VERSION ""

NS_ :

BS_:

BU_: WRCS SRS LECM1 ECUspare6 CIOM CCM

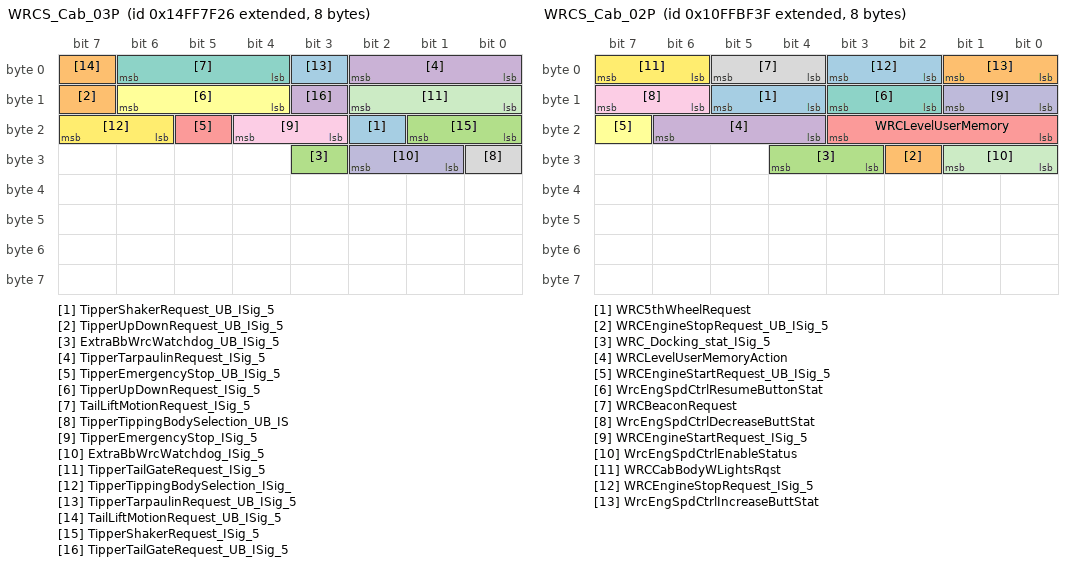
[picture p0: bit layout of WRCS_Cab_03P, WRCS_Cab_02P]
BO_ 2499772198 WRCS_Cab_03P: 8 WRCS
 SG_ TipperShakerRequest_UB_ISig_5 : 18|1@1+ (1,0) [0|0] ""  CIOM
 SG_ TipperUpDownRequest_UB_ISig_5 : 15|1@1+ (1,0) [0|0] ""  CIOM
 SG_ ExtraBbWrcWatchdog_UB_ISig_5 : 27|1@1+ (1,0) [0|0] ""  CIOM
 SG_ TipperTarpaulinRequest_ISig_5 : 0|3@1+ (1,0) [0|0] ""  CIOM
 SG_ TipperEmergencyStop_UB_ISig_5 : 21|1@1+ (1,0) [0|0] ""  CIOM
 SG_ TipperUpDownRequest_ISig_5 : 12|3@1+ (1,0) [0|0] ""  CIOM
 SG_ TailLiftMotionRequest_ISig_5 : 4|3@1+ (1,0) [0|0] ""  CIOM
 SG_ TipperTippingBodySelection_UB_IS : 24|1@1+ (1,0) [0|0] ""  CIOM
 SG_ TipperEmergencyStop_ISig_5 : 19|2@1+ (1,0) [0|0] ""  CIOM
 SG_ ExtraBbWrcWatchdog_ISig_5 : 25|2@1+ (1,0) [0|0] ""  CIOM
 SG_ TipperTailGateRequest_ISig_5 : 8|3@1+ (1,0) [0|0] ""  CIOM
 SG_ TipperTippingBodySelection_ISig_ : 22|2@1+ (1,0) [0|0] ""  CIOM
 SG_ TipperTarpaulinRequest_UB_ISig_5 : 3|1@1+ (1,0) [0|0] ""  CIOM
 SG_ TailLiftMotionRequest_UB_ISig_5 : 7|1@1+ (1,0) [0|0] ""  CIOM
 SG_ TipperShakerRequest_ISig_5 : 16|2@1+ (1,0) [0|0] ""  CIOM
 SG_ TipperTailGateRequest_UB_ISig_5 : 11|1@1+ (1,0) [0|0] ""  CIOM

BO_ 2432679743 WRCS_Cab_02P: 8 WRCS
 SG_ WRC5thWheelRequest : 12|2@1+ (1,0) [0|0] ""  CIOM
 SG_ WRCEngineStopRequest_UB_ISig_5 : 26|1@1+ (1,0) [0|0] ""  CIOM
 SG_ WRC_Docking_stat_ISig_5 : 27|2@1+ (1,0) [0|0] ""  CIOM
 SG_ WRCLevelUserMemoryAction : 20|3@1+ (1,0) [0|0] ""  CIOM
 SG_ WRCLevelUserMemory : 16|4@1+ (1,0) [0|0] ""  CIOM
 SG_ WRCEngineStartRequest_UB_ISig_5 : 23|1@1+ (1,0) [0|0] ""  CIOM
 SG_ WrcEngSpdCtrlResumeButtonStat : 10|2@1+ (1,0) [0|0] ""  CIOM
 SG_ WRCBeaconRequest : 4|2@1+ (1,0) [0|0] ""  CIOM
 SG_ WrcEngSpdCtrlDecreaseButtStat : 14|2@1+ (1,0) [0|0] ""  CIOM
 SG_ WRCEngineStartRequest_ISig_5 : 8|2@1+ (1,0) [0|0] ""  CIOM
 SG_ WrcEngSpdCtrlEnableStatus : 24|2@1+ (1,0) [0|0] ""  CIOM
 SG_ WRCCabBodyWLightsRqst : 6|2@1+ (1,0) [0|0] ""  CIOM
 SG_ WRCEngineStopRequest_ISig_5 : 2|2@1+ (1,0) [0|0] ""  CIOM
 SG_ WrcEngSpdCtrlIncreaseButtStat : 0|2@1+ (1,0) [0|0] ""  CIOM

BO_ 2365554559 WRCS_Cab_01P: 8 WRCS
 SG_ WrcPto1ButtonStatus : 2|2@1+ (1,0) [0|0] ""  CIOM
 SG_ ECSStandByReqWRC : 35|3@1+ (1,0) [0|0] ""  CIOM
 SG_ WRCCraneRequest : 22|2@1+ (1,0) [0|0] ""  CIOM
 SG_ WRCUnlockButtonStatus : 4|2@1+ (1,0) [0|0] ""  CIOM
 SG_ WRCRollRequest : 32|3@1+ (1,0) [0|0] ""  CIOM
 SG_ WRCAux3Request : 14|2@1+ (1,0) [0|0] ""  CIOM
 SG_ WRCAux2Request : 0|2@1+ (1,0) [0|0] ""  CIOM
 SG_ WrcPto3ButtonStatus : 20|2@1+ (1,0) [0|0] ""  CIOM
 SG_ WRCLevelAdjustmentAction : 44|4@1+ (1,0) [0|0] ""  CIOM
 SG_ WRCAux4Request : 10|2@1+ (1,0) [0|0] ""  CIOM
 SG_ WRCAux5Request : 8|2@1+ (1,0) [0|0] ""  CIOM
 SG_ WRCAux6Request : 16|2@1+ (1,0) [0|0] ""  CIOM
 SG_ WRCSideReverseWorkingRequest : 6|2@1+ (1,0) [0|0] ""  CIOM
 SG_ WrcPto2ButtonStatus : 12|2@1+ (1,0) [0|0] ""  CIOM
 SG_ WRCTailLiftRequest : 24|2@1+ (1,0) [0|0] ""  CIOM
 SG_ WrcPto4ButtonStatus : 30|2@1+ (1,0) [0|0] ""  CIOM
 SG_ WRCLevelAdjustmentStroke : 41|3@1+ (1,0) [0|0] ""  CIOM
 SG_ WRCLevelAdjustmentAxles : 38|3@1+ (1,0) [0|0] ""  CIOM
 SG_ WRCAirSuspensionStopRequest : 28|2@1+ (1,0) [0|0] ""  CIOM
 SG_ WRCAux1Request : 26|2@1+ (1,0) [0|0] ""  CIOM
 SG_ WRCLockButtonStatus : 18|2@1+ (1,0) [0|0] ""  CIOM

BO_ 2671902706 TesterFuncDiagMsg_Cab: 8 CIOM
 SG_ FuncDiagDataTester_ISig_5 : 0|64@1+ (1,0) [0|0] ""  SRS,CCM,LECM1,WRCS

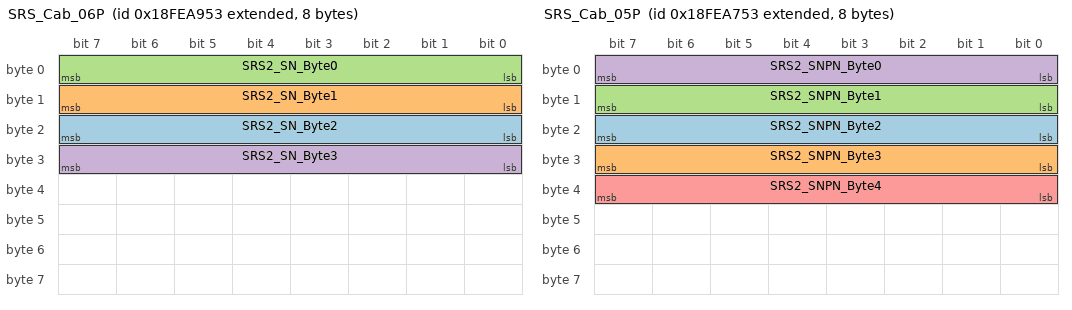
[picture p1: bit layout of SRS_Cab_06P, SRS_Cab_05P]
BO_ 2566826323 SRS_Cab_06P: 8 SRS
 SG_ SRS2_SN_Byte2 : 16|8@1+ (1,0) [0|0] ""  CIOM
 SG_ SRS2_SN_Byte1 : 8|8@1+ (1,0) [0|0] ""  CIOM
 SG_ SRS2_SN_Byte0 : 0|8@1+ (1,0) [0|0] ""  CIOM
 SG_ SRS2_SN_Byte3 : 24|8@1+ (1,0) [0|0] ""  CIOM

BO_ 2566825811 SRS_Cab_05P: 8 SRS
 SG_ SRS2_SNPN_Byte2 : 16|8@1+ (1,0) [0|0] ""  CIOM
 SG_ SRS2_SNPN_Byte3 : 24|8@1+ (1,0) [0|0] ""  CIOM
 SG_ SRS2_SNPN_Byte1 : 8|8@1+ (1,0) [0|0] ""  CIOM
 SG_ SRS2_SNPN_Byte0 : 0|8@1+ (1,0) [0|0] ""  CIOM
 SG_ SRS2_SNPN_Byte4 : 32|8@1+ (1,0) [0|0] ""  CIOM

BO_ 2516232019 SRS_Cab_04P: 8 SRS
 SG_ DiagInfoSRS2 : 0|7@1+ (1,0) [0|127] "NotApplicable"  CIOM

BO_ 2499788607 SRS_Cab_03P: 8 SRS
 SG_ ECUVIN_rqst : 0|1@1+ (1,0) [0|0] ""  CIOM

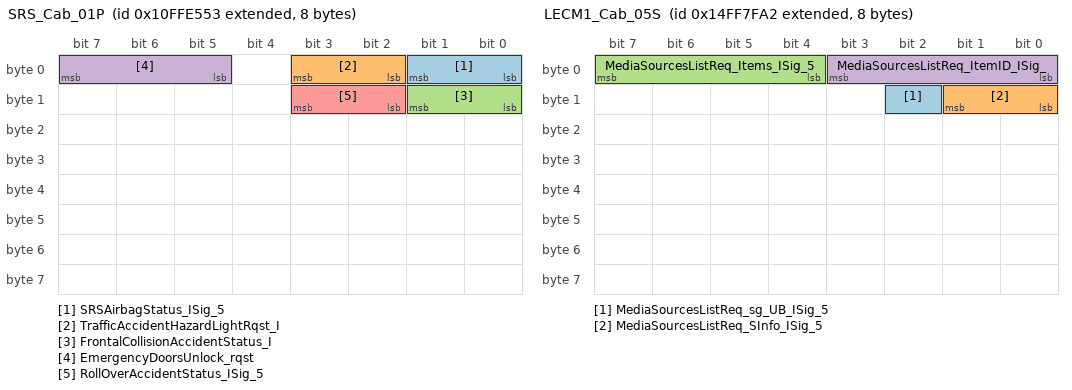
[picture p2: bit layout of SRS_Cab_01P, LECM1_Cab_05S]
BO_ 2432689491 SRS_Cab_01P: 8 SRS
 SG_ SRSAirbagStatus_ISig_5 : 0|2@1+ (1,0) [0|0] ""  CIOM
 SG_ TrafficAccidentHazardLightRqst_I : 2|2@1+ (1,0) [0|0] ""  CIOM
 SG_ FrontalCollisionAccidentStatus_I : 8|2@1+ (1,0) [0|0] ""  CIOM
 SG_ EmergencyDoorsUnlock_rqst : 5|3@1+ (1,0) [0|0] ""  CIOM
 SG_ RollOverAccidentStatus_ISig_5 : 10|2@1+ (1,0) [0|0] ""  CIOM

BO_ 2658975757 SRSDiagPSTesterTx4_Cab: 8 SRS
 SG_ SRSDiagPSTesterTx4 : 0|64@1+ (1,0) [0|0] "" Vector__XXX

BO_ 2658975756 SRSDiagPSTesterTx3_Cab: 8 SRS
 SG_ SRSDiagPSTesterTx3 : 0|64@1+ (1,0) [0|0] "" Vector__XXX

BO_ 2658975755 SRSDiagPSTesterTx2_Cab: 8 SRS
 SG_ SRSDiagPSTesterTx2 : 0|64@1+ (1,0) [0|0] "" Vector__XXX

BO_ 2658967560 SRSDiagPSTesterTx1_Cab: 8 SRS
 SG_ SRSDiagPSTesterTx1 : 0|64@1+ (1,0) [0|0] "" Vector__XXX

BO_ 2658967559 SRSDiagPSTesterRx1_Cab: 8 Vector__XXX
 SG_ SRSDiagPSTesterRx1 : 0|64@1+ (1,0) [0|0] ""  SRS

BO_ 2671833762 PhysDiagRespMsg_F2_A2_Cab: 8 LECM1
 SG_ PhysDiagRespSig_F2_A2_ISig_5 : 0|64@1+ (1,0) [0|0] ""  CIOM

BO_ 2671833752 PhysDiagRespMsg_F2_98_Cab: 8 CCM
 SG_ PhysDiagRespSig_F2_98_ISig_5 : 0|64@1+ (1,0) [0|0] ""  CIOM

BO_ 2671833683 PhysDiagRespMsg_F2_53_Cab: 8 SRS
 SG_ PhysDiagRespSig_F2_53_ISig_5 : 0|64@1+ (1,0) [0|0] ""  CIOM

BO_ 2671833638 PhysDiagRespMsg_F2_26_Cab: 8 WRCS
 SG_ PhysDiagRespSig_F2_26_ISig_5 : 0|64@1+ (1,0) [0|0] ""  CIOM

BO_ 2564485459 PhysDiagRespMsg_F1_53_Cab: 8 SRS
 SG_ PhysDiagRespSig_F1_53_ISig_5 : 0|64@1+ (1,0) [0|0] ""  CIOM

BO_ 2671813362 PhysDiagReqMsg_A2_F2_Cab: 8 CIOM
 SG_ PhysDiagReqSig_A2_F2_ISig_5 : 0|64@1+ (1,0) [0|0] ""  LECM1

BO_ 2671810802 PhysDiagReqMsg_98_F2_Cab: 8 CIOM
 SG_ PhysDiagReqSig_98_F2_ISig_5 : 0|64@1+ (1,0) [0|0] ""  CCM

BO_ 2671793138 PhysDiagReqMsg_53_F2_Cab: 8 CIOM
 SG_ PhysDiagReqSig_53_F2_ISig_5 : 0|64@1+ (1,0) [0|0] ""  SRS

BO_ 2564445169 PhysDiagReqMsg_53_F1_Cab: 8 CIOM
 SG_ PhysDiagReqSig_53_F1_ISig_5 : 0|64@1+ (1,0) [0|0] ""  SRS

BO_ 2671781618 PhysDiagReqMsg_26_F2_Cab: 8 CIOM
 SG_ PhysDiagReqSig_26_F2_ISig_5 : 0|64@1+ (1,0) [0|0] ""  WRCS

BO_ 2633990182 NmAsr_WRCS_Cab: 1 WRCS

BO_ 2633990227 NmAsr_SRS_Cab: 1 SRS

BO_ 2633990306 NmAsr_LECM1_Cab: 1 LECM1

BO_ 2633990208 NmAsr_CIOM_Cab: 1 CIOM

BO_ 2633990296 NmAsr_CCM_Cab: 1 CCM

BO_ 2499772322 LECM1_Cab_05S: 8 LECM1
 SG_ MediaSourcesListReq_sg_UB_ISig_5 : 10|1@1+ (1,0) [0|0] ""  CIOM
 SG_ MediaSourcesListReq_SInfo_ISig_5 : 8|2@1+ (1,0) [0|0] ""  CIOM
 SG_ MediaSourcesListReq_Items_ISig_5 : 4|4@1+ (1,0) [0|0] ""  CIOM
 SG_ MediaSourcesListReq_ItemID_ISig_ : 0|4@1+ (1,0) [0|0] ""  CIOM

BO_ 2489730210 LECM1_Cab_04P: 8 LECM1
 SG_ BunkH1AudioSrcSem_rqst_ISig_5 : 0|4@1+ (1,0) [0|0] ""  CIOM

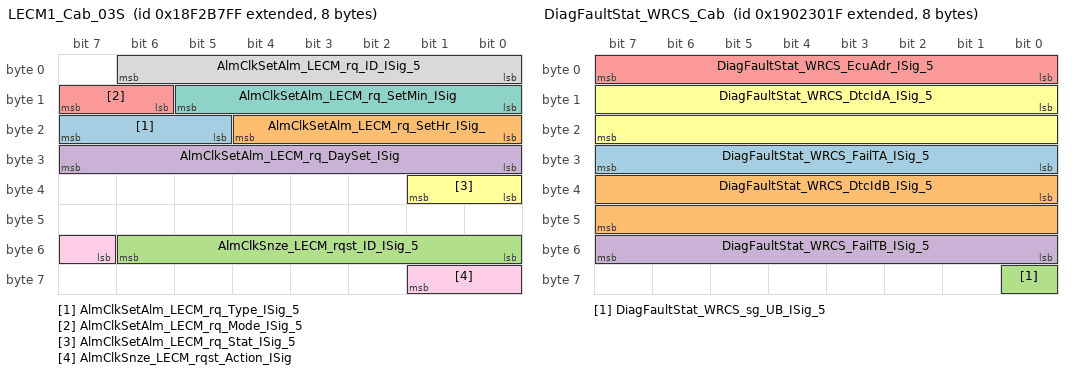
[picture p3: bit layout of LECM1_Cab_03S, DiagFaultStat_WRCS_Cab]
BO_ 2566043647 LECM1_Cab_03S: 8 LECM1
 SG_ AlmClkSetAlm_LECM_rq_Type_ISig_5 : 21|3@1+ (1,0) [0|0] ""  CIOM
 SG_ AlmClkSetAlm_LECM_rq_SetHr_ISig_ : 16|5@1+ (1,0) [0|31] "h"  CIOM
 SG_ AlmClkSnze_LECM_rqst_ID_ISig_5 : 48|7@1+ (1,0) [0|0] ""  CIOM
 SG_ AlmClkSetAlm_LECM_rq_DaySet_ISig : 24|8@1+ (1,0) [0|255] ""  CIOM
 SG_ AlmClkSetAlm_LECM_rq_Mode_ISig_5 : 14|2@1+ (1,0) [0|0] ""  CIOM
 SG_ AlmClkSetAlm_LECM_rq_Stat_ISig_5 : 32|2@1+ (1,0) [0|0] ""  CIOM
 SG_ AlmClkSetAlm_LECM_rq_SetMin_ISig : 8|6@1+ (1,0) [0|63] "min"  CIOM
 SG_ AlmClkSetAlm_LECM_rq_ID_ISig_5 : 0|7@1+ (1,0) [0|0] ""  CIOM
 SG_ AlmClkSnze_LECM_rqst_Action_ISig : 55|3@1+ (1,0) [0|0] ""  CIOM

BO_ 2432693154 LECM1_Cab_02P: 8 LECM1
 SG_ BunkH1PowerWinOpenDSBtn_stat_UB_ : 58|1@1+ (1,0) [0|0] ""  CIOM
 SG_ BunkH1RoofhatchOpenBtn_Stat : 32|2@1+ (1,0) [0|0] ""  CIOM
 SG_ BunkH1IntLghtActvnBtn_stat : 6|2@1+ (1,0) [0|0] ""  CIOM
 SG_ BunkH1TempDec_ButtonStatus : 24|2@1+ (1,0) [0|0] ""  CCM
 SG_ BunkH1IntLghtDirAccsUpBtn_stat : 46|2@1+ (1,0) [0|0] ""  CIOM
 SG_ BunkH1AudioSource_rqst2_ISig_5 : 60|4@1+ (1,0) [0|0] ""  CIOM
 SG_ BunkH1AudioOnOff_ButtonStatus_IS : 2|2@1+ (1,0) [0|0] ""  CIOM
 SG_ BunkH1RoofhatchCloseBtn_Stat : 28|2@1+ (1,0) [0|0] ""  CIOM
 SG_ BunkH1VolumeUp_ButtonStatus_ISig : 30|2@1+ (1,0) [0|0] ""  CIOM
 SG_ BunkH1PowerWinClosePSBtn_stat_UB : 55|1@1+ (1,0) [0|0] ""  CIOM
 SG_ BunkH1PowerWinCloseDSBtn_stat_IS : 16|2@1+ (1,0) [0|0] ""  CIOM
 SG_ BunkH1Prev_ButtonStatus_ISig_5 : 0|2@1+ (1,0) [0|0] ""  CIOM
 SG_ BunkH1UnlockButtonStatus : 4|2@1+ (1,0) [0|0] ""  CIOM
 SG_ BunkH1VolumeDown_ButtonStatus_IS : 18|2@1+ (1,0) [0|0] ""  CIOM
 SG_ BunkH1ParkHeaterTimer2_cmd : 40|3@1+ (1,0) [0|0] ""  CCM
 SG_ BunkH1PowerWinOpenPSBtn_stat_UB_ : 59|1@1+ (1,0) [0|0] ""  CIOM
 SG_ BunkH1PowerWinOpenDSBtn_stat_ISi : 8|2@1+ (1,0) [0|0] ""  CIOM
 SG_ BunkH1ParkHeater_ButtonStatus : 14|2@1+ (1,0) [0|0] ""  CCM
 SG_ BunkH1ParkHeaterTimer3_cmd : 36|3@1+ (1,0) [0|0] ""  CCM
 SG_ BunkH1AudioSource_rqst_ISig_5 : 48|3@1+ (1,0) [0|0] ""  CIOM
 SG_ BunkH1Mute_ButtonStatus_ISig_5 : 56|2@1+ (1,0) [0|0] ""  CIOM
 SG_ BunkH1IntLghtDirAccsDnBtn_stat : 22|2@1+ (1,0) [0|0] ""  CIOM
 SG_ BunkH1LockButtonStatus : 10|2@1+ (1,0) [0|0] ""  CIOM
 SG_ BunkH1ParkHeaterTimer1_cmd : 43|3@1+ (1,0) [0|0] ""  CCM
 SG_ BnkH1IntLghtMMenu_stat_IL_Mode : 51|3@1+ (1,0) [0|0] ""  CIOM
 SG_ BunkH1Next_ButtonStatus_ISig_5 : 20|2@1+ (1,0) [0|0] ""  CIOM
 SG_ BunkH1PowerWinCloseDSBtn_stat_UB : 39|1@1+ (1,0) [0|0] ""  CIOM
 SG_ BnkH1IntLghtMMenu_stat_EventFlag : 54|1@1+ (1,0) [0|0] ""  CIOM
 SG_ BunkH1PowerWinOpenPSBtn_stat_ISi : 26|2@1+ (1,0) [0|0] ""  CIOM
 SG_ BunkH1PowerWinClosePSBtn_stat_IS : 34|2@1+ (1,0) [0|0] ""  CIOM
 SG_ BunkH1TempInc_ButtonStatus : 12|2@1+ (1,0) [0|0] ""  CCM

BO_ 2671902708 IntTesterTGW2FuncDiagMsg_Cab: 8 CIOM
 SG_ FuncDiagDataIntTesterTGW2_ISig_5 : 0|64@1+ (1,0) [0|0] ""  LECM1,SRS,CCM,WRCS

BO_ 2671964834 DiagUUDTRespMsg1_F2_A2_Cab: 8 LECM1
 SG_ DiagUUDTRespSig_F2_A2_ISig_5 : 0|64@1+ (1,0) [0|0] ""  CIOM

BO_ 2671964824 DiagUUDTRespMsg1_F2_98_Cab: 8 CCM
 SG_ DiagUUDTRespSig_F2_98_ISig_5 : 0|64@1+ (1,0) [0|0] ""  CIOM

BO_ 2671964755 DiagUUDTRespMsg1_F2_53_Cab: 8 SRS
 SG_ DiagUUDTRespSig_F2_53_ISig_5 : 0|64@1+ (1,0) [0|0] ""  CIOM

BO_ 2671964710 DiagUUDTRespMsg1_F2_26_Cab: 8 WRCS
 SG_ DiagUUDTRespSig_F2_26_ISig_5 : 0|64@1+ (1,0) [0|0] ""  CIOM

BO_ 2671834274 DiagRespMsgIntTGW2_F4_A2_Cab: 8 LECM1
 SG_ InternalTesterDiagSig_F4_A2_ISig : 0|64@1+ (1,0) [0|0] ""  CIOM

BO_ 2671834264 DiagRespMsgIntTGW2_F4_98_Cab: 8 CCM
 SG_ InternalTesterDiagSig_F4_98_ISig : 0|64@1+ (1,0) [0|0] ""  CIOM

BO_ 2671834195 DiagRespMsgIntTGW2_F4_53_Cab: 8 SRS
 SG_ InternalTesterDiagSig_F4_53_ISig : 0|64@1+ (1,0) [0|0] ""  CIOM

BO_ 2671834150 DiagRespMsgIntTGW2_F4_26_Cab: 8 WRCS
 SG_ InternalTesterDiagSig_F4_26_ISig : 0|64@1+ (1,0) [0|0] ""  CIOM

BO_ 2671834018 DiagRespMsgIntHMIIOM_F3_A2_Cab: 8 LECM1
 SG_ InternalTesterDiagSig_F3_A2_ISig : 0|64@1+ (1,0) [0|0] ""  CIOM

BO_ 2671834008 DiagRespMsgIntHMIIOM_F3_98_Cab: 8 CCM
 SG_ InternalTesterDiagSig_F3_98_ISig : 0|64@1+ (1,0) [0|0] ""  CIOM

BO_ 2671833939 DiagRespMsgIntHMIIOM_F3_53_Cab: 8 SRS
 SG_ InternalTesterDiagSig_F3_53_ISig : 0|64@1+ (1,0) [0|0] ""  CIOM

BO_ 2671833894 DiagRespMsgIntHMIIOM_F3_26_Cab: 8 WRCS
 SG_ InternalTesterDiagSig_F3_26_ISig : 0|64@1+ (1,0) [0|0] ""  CIOM

BO_ 2671813364 DiagReqMsgIntTGW2_A2_F4_Cab: 8 CIOM
 SG_ InternalTesterDiagSig_A2_F4_ISig : 0|64@1+ (1,0) [0|0] ""  LECM1

BO_ 2671810804 DiagReqMsgIntTGW2_98_F4_Cab: 8 CIOM
 SG_ InternalTesterDiagSig_98_F4_ISig : 0|64@1+ (1,0) [0|0] ""  CCM

BO_ 2671793140 DiagReqMsgIntTGW2_53_F4_Cab: 8 CIOM
 SG_ InternalTesterDiagSig_53_F4_ISig : 0|64@1+ (1,0) [0|0] ""  SRS

BO_ 2671781620 DiagReqMsgIntTGW2_26_F4_Cab: 8 CIOM
 SG_ InternalTesterDiagSig_26_F4_ISig : 0|64@1+ (1,0) [0|0] ""  WRCS

BO_ 2671813363 DiagReqMsgIntHMIIOM_A2_F3_Cab: 8 CIOM
 SG_ InternalTesterDiagSig_A2_F3_ISig : 0|64@1+ (1,0) [0|0] ""  LECM1

BO_ 2671810803 DiagReqMsgIntHMIIOM_98_F3_Cab: 8 CIOM
 SG_ InternalTesterDiagSig_98_F3_ISig : 0|64@1+ (1,0) [0|0] ""  CCM

BO_ 2671793139 DiagReqMsgIntHMIIOM_53_F3_Cab: 8 CIOM
 SG_ InternalTesterDiagSig_53_F3_ISig : 0|64@1+ (1,0) [0|0] ""  SRS

BO_ 2671781619 DiagReqMsgIntHMIIOM_26_F3_Cab: 8 CIOM
 SG_ InternalTesterDiagSig_26_F3_ISig : 0|64@1+ (1,0) [0|0] ""  WRCS

BO_ 2567057439 DiagFaultStat_WRCS_Cab: 8 WRCS
 SG_ DiagFaultStat_WRCS_FailTA_ISig_5 : 24|8@1+ (1,0) [0|255] ""  CIOM
 SG_ DiagFaultStat_WRCS_DtcIdB_ISig_5 : 32|16@1+ (1,0) [0|65535] ""  CIOM
 SG_ DiagFaultStat_WRCS_sg_UB_ISig_5 : 56|1@1+ (1,0) [0|0] ""  CIOM
 SG_ DiagFaultStat_WRCS_FailTB_ISig_5 : 48|8@1+ (1,0) [0|255] ""  CIOM
 SG_ DiagFaultStat_WRCS_EcuAdr_ISig_5 : 0|8@1+ (1,0) [0|255] ""  CIOM
 SG_ DiagFaultStat_WRCS_DtcIdA_ISig_5 : 8|16@1+ (1,0) [0|65535] ""  CIOM

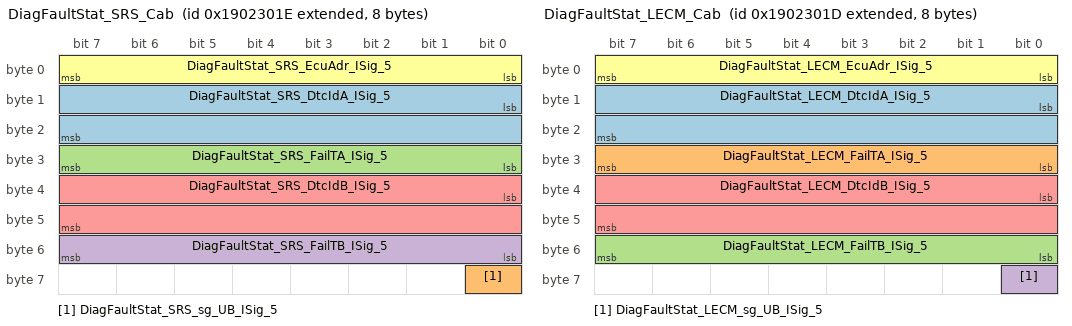
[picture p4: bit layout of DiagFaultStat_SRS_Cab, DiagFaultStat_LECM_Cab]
BO_ 2567057438 DiagFaultStat_SRS_Cab: 8 SRS
 SG_ DiagFaultStat_SRS_DtcIdA_ISig_5 : 8|16@1+ (1,0) [0|65535] ""  CIOM
 SG_ DiagFaultStat_SRS_sg_UB_ISig_5 : 56|1@1+ (1,0) [0|0] ""  CIOM
 SG_ DiagFaultStat_SRS_FailTA_ISig_5 : 24|8@1+ (1,0) [0|255] ""  CIOM
 SG_ DiagFaultStat_SRS_FailTB_ISig_5 : 48|8@1+ (1,0) [0|255] ""  CIOM
 SG_ DiagFaultStat_SRS_DtcIdB_ISig_5 : 32|16@1+ (1,0) [0|65535] ""  CIOM
 SG_ DiagFaultStat_SRS_EcuAdr_ISig_5 : 0|8@1+ (1,0) [0|255] ""  CIOM

BO_ 2567057437 DiagFaultStat_LECM_Cab: 8 LECM1
 SG_ DiagFaultStat_LECM_DtcIdA_ISig_5 : 8|16@1+ (1,0) [0|65535] ""  CIOM
 SG_ DiagFaultStat_LECM_FailTA_ISig_5 : 24|8@1+ (1,0) [0|255] ""  CIOM
 SG_ DiagFaultStat_LECM_FailTB_ISig_5 : 48|8@1+ (1,0) [0|255] ""  CIOM
 SG_ DiagFaultStat_LECM_sg_UB_ISig_5 : 56|1@1+ (1,0) [0|0] ""  CIOM
 SG_ DiagFaultStat_LECM_DtcIdB_ISig_5 : 32|16@1+ (1,0) [0|65535] ""  CIOM
 SG_ DiagFaultStat_LECM_EcuAdr_ISig_5 : 0|8@1+ (1,0) [0|255] ""  CIOM

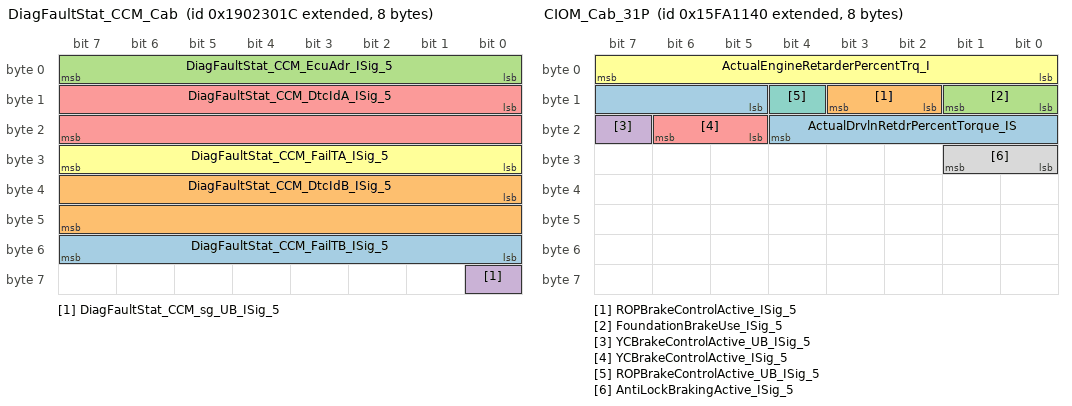
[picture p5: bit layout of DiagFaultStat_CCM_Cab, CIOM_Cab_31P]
BO_ 2567057436 DiagFaultStat_CCM_Cab: 8 CCM
 SG_ DiagFaultStat_CCM_FailTB_ISig_5 : 48|8@1+ (1,0) [0|255] ""  CIOM
 SG_ DiagFaultStat_CCM_DtcIdB_ISig_5 : 32|16@1+ (1,0) [0|65535] ""  CIOM
 SG_ DiagFaultStat_CCM_EcuAdr_ISig_5 : 0|8@1+ (1,0) [0|255] ""  CIOM
 SG_ DiagFaultStat_CCM_sg_UB_ISig_5 : 56|1@1+ (1,0) [0|0] ""  CIOM
 SG_ DiagFaultStat_CCM_DtcIdA_ISig_5 : 8|16@1+ (1,0) [0|65535] ""  CIOM
 SG_ DiagFaultStat_CCM_FailTA_ISig_5 : 24|8@1+ (1,0) [0|255] ""  CIOM

BO_ 2634020435 Debug6_SRS_Cab: 8 SRS
 SG_ Debug_6_SRS : 0|64@1+ (1,0) [0|0] "" Vector__XXX

BO_ 2634020514 Debug6_LECM_Cab: 8 LECM1
 SG_ Debug_6_LECM : 0|64@1+ (1,0) [0|0] "" Vector__XXX

BO_ 2634020504 Debug6_CCM_Cab: 8 CCM
 SG_ Debug_6_CCM : 0|64@1+ (1,0) [0|0] "" Vector__XXX

BO_ 2634020179 Debug5_SRS_Cab: 8 SRS
 SG_ Debug_5_SRS : 0|64@1+ (1,0) [0|0] "" Vector__XXX

BO_ 2634020258 Debug5_LECM_Cab: 8 LECM1
 SG_ Debug_5_LECM : 0|64@1+ (1,0) [0|0] "" Vector__XXX

BO_ 2634020248 Debug5_CCM_Cab: 8 CCM
 SG_ Debug_5_CCM : 0|64@1+ (1,0) [0|0] "" Vector__XXX

BO_ 2634019923 Debug4_SRS_Cab: 8 SRS
 SG_ Debug_4_SRS : 0|64@1+ (1,0) [0|0] "" Vector__XXX

BO_ 2634020002 Debug4_LECM_Cab: 8 LECM1
 SG_ Debug_4_LECM : 0|64@1+ (1,0) [0|0] "" Vector__XXX

BO_ 2634019992 Debug4_CCM_Cab: 8 CCM
 SG_ Debug_4_CCM : 0|64@1+ (1,0) [0|0] "" Vector__XXX

BO_ 2634019667 Debug3_SRS_Cab: 8 SRS
 SG_ Debug_3_SRS : 0|64@1+ (1,0) [0|0] "" Vector__XXX

BO_ 2634019746 Debug3_LECM_Cab: 8 LECM1
 SG_ Debug_3_LECM : 0|64@1+ (1,0) [0|0] "" Vector__XXX

BO_ 2634019736 Debug3_CCM_Cab: 8 Vector__XXX
 SG_ Debug_3_CCM : 0|64@1+ (1,0) [0|0] ""  CCM

BO_ 2634019411 Debug2_SRS_Cab: 8 SRS
 SG_ Debug_2_SRS : 0|64@1+ (1,0) [0|0] "" Vector__XXX

BO_ 2634019490 Debug2_LECM_Cab: 8 LECM1
 SG_ Debug_2_LECM : 0|64@1+ (1,0) [0|0] "" Vector__XXX

BO_ 2634019480 Debug2_CCM_Cab: 8 Vector__XXX
 SG_ Debug_2_CCM : 0|64@1+ (1,0) [0|0] ""  CCM

BO_ 2634019155 Debug1_SRS_Cab: 8 Vector__XXX
 SG_ Debug_1_SRS : 0|64@1+ (1,0) [0|0] ""  SRS

BO_ 2634019234 Debug1_LECM_Cab: 8 Vector__XXX
 SG_ Debug_1_LECM : 0|64@1+ (1,0) [0|0] ""  LECM1

BO_ 2634019224 Debug1_CCM_Cab: 8 Vector__XXX
 SG_ Debug_1_CCM : 0|64@1+ (1,0) [0|0] ""  CCM

BO_ 2566357313 CIOM_Cab_34P_FCM: 8 SRS
 SG_ CIOM_Cab_34P_FCS : 0|64@1+ (1,0) [0|0] ""  CIOM

BO_ 2566357312 CIOM_Cab_34P: 21 CIOM
 SG_ GPSData_VehSpeed_ISig_5 : 128|16@1+ (0.00390625,0) [0|255.99609375] "Km_per_h"  SRS
 SG_ GPSData_HDOP_ISig_5 : 112|16@1+ (0.01,0) [0|655.35] ""  SRS
 SG_ GPSData_Direction_ISig_5 : 96|16@1+ (0.0078125,0) [0|511.9921875] "deg"  SRS
 SG_ GPSData_Longitude_ISig_5 : 0|32@1+ (1E-007,-210) [-210|219.4967295] "deg"  SRS
 SG_ GPSData_AntennaStat_ISig_5 : 160|3@1+ (1,0) [0|0] ""  SRS
 SG_ GPSData_Latitude_ISig_5 : 32|32@1+ (1E-007,-210) [-210|219.4967295] "deg"  SRS
 SG_ GPSData_sg_UB_ISig_5 : 163|1@1+ (1,0) [0|1] ""  SRS
 SG_ GPSData_Altitude_ISig_5 : 144|16@1+ (0.125,-2500) [-2500|5691.875] "m"  SRS
 SG_ GPSData_Time_ISig_5 : 64|32@1+ (1,0) [0|4294967295] "s"  SRS

BO_ 2432680000 CIOM_Cab_33P: 8 CIOM
 SG_ BrakePedalPosition_ISig_5 : 0|8@1+ (0.4,0) [0|102] "Percent"  SRS
 SG_ SteeringWheelAngle_ISig_5 : 8|16@1+ (0.0009765625,-31.374) [-31.374|32.6250234375] "rad"  SRS

BO_ 2432647232 CIOM_Cab_32P: 8 CIOM
 SG_ CM_Status_ISig_5 : 0|3@1+ (1,0) [0|0] ""  SRS

BO_ 2516193600 CIOM_Cab_31P: 8 CIOM
 SG_ ActualDrvlnRetdrPercentTorque_IS : 13|8@1+ (1,-125) [-125|130] "Percent"  SRS
 SG_ ROPBrakeControlActive_ISig_5 : 10|2@1+ (1,0) [0|0] ""  SRS
 SG_ FoundationBrakeUse_ISig_5 : 8|2@1+ (1,0) [0|0] ""  SRS
 SG_ YCBrakeControlActive_UB_ISig_5 : 23|1@1+ (1,0) [0|0] ""  SRS
 SG_ YCBrakeControlActive_ISig_5 : 21|2@1+ (1,0) [0|0] ""  SRS
 SG_ ActualEngineRetarderPercentTrq_I : 0|8@1+ (1,-125) [-125|130] "Percent"  SRS
 SG_ ROPBrakeControlActive_UB_ISig_5 : 12|1@1+ (1,0) [0|0] ""  SRS
 SG_ AntiLockBrakingActive_ISig_5 : 24|2@1+ (1,0) [0|0] ""  SRS

BO_ 2566357057 CIOM_Cab_30S_FCM: 8 LECM1
 SG_ CIOM_Cab_30S_FCS : 0|64@1+ (1,0) [0|0] ""  CIOM

BO_ 2566357056 CIOM_Cab_30S: 36 CIOM
 SG_ SEM_DisplayText_stat_ISig_5 : 0|288@1+ (1,0) [0|0] ""  LECM1

BO_ 2432679745 CIOM_Cab_29S_FCM: 8 LECM1
 SG_ CIOM_Cab_29S_FCS : 0|64@1+ (1,0) [0|0] ""  CIOM

BO_ 2432679744 CIOM_Cab_29S: 98 CIOM
 SG_ MediaSourcesListRsp_SrcAttrib_IS : 392|384@1+ (1,0) [0|0] ""  LECM1
 SG_ MediaSourcesListRsp_ItemID_ISig_ : 776|4@1+ (1,0) [0|0] ""  LECM1
 SG_ MediaSourcesListRsp_Name_ISig_5 : 8|384@1+ (1,0) [0|0] ""  LECM1
 SG_ MediaSourcesListRsp_SInfo_ISig_5 : 780|2@1+ (1,0) [0|0] ""  LECM1
 SG_ MediaSourcesListRsp_PCI_ISig_5 : 0|8@1+ (1,0) [0|255] ""  LECM1
 SG_ MediaSourcesListRsp_sg_UB_ISig_5 : 782|1@1+ (1,0) [0|0] ""  LECM1

BO_ 2432646976 CIOM_Cab_28S: 8 CIOM
 SG_ MediaSourcesListNPRsp_ISig_5 : 0|8@1+ (1,0) [0|255] ""  LECM1
 SG_ MediaSourcesListNPRsp_UB_ISig_5 : 8|1@1+ (1,0) [0|0] ""  LECM1

BO_ 2493989952 CIOM_Cab_27P: 8 CIOM
 SG_ SEMMediaSourceAvail_Source07_ISi : 7|1@1+ (1,0) [0|0] ""  LECM1
 SG_ SEMMediaSourceAvail_Source06_ISi : 6|1@1+ (1,0) [0|0] ""  LECM1
 SG_ SEMMediaSourceAvail_Source08_ISi : 8|1@1+ (1,0) [0|0] ""  LECM1
 SG_ SEMMediaSourceAvail_Source00_ISi : 0|1@1+ (1,0) [0|0] ""  LECM1
 SG_ SEM_AudioMuteStat_ISig_5 : 20|3@1+ (1,0) [0|0] ""  LECM1
 SG_ SEMMediaSourceAvail_Source09_ISi : 9|1@1+ (1,0) [0|0] ""  LECM1
 SG_ SEMMediaSourceAvail_Source13_ISi : 13|1@1+ (1,0) [0|0] ""  LECM1
 SG_ SEMMediaSourceAvail_Source04_ISi : 4|1@1+ (1,0) [0|0] ""  LECM1
 SG_ SEMMediaSourceAvail_Source05_ISi : 5|1@1+ (1,0) [0|0] ""  LECM1
 SG_ SEMMediaSourceAvail_Source02_ISi : 2|1@1+ (1,0) [0|0] ""  LECM1
 SG_ SEMMediaSourceAvail_SInfo_ISig_5 : 14|2@1+ (1,0) [0|0] ""  LECM1
 SG_ AudioSourceStat_ISig_5 : 16|4@1+ (1,0) [0|0] ""  LECM1
 SG_ SEMMediaSourceAvail_Source11_ISi : 11|1@1+ (1,0) [0|0] ""  LECM1
 SG_ SEMMediaSourceAvail_Source10_ISi : 10|1@1+ (1,0) [0|0] ""  LECM1
 SG_ SEM_AudioVolValIndCmd_ISig_5 : 23|6@1+ (1,0) [0|63] "Step"  LECM1
 SG_ SEMMediaSourceAvail_Source01_ISi : 1|1@1+ (1,0) [0|0] ""  LECM1
 SG_ SEMMediaSourceAvail_Source03_ISi : 3|1@1+ (1,0) [0|0] ""  LECM1
 SG_ SEM_PresetIndicationCmd_ISig_5 : 29|6@1+ (1,0) [0|63] "Enumeration"  LECM1
 SG_ SEMMediaSourceAvail_Source12_ISi : 12|1@1+ (1,0) [0|0] ""  LECM1

BO_ 2499754560 CIOM_Cab_26P: 8 CIOM
 SG_ TipperEmergencyStopStatus_ISig_5 : 36|3@1+ (1,0) [0|0] ""  WRCS
 SG_ TipperPrimaryBodyStatus_ISig_5 : 40|3@1+ (1,0) [0|0] ""  WRCS
 SG_ TipperConditionsStatus_ISig_5 : 2|2@1+ (1,0) [0|0] ""  WRCS
 SG_ TipperSecondaryBodyStatus_ISig_5 : 43|3@1+ (1,0) [0|0] ""  WRCS
 SG_ BatterySOCAlert_rqst_ISig_5 : 48|3@1+ (1,0) [0|0] ""  WRCS
 SG_ CCStates_ISig_5 : 54|4@1+ (1,0) [0|0] ""  SRS
 SG_ LongMotionDirection_ISig_5 : 51|3@1+ (1,0) [0|0] ""  SRS
 SG_ TipperUpDownStatus_ISig_5 : 10|3@1+ (1,0) [0|0] ""  WRCS
 SG_ TipperTailGateStatus_ISig_5 : 13|3@1+ (1,0) [0|0] ""  WRCS
 SG_ KneelingInformation_ISig_5 : 32|4@1+ (1,0) [0|0] ""  WRCS
 SG_ TailLiftRemoteNotAllowed_ISig_5 : 6|2@1+ (1,0) [0|0] ""  WRCS
 SG_ TipperTarpaulinStatus_ISig_5 : 16|3@1+ (1,0) [0|0] ""  WRCS
 SG_ TailLiftConditionsStatus_ISig_5 : 4|2@1+ (1,0) [0|0] ""  WRCS
 SG_ InhibitWRCECSMenuCmd : 8|2@1+ (1,0) [0|0] ""  WRCS
 SG_ ExtraHeating_rqst_ISig_5 : 27|3@1+ (1,0) [0|0] ""  CCM
 SG_ ShortStopHeater_status_ISig_5 : 24|3@1+ (1,0) [0|0] ""  CCM
 SG_ LongMotionDirectionQual_ISig_5 : 22|2@1+ (1,0) [0|0] ""  SRS
 SG_ TipperShakerStatus_ISig_5 : 0|2@1+ (1,0) [0|0] ""  WRCS
 SG_ TailLiftMotionStatus_ISig_5 : 19|3@1+ (1,0) [0|0] ""  WRCS

BO_ 2566356801 CIOM_Cab_25S_FCM: 8 CCM
 SG_ CIOM_Cab_25S_FCS : 0|64@1+ (1,0) [0|0] ""  CIOM

CM_ "COM_MATRIX_1.31.X0";
CM_ SG_ 2566043647 AlmClkSetAlm_LECM_rq_SetHr_ISig_ "30 Error ; 31 Not Available";
CM_ SG_ 2566043647 AlmClkSetAlm_LECM_rq_SetMin_ISig "62 Error ; 63 Not Available";
CM_ SG_ 2566357312 GPSData_VehSpeed_ISig_5 "65024 - 65279 Error ; 65280 - 65535 Not available";
CM_ SG_ 2566357312 GPSData_Longitude_ISig_5 "4261412864-4278190079 Error ; 4278190080-4294967295 Not available";
CM_ SG_ 2566357312 GPSData_Latitude_ISig_5 "4261412864-4278190079 Error ; 4278190080-4294967295 Not available";
CM_ SG_ 2566357312 GPSData_Time_ISig_5 "4261412864 - 4278190079 Error ; 4278190080 - 4294967295 Not available";
CM_ SG_ 2432680000 BrakePedalPosition_ISig_5 "254 Error ; 255 Not available";
CM_ SG_ 2432680000 SteeringWheelAngle_ISig_5 "65024 - 65279 Error ; 65280 - 65535 Not available";
CM_ SG_ 2516193600 ActualDrvlnRetdrPercentTorque_IS "254 Error ; 255 Not available";
CM_ SG_ 2516193600 ActualEngineRetarderPercentTrq_I "254 Error ; 255 Not available";
BA_DEF_ BO_  "GenMsgStartDelayTime" INT 0 0;
BA_DEF_ BO_  "GenMsgDelayTime" INT 0 0;
BA_DEF_ BO_  "GenMsgCycleTime" INT 0 0;
BA_DEF_ BO_  "GenMsgSendType" ENUM  "Cyclic","NotUsed","NotUsed","NotUsed","NotUsed","NotUsed","NotUsed","IfActive","NoMsgSendType","NotUsed";
BA_DEF_ SG_  "GenSigStartValue" INT 0 0;
BA_DEF_ SG_  "GenSigCycleTimeActive" INT 0 0;
BA_DEF_ SG_  "GenSigCycleTime" INT 0 0;
BA_DEF_ SG_  "GenSigSendType" ENUM  "Cyclic","OnWrite","OnWriteWithRepetition","OnChange","OnChangeWithRepetition","IfActive","IfActiveWithRepetition","NoSigSendType","NotUsed","NotUsed","NotUsed","NotUsed","NotUsed";
BA_DEF_  "Baudrate" INT 0 1000000;
BA_DEF_  "BusType" STRING ;
BA_DEF_  "NmType" STRING ;
BA_DEF_  "Manufacturer" STRING ;
BA_DEF_  "VersionYear" INT 0 99;
BA_DEF_  "VersionNumber" INT 0 99;
BA_DEF_  "VersionMonth" INT 1 12;
BA_DEF_  "VersionDay" INT 1 31;
BA_DEF_ BO_  "VFrameFormat" ENUM  "StandardCAN","ExtendedCAN","reserved","J1939PG";
BA_DEF_ BU_  "TpOwnSystemEcuNumber" HEX 0 255;
BA_DEF_ SG_  "SigType" ENUM  "Default","Range","RangeSigned","ASCII","Discrete","Control","ReferencePGN","DTC","StringDelimiter","StringLength","StringLengthControl";
BA_DEF_ SG_  "SeToolVersion_SIGNAL" STRING ;
BA_DEF_ SG_  "SeToolUniqueID_SIGNAL" STRING ;
BA_DEF_ SG_  "SeToolOwnerSigGroup_SIGNAL" STRING ;
BA_DEF_ SG_  "SeToolOwnerSigGroupID_SIGNAL" STRING ;
BA_DEF_ SG_  "SeToolName_SIGNAL" STRING ;
BA_DEF_ SG_  "SeToolItemID_SIGNAL" STRING ;
BA_DEF_ SG_  "SeToolAncestorID_SIGNAL" STRING ;
BA_DEF_ BU_  "NmStationAddress" INT 0 255;
BA_DEF_  "NmAsrWaitBusSleepTime" INT 0 65535;
BA_DEF_  "NmAsrTimeoutTime" INT 0 65535;
BA_DEF_  "NmAsrRepeatMessageTime" INT 0 65535;
BA_DEF_ BU_  "NmAsrNodeIdentifier" HEX 0 253;
BA_DEF_ BU_  "NmAsrNode" ENUM  "No","Yes";
BA_DEF_  "NmAsrMessageCount" INT 1 256;
BA_DEF_ BO_  "NmAsrMessage" ENUM  "No","Yes";
BA_DEF_  "NmAsrCanMsgCycleTime" INT 0 65535;
BA_DEF_  "NmAsrBaseAddress" HEX 0 536870911;
BA_DEF_ SG_  "NeedsUpdateBit" ENUM  "No","Yes";
BA_DEF_ SG_  "MmAnSignal" ENUM  "No","Yes";
BA_DEF_ SG_  "GenSigMaxLatency" INT 0 65535;
BA_DEF_ SG_  "GenSigILSupport" ENUM  "Yes","No";
BA_DEF_ BO_  "GenMsgRequestable" INT 0 1;
BA_DEF_ BO_  "GenMsgILSupport" ENUM  "No","Yes";
BA_DEF_ BO_  "DiagUUDTResponse" ENUM  "No","Yes";
BA_DEF_ BO_  "DiagState" ENUM  "No","Yes";
BA_DEF_ BO_  "DiagResponse" ENUM  "No","Yes";
BA_DEF_ BO_  "DiagRequest" ENUM  "No","Yes";
BA_DEF_ BO_  "DiagConnection" HEX 0 65535;
BA_DEF_  "DBName" STRING ;
BA_DEF_ BO_  "CanTpSTmin" INT 0 255;
BA_DEF_ BO_  "CanTpFcFrameId" HEX 0 2147483647;
BA_DEF_ BO_  "CanTpBs" INT 0 255;
BA_DEF_ SG_  "SystemSignalLongSymbol" STRING ;
BA_DEF_REL_ BU_SG_REL_  "GenSigTimeoutTime" INT 0 65535;
BA_DEF_REL_ BU_SG_REL_  "GenSigFirstTimeoutTime" INT 0 65535;
BA_DEF_DEF_  "GenMsgStartDelayTime" 0;
BA_DEF_DEF_  "GenMsgDelayTime" 0;
BA_DEF_DEF_  "GenMsgCycleTime" 0;
BA_DEF_DEF_  "GenMsgSendType" "Cyclic";
BA_DEF_DEF_  "GenSigStartValue" 0;
BA_DEF_DEF_  "GenSigCycleTimeActive" 0;
BA_DEF_DEF_  "GenSigCycleTime" 0;
BA_DEF_DEF_  "GenSigSendType" "Cyclic";
BA_DEF_DEF_  "Baudrate" 500000;
BA_DEF_DEF_  "BusType" "";
BA_DEF_DEF_  "NmType" "";
BA_DEF_DEF_  "Manufacturer" "VOLVO_AB";
BA_DEF_DEF_  "VersionYear" 0;
BA_DEF_DEF_  "VersionNumber" 0;
BA_DEF_DEF_  "VersionMonth" 1;
BA_DEF_DEF_  "VersionDay" 1;
BA_DEF_DEF_  "VFrameFormat" "ExtendedCAN";
BA_DEF_DEF_  "TpOwnSystemEcuNumber" 0;
BA_DEF_DEF_  "SigType" "Default";
BA_DEF_DEF_  "SeToolVersion_SIGNAL" "";
BA_DEF_DEF_  "SeToolUniqueID_SIGNAL" "";
BA_DEF_DEF_  "SeToolOwnerSigGroup_SIGNAL" "";
BA_DEF_DEF_  "SeToolOwnerSigGroupID_SIGNAL" "";
BA_DEF_DEF_  "SeToolName_SIGNAL" "";
BA_DEF_DEF_  "SeToolItemID_SIGNAL" "";
BA_DEF_DEF_  "SeToolAncestorID_SIGNAL" "";
BA_DEF_DEF_  "NmStationAddress" 254;
BA_DEF_DEF_  "NmAsrWaitBusSleepTime" 750;
BA_DEF_DEF_  "NmAsrTimeoutTime" 5000;
BA_DEF_DEF_  "NmAsrRepeatMessageTime" 300;
BA_DEF_DEF_  "NmAsrNodeIdentifier" 0;
BA_DEF_DEF_  "NmAsrNode" "Yes";
BA_DEF_DEF_  "NmAsrMessageCount" 256;
BA_DEF_DEF_  "NmAsrMessage" "No";
BA_DEF_DEF_  "NmAsrCanMsgCycleTime" 200;
BA_DEF_DEF_  "NmAsrBaseAddress" 486506496;
BA_DEF_DEF_  "NeedsUpdateBit" "No";
BA_DEF_DEF_  "MmAnSignal" "No";
BA_DEF_DEF_  "GenSigMaxLatency" 0;
BA_DEF_DEF_  "GenSigILSupport" "Yes";
BA_DEF_DEF_  "GenMsgRequestable" 1;
BA_DEF_DEF_  "GenMsgILSupport" "Yes";
BA_DEF_DEF_  "DiagUUDTResponse" "No";
BA_DEF_DEF_  "DiagState" "No";
BA_DEF_DEF_  "DiagResponse" "No";
BA_DEF_DEF_  "DiagRequest" "No";
BA_DEF_DEF_  "DiagConnection" 0;
BA_DEF_DEF_  "DBName" "";
BA_DEF_DEF_  "CanTpSTmin" 0;
BA_DEF_DEF_  "CanTpFcFrameId" 2147483647;
BA_DEF_DEF_  "CanTpBs" 255;
BA_DEF_DEF_REL_ "GenSigTimeoutTime" 0;
BA_DEF_DEF_REL_ "GenSigFirstTimeoutTime" 0;
BA_DEF_DEF_  "SystemSignalLongSymbol" "";
BA_ "NmType" "NmAsr";
BA_ "BusType" "CAN";
BA_ "VersionDay" 28;
BA_ "VersionMonth" 2;
BA_ "VersionNumber" 1;
BA_ "VersionYear" 18;
BA_ "DBName" "CabSubnet";
BA_ "TpOwnSystemEcuNumber" BU_ WRCS 38;
BA_ "NmAsrNodeIdentifier" BU_ WRCS 38;
BA_ "TpOwnSystemEcuNumber" BU_ SRS 83;
BA_ "NmAsrNodeIdentifier" BU_ SRS 83;
BA_ "TpOwnSystemEcuNumber" BU_ LECM1 162;
BA_ "NmAsrNodeIdentifier" BU_ LECM1 162;
BA_ "TpOwnSystemEcuNumber" BU_ CIOM 64;
BA_ "NmAsrNodeIdentifier" BU_ CIOM 64;
BA_ "TpOwnSystemEcuNumber" BU_ CCM 152;
BA_ "NmAsrNodeIdentifier" BU_ CCM 152;
BA_ "GenMsgCycleTime" BO_ 2499772198 50;
BA_ "GenMsgCycleTime" BO_ 2432679743 20;
BA_ "GenMsgStartDelayTime" BO_ 2432679743 5;
BA_ "GenMsgCycleTime" BO_ 2365554559 10;
BA_ "DiagConnection" BO_ 2671902706 62035;
BA_ "DiagState" BO_ 2671902706 1;
BA_ "GenMsgILSupport" BO_ 2671902706 0;
BA_ "GenMsgSendType" BO_ 2671902706 8;
BA_ "GenMsgCycleTime" BO_ 2566826323 1000;
BA_ "GenMsgCycleTime" BO_ 2566825811 1000;
BA_ "GenMsgCycleTime" BO_ 2516232019 100;
BA_ "GenMsgCycleTime" BO_ 2499788607 50;
BA_ "GenMsgStartDelayTime" BO_ 2499788607 5;
BA_ "GenMsgCycleTime" BO_ 2432689491 20;
BA_ "GenMsgILSupport" BO_ 2658975757 0;
BA_ "GenMsgSendType" BO_ 2658975757 8;
BA_ "GenMsgILSupport" BO_ 2658975756 0;
BA_ "GenMsgSendType" BO_ 2658975756 8;
BA_ "GenMsgILSupport" BO_ 2658975755 0;
BA_ "GenMsgSendType" BO_ 2658975755 8;
BA_ "GenMsgILSupport" BO_ 2658967560 0;
BA_ "GenMsgSendType" BO_ 2658967560 8;
BA_ "GenMsgILSupport" BO_ 2658967559 0;
BA_ "DiagConnection" BO_ 2671833762 62114;
BA_ "DiagResponse" BO_ 2671833762 1;
BA_ "GenMsgILSupport" BO_ 2671833762 0;
BA_ "GenMsgSendType" BO_ 2671833762 8;
BA_ "DiagConnection" BO_ 2671833752 62104;
BA_ "DiagResponse" BO_ 2671833752 1;
BA_ "GenMsgILSupport" BO_ 2671833752 0;
BA_ "GenMsgSendType" BO_ 2671833752 8;
BA_ "CanTpSTmin" BO_ 2671833683 1;
BA_ "DiagConnection" BO_ 2671833683 62035;
BA_ "DiagResponse" BO_ 2671833683 1;
BA_ "GenMsgILSupport" BO_ 2671833683 0;
BA_ "GenMsgSendType" BO_ 2671833683 8;
BA_ "DiagConnection" BO_ 2671833638 61990;
BA_ "DiagResponse" BO_ 2671833638 1;
BA_ "GenMsgILSupport" BO_ 2671833638 0;
BA_ "GenMsgSendType" BO_ 2671833638 8;
BA_ "DiagConnection" BO_ 2564485459 61779;
BA_ "DiagResponse" BO_ 2564485459 1;
BA_ "GenMsgILSupport" BO_ 2564485459 0;
BA_ "GenMsgSendType" BO_ 2564485459 8;
BA_ "DiagConnection" BO_ 2671813362 62114;
BA_ "DiagRequest" BO_ 2671813362 1;
BA_ "GenMsgILSupport" BO_ 2671813362 0;
BA_ "GenMsgSendType" BO_ 2671813362 8;
BA_ "DiagConnection" BO_ 2671810802 62104;
BA_ "DiagRequest" BO_ 2671810802 1;
BA_ "GenMsgILSupport" BO_ 2671810802 0;
BA_ "GenMsgSendType" BO_ 2671810802 8;
BA_ "DiagConnection" BO_ 2671793138 62035;
BA_ "DiagRequest" BO_ 2671793138 1;
BA_ "GenMsgILSupport" BO_ 2671793138 0;
BA_ "GenMsgSendType" BO_ 2671793138 8;
BA_ "DiagConnection" BO_ 2564445169 61779;
BA_ "DiagRequest" BO_ 2564445169 1;
BA_ "GenMsgILSupport" BO_ 2564445169 0;
BA_ "GenMsgSendType" BO_ 2564445169 8;
BA_ "DiagConnection" BO_ 2671781618 61990;
BA_ "DiagRequest" BO_ 2671781618 1;
BA_ "GenMsgILSupport" BO_ 2671781618 0;
BA_ "GenMsgSendType" BO_ 2671781618 8;
BA_ "GenMsgILSupport" BO_ 2633990182 0;
BA_ "NmAsrMessage" BO_ 2633990182 1;
BA_ "GenMsgSendType" BO_ 2633990182 8;
BA_ "GenMsgILSupport" BO_ 2633990227 0;
BA_ "NmAsrMessage" BO_ 2633990227 1;
BA_ "GenMsgSendType" BO_ 2633990227 8;
BA_ "GenMsgILSupport" BO_ 2633990306 0;
BA_ "NmAsrMessage" BO_ 2633990306 1;
BA_ "GenMsgSendType" BO_ 2633990306 8;
BA_ "GenMsgILSupport" BO_ 2633990208 0;
BA_ "NmAsrMessage" BO_ 2633990208 1;
BA_ "GenMsgSendType" BO_ 2633990208 8;
BA_ "GenMsgILSupport" BO_ 2633990296 0;
BA_ "NmAsrMessage" BO_ 2633990296 1;
BA_ "GenMsgSendType" BO_ 2633990296 8;
BA_ "GenMsgSendType" BO_ 2499772322 8;
BA_ "GenMsgDelayTime" BO_ 2499772322 50;
BA_ "GenMsgCycleTime" BO_ 2489730210 50;
BA_ "GenMsgStartDelayTime" BO_ 2489730210 10;
BA_ "GenMsgSendType" BO_ 2566043647 8;
BA_ "GenMsgDelayTime" BO_ 2566043647 200;
BA_ "GenMsgStartDelayTime" BO_ 2566043647 50;
BA_ "GenMsgCycleTime" BO_ 2432693154 10;
BA_ "GenMsgStartDelayTime" BO_ 2432693154 5;
BA_ "DiagConnection" BO_ 2671902708 62469;
BA_ "DiagState" BO_ 2671902708 1;
BA_ "GenMsgILSupport" BO_ 2671902708 0;
BA_ "GenMsgSendType" BO_ 2671902708 8;
BA_ "DiagConnection" BO_ 2671964834 62114;
BA_ "DiagUUDTResponse" BO_ 2671964834 1;
BA_ "GenMsgILSupport" BO_ 2671964834 0;
BA_ "GenMsgSendType" BO_ 2671964834 8;
BA_ "DiagConnection" BO_ 2671964824 62104;
BA_ "DiagUUDTResponse" BO_ 2671964824 1;
BA_ "GenMsgILSupport" BO_ 2671964824 0;
BA_ "GenMsgSendType" BO_ 2671964824 8;
BA_ "DiagConnection" BO_ 2671964755 62035;
BA_ "DiagUUDTResponse" BO_ 2671964755 1;
BA_ "GenMsgILSupport" BO_ 2671964755 0;
BA_ "GenMsgSendType" BO_ 2671964755 8;
BA_ "DiagConnection" BO_ 2671964710 61990;
BA_ "DiagUUDTResponse" BO_ 2671964710 1;
BA_ "GenMsgILSupport" BO_ 2671964710 0;
BA_ "GenMsgSendType" BO_ 2671964710 8;
BA_ "DiagConnection" BO_ 2671834274 62626;
BA_ "DiagResponse" BO_ 2671834274 1;
BA_ "GenMsgILSupport" BO_ 2671834274 0;
BA_ "GenMsgSendType" BO_ 2671834274 8;
BA_ "DiagConnection" BO_ 2671834264 62616;
BA_ "DiagResponse" BO_ 2671834264 1;
BA_ "GenMsgILSupport" BO_ 2671834264 0;
BA_ "GenMsgSendType" BO_ 2671834264 8;
BA_ "CanTpSTmin" BO_ 2671834195 1;
BA_ "DiagConnection" BO_ 2671834195 62547;
BA_ "DiagResponse" BO_ 2671834195 1;
BA_ "GenMsgILSupport" BO_ 2671834195 0;
BA_ "GenMsgSendType" BO_ 2671834195 8;
BA_ "DiagConnection" BO_ 2671834150 62502;
BA_ "DiagResponse" BO_ 2671834150 1;
BA_ "GenMsgILSupport" BO_ 2671834150 0;
BA_ "GenMsgSendType" BO_ 2671834150 8;
BA_ "DiagConnection" BO_ 2671834018 62370;
BA_ "DiagResponse" BO_ 2671834018 1;
BA_ "GenMsgILSupport" BO_ 2671834018 0;
BA_ "GenMsgSendType" BO_ 2671834018 8;
BA_ "DiagConnection" BO_ 2671834008 62360;
BA_ "DiagResponse" BO_ 2671834008 1;
BA_ "GenMsgILSupport" BO_ 2671834008 0;
BA_ "GenMsgSendType" BO_ 2671834008 8;
BA_ "CanTpSTmin" BO_ 2671833939 1;
BA_ "DiagConnection" BO_ 2671833939 62291;
BA_ "DiagResponse" BO_ 2671833939 1;
BA_ "GenMsgILSupport" BO_ 2671833939 0;
BA_ "GenMsgSendType" BO_ 2671833939 8;
BA_ "DiagConnection" BO_ 2671833894 62246;
BA_ "DiagResponse" BO_ 2671833894 1;
BA_ "GenMsgILSupport" BO_ 2671833894 0;
BA_ "GenMsgSendType" BO_ 2671833894 8;
BA_ "DiagConnection" BO_ 2671813364 62626;
BA_ "DiagRequest" BO_ 2671813364 1;
BA_ "GenMsgILSupport" BO_ 2671813364 0;
BA_ "GenMsgSendType" BO_ 2671813364 8;
BA_ "DiagConnection" BO_ 2671810804 62616;
BA_ "DiagRequest" BO_ 2671810804 1;
BA_ "GenMsgILSupport" BO_ 2671810804 0;
BA_ "GenMsgSendType" BO_ 2671810804 8;
BA_ "DiagConnection" BO_ 2671793140 62547;
BA_ "DiagRequest" BO_ 2671793140 1;
BA_ "GenMsgILSupport" BO_ 2671793140 0;
BA_ "GenMsgSendType" BO_ 2671793140 8;
BA_ "DiagConnection" BO_ 2671781620 62502;
BA_ "DiagRequest" BO_ 2671781620 1;
BA_ "GenMsgILSupport" BO_ 2671781620 0;
BA_ "GenMsgSendType" BO_ 2671781620 8;
BA_ "DiagConnection" BO_ 2671813363 62370;
BA_ "DiagRequest" BO_ 2671813363 1;
BA_ "GenMsgILSupport" BO_ 2671813363 0;
BA_ "GenMsgSendType" BO_ 2671813363 8;
BA_ "DiagConnection" BO_ 2671810803 62360;
BA_ "DiagRequest" BO_ 2671810803 1;
BA_ "GenMsgILSupport" BO_ 2671810803 0;
BA_ "GenMsgSendType" BO_ 2671810803 8;
BA_ "DiagConnection" BO_ 2671793139 62291;
BA_ "DiagRequest" BO_ 2671793139 1;
BA_ "GenMsgILSupport" BO_ 2671793139 0;
BA_ "GenMsgSendType" BO_ 2671793139 8;
BA_ "DiagConnection" BO_ 2671781619 62246;
BA_ "DiagRequest" BO_ 2671781619 1;
BA_ "GenMsgILSupport" BO_ 2671781619 0;
BA_ "GenMsgSendType" BO_ 2671781619 8;
BA_ "GenMsgCycleTime" BO_ 2567057439 1000;
BA_ "GenMsgDelayTime" BO_ 2567057439 90;
BA_ "GenMsgStartDelayTime" BO_ 2567057439 15;
BA_ "GenMsgCycleTime" BO_ 2567057438 1000;
BA_ "GenMsgDelayTime" BO_ 2567057438 95;
BA_ "GenMsgStartDelayTime" BO_ 2567057438 20;
BA_ "GenMsgCycleTime" BO_ 2567057437 1000;
BA_ "GenMsgDelayTime" BO_ 2567057437 95;
BA_ "GenMsgStartDelayTime" BO_ 2567057437 50;
BA_ "GenMsgCycleTime" BO_ 2567057436 1000;
BA_ "GenMsgDelayTime" BO_ 2567057436 95;
BA_ "GenMsgStartDelayTime" BO_ 2567057436 55;
BA_ "GenMsgSendType" BO_ 2634020435 8;
BA_ "GenMsgDelayTime" BO_ 2634020435 50;
BA_ "GenMsgStartDelayTime" BO_ 2634020435 50;
BA_ "GenMsgSendType" BO_ 2634020514 8;
BA_ "GenMsgDelayTime" BO_ 2634020514 50;
BA_ "GenMsgStartDelayTime" BO_ 2634020514 50;
BA_ "GenMsgILSupport" BO_ 2634020504 0;
BA_ "GenMsgSendType" BO_ 2634020504 8;
BA_ "GenMsgDelayTime" BO_ 2634020504 50;
BA_ "GenMsgStartDelayTime" BO_ 2634020504 50;
BA_ "GenMsgSendType" BO_ 2634020179 8;
BA_ "GenMsgDelayTime" BO_ 2634020179 50;
BA_ "GenMsgStartDelayTime" BO_ 2634020179 50;
BA_ "GenMsgSendType" BO_ 2634020258 8;
BA_ "GenMsgDelayTime" BO_ 2634020258 50;
BA_ "GenMsgStartDelayTime" BO_ 2634020258 50;
BA_ "GenMsgILSupport" BO_ 2634020248 0;
BA_ "GenMsgSendType" BO_ 2634020248 8;
BA_ "GenMsgDelayTime" BO_ 2634020248 50;
BA_ "GenMsgStartDelayTime" BO_ 2634020248 50;
BA_ "GenMsgSendType" BO_ 2634019923 8;
BA_ "GenMsgDelayTime" BO_ 2634019923 50;
BA_ "GenMsgStartDelayTime" BO_ 2634019923 50;
BA_ "GenMsgSendType" BO_ 2634020002 8;
BA_ "GenMsgDelayTime" BO_ 2634020002 50;
BA_ "GenMsgStartDelayTime" BO_ 2634020002 50;
BA_ "GenMsgILSupport" BO_ 2634019992 0;
BA_ "GenMsgSendType" BO_ 2634019992 8;
BA_ "GenMsgDelayTime" BO_ 2634019992 50;
BA_ "GenMsgStartDelayTime" BO_ 2634019992 50;
BA_ "GenMsgSendType" BO_ 2634019667 8;
BA_ "GenMsgDelayTime" BO_ 2634019667 50;
BA_ "GenMsgStartDelayTime" BO_ 2634019667 50;
BA_ "GenMsgSendType" BO_ 2634019746 8;
BA_ "GenMsgDelayTime" BO_ 2634019746 50;
BA_ "GenMsgStartDelayTime" BO_ 2634019746 50;
BA_ "GenMsgILSupport" BO_ 2634019736 0;
BA_ "GenMsgSendType" BO_ 2634019411 8;
BA_ "GenMsgDelayTime" BO_ 2634019411 50;
BA_ "GenMsgStartDelayTime" BO_ 2634019411 50;
BA_ "GenMsgSendType" BO_ 2634019490 8;
BA_ "GenMsgDelayTime" BO_ 2634019490 50;
BA_ "GenMsgStartDelayTime" BO_ 2634019490 50;
BA_ "GenMsgILSupport" BO_ 2634019480 0;
BA_ "GenMsgILSupport" BO_ 2634019224 0;
BA_ "GenMsgILSupport" BO_ 2566357313 0;
BA_ "GenMsgSendType" BO_ 2566357313 8;
BA_ "CanTpFcFrameId" BO_ 2566357312 418873665;
BA_ "GenMsgCycleTime" BO_ 2566357312 500;
BA_ "GenMsgStartDelayTime" BO_ 2566357312 50;
BA_ "GenMsgCycleTime" BO_ 2432680000 10;
BA_ "GenMsgStartDelayTime" BO_ 2432680000 50;
BA_ "GenMsgCycleTime" BO_ 2432647232 20;
BA_ "GenMsgStartDelayTime" BO_ 2432647232 50;
BA_ "GenMsgCycleTime" BO_ 2516193600 100;
BA_ "GenMsgILSupport" BO_ 2566357057 0;
BA_ "GenMsgSendType" BO_ 2566357057 8;
BA_ "CanTpFcFrameId" BO_ 2566357056 418873409;
BA_ "GenMsgSendType" BO_ 2566357056 8;
BA_ "GenMsgDelayTime" BO_ 2566357056 150;
BA_ "GenMsgILSupport" BO_ 2432679745 0;
BA_ "GenMsgSendType" BO_ 2432679745 8;
BA_ "CanTpFcFrameId" BO_ 2432679744 285196097;
BA_ "GenMsgSendType" BO_ 2432679744 8;
BA_ "GenMsgDelayTime" BO_ 2432679744 50;
BA_ "GenMsgSendType" BO_ 2432646976 8;
BA_ "GenMsgDelayTime" BO_ 2432646976 20;
BA_ "GenMsgCycleTime" BO_ 2493989952 50;
BA_ "GenMsgStartDelayTime" BO_ 2493989952 25;
BA_ "GenMsgCycleTime" BO_ 2499754560 50;
BA_ "GenMsgILSupport" BO_ 2566356801 0;
BA_ "GenMsgSendType" BO_ 2566356801 8;
BA_ "GenSigSendType" SG_ 2499772198 TipperShakerRequest_UB_ISig_5 7;
BA_ "GenSigSendType" SG_ 2499772198 TipperUpDownRequest_UB_ISig_5 7;
BA_ "GenSigSendType" SG_ 2499772198 ExtraBbWrcWatchdog_UB_ISig_5 7;
BA_ "GenSigCycleTime" SG_ 2499772198 TipperTarpaulinRequest_ISig_5 100;
BA_ "GenSigCycleTimeActive" SG_ 2499772198 TipperTarpaulinRequest_ISig_5 100;
BA_ "GenSigStartValue" SG_ 2499772198 TipperTarpaulinRequest_ISig_5 7;
BA_ "GenSigMaxLatency" SG_ 2499772198 TipperTarpaulinRequest_ISig_5 65;
BA_ "NeedsUpdateBit" SG_ 2499772198 TipperTarpaulinRequest_ISig_5 1;
BA_ "GenSigSendType" SG_ 2499772198 TipperEmergencyStop_UB_ISig_5 7;
BA_ "GenSigCycleTime" SG_ 2499772198 TipperUpDownRequest_ISig_5 100;
BA_ "GenSigCycleTimeActive" SG_ 2499772198 TipperUpDownRequest_ISig_5 100;
BA_ "GenSigStartValue" SG_ 2499772198 TipperUpDownRequest_ISig_5 7;
BA_ "GenSigMaxLatency" SG_ 2499772198 TipperUpDownRequest_ISig_5 65;
BA_ "NeedsUpdateBit" SG_ 2499772198 TipperUpDownRequest_ISig_5 1;
BA_ "GenSigCycleTime" SG_ 2499772198 TailLiftMotionRequest_ISig_5 100;
BA_ "GenSigCycleTimeActive" SG_ 2499772198 TailLiftMotionRequest_ISig_5 100;
BA_ "GenSigStartValue" SG_ 2499772198 TailLiftMotionRequest_ISig_5 7;
BA_ "GenSigMaxLatency" SG_ 2499772198 TailLiftMotionRequest_ISig_5 65;
BA_ "NeedsUpdateBit" SG_ 2499772198 TailLiftMotionRequest_ISig_5 1;
BA_ "GenSigSendType" SG_ 2499772198 TipperTippingBodySelection_UB_IS 7;
BA_ "SystemSignalLongSymbol" SG_ 2499772198 TipperTippingBodySelection_UB_IS "TipperTippingBodySelection_UB_ISig_5";
BA_ "GenSigCycleTime" SG_ 2499772198 TipperEmergencyStop_ISig_5 100;
BA_ "GenSigCycleTimeActive" SG_ 2499772198 TipperEmergencyStop_ISig_5 100;
BA_ "GenSigStartValue" SG_ 2499772198 TipperEmergencyStop_ISig_5 3;
BA_ "GenSigMaxLatency" SG_ 2499772198 TipperEmergencyStop_ISig_5 65;
BA_ "NeedsUpdateBit" SG_ 2499772198 TipperEmergencyStop_ISig_5 1;
BA_ "GenSigCycleTime" SG_ 2499772198 ExtraBbWrcWatchdog_ISig_5 100;
BA_ "GenSigCycleTimeActive" SG_ 2499772198 ExtraBbWrcWatchdog_ISig_5 100;
BA_ "GenSigStartValue" SG_ 2499772198 ExtraBbWrcWatchdog_ISig_5 3;
BA_ "GenSigMaxLatency" SG_ 2499772198 ExtraBbWrcWatchdog_ISig_5 65;
BA_ "NeedsUpdateBit" SG_ 2499772198 ExtraBbWrcWatchdog_ISig_5 1;
BA_ "GenSigCycleTime" SG_ 2499772198 TipperTailGateRequest_ISig_5 100;
BA_ "GenSigCycleTimeActive" SG_ 2499772198 TipperTailGateRequest_ISig_5 100;
BA_ "GenSigStartValue" SG_ 2499772198 TipperTailGateRequest_ISig_5 7;
BA_ "GenSigMaxLatency" SG_ 2499772198 TipperTailGateRequest_ISig_5 65;
BA_ "NeedsUpdateBit" SG_ 2499772198 TipperTailGateRequest_ISig_5 1;
BA_ "GenSigCycleTime" SG_ 2499772198 TipperTippingBodySelection_ISig_ 100;
BA_ "GenSigCycleTimeActive" SG_ 2499772198 TipperTippingBodySelection_ISig_ 100;
BA_ "GenSigStartValue" SG_ 2499772198 TipperTippingBodySelection_ISig_ 3;
BA_ "GenSigMaxLatency" SG_ 2499772198 TipperTippingBodySelection_ISig_ 65;
BA_ "NeedsUpdateBit" SG_ 2499772198 TipperTippingBodySelection_ISig_ 1;
BA_ "SystemSignalLongSymbol" SG_ 2499772198 TipperTippingBodySelection_ISig_ "TipperTippingBodySelection_ISig_5";
BA_ "GenSigSendType" SG_ 2499772198 TipperTarpaulinRequest_UB_ISig_5 7;
BA_ "GenSigSendType" SG_ 2499772198 TailLiftMotionRequest_UB_ISig_5 7;
BA_ "GenSigCycleTime" SG_ 2499772198 TipperShakerRequest_ISig_5 100;
BA_ "GenSigCycleTimeActive" SG_ 2499772198 TipperShakerRequest_ISig_5 100;
BA_ "GenSigStartValue" SG_ 2499772198 TipperShakerRequest_ISig_5 3;
BA_ "GenSigMaxLatency" SG_ 2499772198 TipperShakerRequest_ISig_5 65;
BA_ "NeedsUpdateBit" SG_ 2499772198 TipperShakerRequest_ISig_5 1;
BA_ "GenSigSendType" SG_ 2499772198 TipperTailGateRequest_UB_ISig_5 7;
BA_ "GenSigCycleTime" SG_ 2432679743 WRC5thWheelRequest 100;
BA_ "GenSigCycleTimeActive" SG_ 2432679743 WRC5thWheelRequest 100;
BA_ "GenSigStartValue" SG_ 2432679743 WRC5thWheelRequest 3;
BA_ "GenSigMaxLatency" SG_ 2432679743 WRC5thWheelRequest 35;
BA_ "GenSigSendType" SG_ 2432679743 WRCEngineStopRequest_UB_ISig_5 7;
BA_ "GenSigCycleTime" SG_ 2432679743 WRC_Docking_stat_ISig_5 100;
BA_ "GenSigCycleTimeActive" SG_ 2432679743 WRC_Docking_stat_ISig_5 100;
BA_ "GenSigStartValue" SG_ 2432679743 WRC_Docking_stat_ISig_5 3;
BA_ "GenSigCycleTime" SG_ 2432679743 WRCLevelUserMemoryAction 100;
BA_ "GenSigCycleTimeActive" SG_ 2432679743 WRCLevelUserMemoryAction 100;
BA_ "GenSigStartValue" SG_ 2432679743 WRCLevelUserMemoryAction 7;
BA_ "GenSigMaxLatency" SG_ 2432679743 WRCLevelUserMemoryAction 35;
BA_ "GenSigCycleTime" SG_ 2432679743 WRCLevelUserMemory 100;
BA_ "GenSigCycleTimeActive" SG_ 2432679743 WRCLevelUserMemory 100;
BA_ "GenSigStartValue" SG_ 2432679743 WRCLevelUserMemory 15;
BA_ "GenSigMaxLatency" SG_ 2432679743 WRCLevelUserMemory 35;
BA_ "GenSigSendType" SG_ 2432679743 WRCEngineStartRequest_UB_ISig_5 7;
BA_ "GenSigCycleTime" SG_ 2432679743 WrcEngSpdCtrlResumeButtonStat 100;
BA_ "GenSigCycleTimeActive" SG_ 2432679743 WrcEngSpdCtrlResumeButtonStat 100;
BA_ "GenSigStartValue" SG_ 2432679743 WrcEngSpdCtrlResumeButtonStat 3;
BA_ "GenSigMaxLatency" SG_ 2432679743 WrcEngSpdCtrlResumeButtonStat 35;
BA_ "GenSigCycleTime" SG_ 2432679743 WRCBeaconRequest 100;
BA_ "GenSigCycleTimeActive" SG_ 2432679743 WRCBeaconRequest 100;
BA_ "GenSigStartValue" SG_ 2432679743 WRCBeaconRequest 3;
BA_ "GenSigMaxLatency" SG_ 2432679743 WRCBeaconRequest 35;
BA_ "GenSigCycleTime" SG_ 2432679743 WrcEngSpdCtrlDecreaseButtStat 100;
BA_ "GenSigCycleTimeActive" SG_ 2432679743 WrcEngSpdCtrlDecreaseButtStat 100;
BA_ "GenSigStartValue" SG_ 2432679743 WrcEngSpdCtrlDecreaseButtStat 3;
BA_ "GenSigMaxLatency" SG_ 2432679743 WrcEngSpdCtrlDecreaseButtStat 35;
BA_ "GenSigCycleTime" SG_ 2432679743 WRCEngineStartRequest_ISig_5 100;
BA_ "GenSigCycleTimeActive" SG_ 2432679743 WRCEngineStartRequest_ISig_5 100;
BA_ "GenSigStartValue" SG_ 2432679743 WRCEngineStartRequest_ISig_5 3;
BA_ "GenSigMaxLatency" SG_ 2432679743 WRCEngineStartRequest_ISig_5 35;
BA_ "NeedsUpdateBit" SG_ 2432679743 WRCEngineStartRequest_ISig_5 1;
BA_ "GenSigCycleTime" SG_ 2432679743 WrcEngSpdCtrlEnableStatus 100;
BA_ "GenSigCycleTimeActive" SG_ 2432679743 WrcEngSpdCtrlEnableStatus 100;
BA_ "GenSigStartValue" SG_ 2432679743 WrcEngSpdCtrlEnableStatus 3;
BA_ "GenSigMaxLatency" SG_ 2432679743 WrcEngSpdCtrlEnableStatus 35;
BA_ "GenSigCycleTime" SG_ 2432679743 WRCCabBodyWLightsRqst 100;
BA_ "GenSigCycleTimeActive" SG_ 2432679743 WRCCabBodyWLightsRqst 100;
BA_ "GenSigStartValue" SG_ 2432679743 WRCCabBodyWLightsRqst 3;
BA_ "GenSigMaxLatency" SG_ 2432679743 WRCCabBodyWLightsRqst 35;
BA_ "GenSigCycleTime" SG_ 2432679743 WRCEngineStopRequest_ISig_5 100;
BA_ "GenSigCycleTimeActive" SG_ 2432679743 WRCEngineStopRequest_ISig_5 100;
BA_ "GenSigStartValue" SG_ 2432679743 WRCEngineStopRequest_ISig_5 3;
BA_ "GenSigMaxLatency" SG_ 2432679743 WRCEngineStopRequest_ISig_5 35;
BA_ "NeedsUpdateBit" SG_ 2432679743 WRCEngineStopRequest_ISig_5 1;
BA_ "GenSigCycleTime" SG_ 2432679743 WrcEngSpdCtrlIncreaseButtStat 100;
BA_ "GenSigCycleTimeActive" SG_ 2432679743 WrcEngSpdCtrlIncreaseButtStat 100;
BA_ "GenSigStartValue" SG_ 2432679743 WrcEngSpdCtrlIncreaseButtStat 3;
BA_ "GenSigMaxLatency" SG_ 2432679743 WrcEngSpdCtrlIncreaseButtStat 35;
BA_ "GenSigCycleTime" SG_ 2365554559 WrcPto1ButtonStatus 100;
BA_ "GenSigCycleTimeActive" SG_ 2365554559 WrcPto1ButtonStatus 100;
BA_ "GenSigStartValue" SG_ 2365554559 WrcPto1ButtonStatus 3;
BA_ "GenSigMaxLatency" SG_ 2365554559 WrcPto1ButtonStatus 15;
BA_ "GenSigCycleTime" SG_ 2365554559 ECSStandByReqWRC 100;
BA_ "GenSigCycleTimeActive" SG_ 2365554559 ECSStandByReqWRC 100;
BA_ "GenSigStartValue" SG_ 2365554559 ECSStandByReqWRC 7;
BA_ "GenSigMaxLatency" SG_ 2365554559 ECSStandByReqWRC 15;
BA_ "GenSigCycleTime" SG_ 2365554559 WRCCraneRequest 100;
BA_ "GenSigCycleTimeActive" SG_ 2365554559 WRCCraneRequest 100;
BA_ "GenSigStartValue" SG_ 2365554559 WRCCraneRequest 3;
BA_ "GenSigMaxLatency" SG_ 2365554559 WRCCraneRequest 15;
BA_ "GenSigCycleTime" SG_ 2365554559 WRCUnlockButtonStatus 100;
BA_ "GenSigCycleTimeActive" SG_ 2365554559 WRCUnlockButtonStatus 100;
BA_ "GenSigStartValue" SG_ 2365554559 WRCUnlockButtonStatus 3;
BA_ "GenSigMaxLatency" SG_ 2365554559 WRCUnlockButtonStatus 15;
BA_ "GenSigCycleTime" SG_ 2365554559 WRCRollRequest 100;
BA_ "GenSigCycleTimeActive" SG_ 2365554559 WRCRollRequest 100;
BA_ "GenSigStartValue" SG_ 2365554559 WRCRollRequest 7;
BA_ "GenSigMaxLatency" SG_ 2365554559 WRCRollRequest 15;
BA_ "GenSigCycleTime" SG_ 2365554559 WRCAux3Request 100;
BA_ "GenSigCycleTimeActive" SG_ 2365554559 WRCAux3Request 100;
BA_ "GenSigStartValue" SG_ 2365554559 WRCAux3Request 3;
BA_ "GenSigMaxLatency" SG_ 2365554559 WRCAux3Request 15;
BA_ "GenSigCycleTime" SG_ 2365554559 WRCAux2Request 100;
BA_ "GenSigCycleTimeActive" SG_ 2365554559 WRCAux2Request 100;
BA_ "GenSigStartValue" SG_ 2365554559 WRCAux2Request 3;
BA_ "GenSigMaxLatency" SG_ 2365554559 WRCAux2Request 15;
BA_ "GenSigCycleTime" SG_ 2365554559 WrcPto3ButtonStatus 100;
BA_ "GenSigCycleTimeActive" SG_ 2365554559 WrcPto3ButtonStatus 100;
BA_ "GenSigStartValue" SG_ 2365554559 WrcPto3ButtonStatus 3;
BA_ "GenSigMaxLatency" SG_ 2365554559 WrcPto3ButtonStatus 15;
BA_ "GenSigCycleTime" SG_ 2365554559 WRCLevelAdjustmentAction 100;
BA_ "GenSigCycleTimeActive" SG_ 2365554559 WRCLevelAdjustmentAction 100;
BA_ "GenSigStartValue" SG_ 2365554559 WRCLevelAdjustmentAction 15;
BA_ "GenSigMaxLatency" SG_ 2365554559 WRCLevelAdjustmentAction 15;
BA_ "GenSigCycleTime" SG_ 2365554559 WRCAux4Request 100;
BA_ "GenSigCycleTimeActive" SG_ 2365554559 WRCAux4Request 100;
BA_ "GenSigStartValue" SG_ 2365554559 WRCAux4Request 3;
BA_ "GenSigMaxLatency" SG_ 2365554559 WRCAux4Request 15;
BA_ "GenSigCycleTime" SG_ 2365554559 WRCAux5Request 100;
BA_ "GenSigCycleTimeActive" SG_ 2365554559 WRCAux5Request 100;
BA_ "GenSigStartValue" SG_ 2365554559 WRCAux5Request 3;
BA_ "GenSigMaxLatency" SG_ 2365554559 WRCAux5Request 15;
BA_ "GenSigCycleTime" SG_ 2365554559 WRCAux6Request 100;
BA_ "GenSigCycleTimeActive" SG_ 2365554559 WRCAux6Request 100;
BA_ "GenSigStartValue" SG_ 2365554559 WRCAux6Request 3;
BA_ "GenSigMaxLatency" SG_ 2365554559 WRCAux6Request 15;
BA_ "GenSigCycleTime" SG_ 2365554559 WRCSideReverseWorkingRequest 100;
BA_ "GenSigCycleTimeActive" SG_ 2365554559 WRCSideReverseWorkingRequest 100;
BA_ "GenSigStartValue" SG_ 2365554559 WRCSideReverseWorkingRequest 3;
BA_ "GenSigMaxLatency" SG_ 2365554559 WRCSideReverseWorkingRequest 15;
BA_ "GenSigCycleTime" SG_ 2365554559 WrcPto2ButtonStatus 100;
BA_ "GenSigCycleTimeActive" SG_ 2365554559 WrcPto2ButtonStatus 100;
BA_ "GenSigStartValue" SG_ 2365554559 WrcPto2ButtonStatus 3;
BA_ "GenSigMaxLatency" SG_ 2365554559 WrcPto2ButtonStatus 15;
BA_ "GenSigCycleTime" SG_ 2365554559 WRCTailLiftRequest 100;
BA_ "GenSigCycleTimeActive" SG_ 2365554559 WRCTailLiftRequest 100;
BA_ "GenSigStartValue" SG_ 2365554559 WRCTailLiftRequest 3;
BA_ "GenSigMaxLatency" SG_ 2365554559 WRCTailLiftRequest 15;
BA_ "GenSigCycleTime" SG_ 2365554559 WrcPto4ButtonStatus 100;
BA_ "GenSigCycleTimeActive" SG_ 2365554559 WrcPto4ButtonStatus 100;
BA_ "GenSigStartValue" SG_ 2365554559 WrcPto4ButtonStatus 3;
BA_ "GenSigMaxLatency" SG_ 2365554559 WrcPto4ButtonStatus 15;
BA_ "GenSigCycleTime" SG_ 2365554559 WRCLevelAdjustmentStroke 100;
BA_ "GenSigCycleTimeActive" SG_ 2365554559 WRCLevelAdjustmentStroke 100;
BA_ "GenSigStartValue" SG_ 2365554559 WRCLevelAdjustmentStroke 7;
BA_ "GenSigMaxLatency" SG_ 2365554559 WRCLevelAdjustmentStroke 15;
BA_ "GenSigCycleTime" SG_ 2365554559 WRCLevelAdjustmentAxles 100;
BA_ "GenSigCycleTimeActive" SG_ 2365554559 WRCLevelAdjustmentAxles 100;
BA_ "GenSigStartValue" SG_ 2365554559 WRCLevelAdjustmentAxles 7;
BA_ "GenSigMaxLatency" SG_ 2365554559 WRCLevelAdjustmentAxles 15;
BA_ "GenSigCycleTime" SG_ 2365554559 WRCAirSuspensionStopRequest 100;
BA_ "GenSigCycleTimeActive" SG_ 2365554559 WRCAirSuspensionStopRequest 100;
BA_ "GenSigStartValue" SG_ 2365554559 WRCAirSuspensionStopRequest 3;
BA_ "GenSigMaxLatency" SG_ 2365554559 WRCAirSuspensionStopRequest 15;
BA_ "GenSigCycleTime" SG_ 2365554559 WRCAux1Request 100;
BA_ "GenSigCycleTimeActive" SG_ 2365554559 WRCAux1Request 100;
BA_ "GenSigStartValue" SG_ 2365554559 WRCAux1Request 3;
BA_ "GenSigMaxLatency" SG_ 2365554559 WRCAux1Request 15;
BA_ "GenSigCycleTime" SG_ 2365554559 WRCLockButtonStatus 100;
BA_ "GenSigCycleTimeActive" SG_ 2365554559 WRCLockButtonStatus 100;
BA_ "GenSigStartValue" SG_ 2365554559 WRCLockButtonStatus 3;
BA_ "GenSigMaxLatency" SG_ 2365554559 WRCLockButtonStatus 15;
BA_ "GenSigSendType" SG_ 2671902706 FuncDiagDataTester_ISig_5 7;
BA_ "GenSigCycleTime" SG_ 2566826323 SRS2_SN_Byte2 100;
BA_ "GenSigCycleTimeActive" SG_ 2566826323 SRS2_SN_Byte2 100;
BA_ "GenSigStartValue" SG_ 2566826323 SRS2_SN_Byte2 255;
BA_ "GenSigMaxLatency" SG_ 2566826323 SRS2_SN_Byte2 1000;
BA_ "GenSigCycleTime" SG_ 2566826323 SRS2_SN_Byte1 100;
BA_ "GenSigCycleTimeActive" SG_ 2566826323 SRS2_SN_Byte1 100;
BA_ "GenSigStartValue" SG_ 2566826323 SRS2_SN_Byte1 255;
BA_ "GenSigMaxLatency" SG_ 2566826323 SRS2_SN_Byte1 1000;
BA_ "GenSigCycleTime" SG_ 2566826323 SRS2_SN_Byte0 100;
BA_ "GenSigCycleTimeActive" SG_ 2566826323 SRS2_SN_Byte0 100;
BA_ "GenSigStartValue" SG_ 2566826323 SRS2_SN_Byte0 255;
BA_ "GenSigMaxLatency" SG_ 2566826323 SRS2_SN_Byte0 1000;
BA_ "GenSigCycleTime" SG_ 2566826323 SRS2_SN_Byte3 100;
BA_ "GenSigCycleTimeActive" SG_ 2566826323 SRS2_SN_Byte3 100;
BA_ "GenSigStartValue" SG_ 2566826323 SRS2_SN_Byte3 255;
BA_ "GenSigMaxLatency" SG_ 2566826323 SRS2_SN_Byte3 1000;
BA_ "GenSigCycleTime" SG_ 2566825811 SRS2_SNPN_Byte2 100;
BA_ "GenSigCycleTimeActive" SG_ 2566825811 SRS2_SNPN_Byte2 100;
BA_ "GenSigStartValue" SG_ 2566825811 SRS2_SNPN_Byte2 255;
BA_ "GenSigMaxLatency" SG_ 2566825811 SRS2_SNPN_Byte2 1000;
BA_ "GenSigCycleTime" SG_ 2566825811 SRS2_SNPN_Byte3 100;
BA_ "GenSigCycleTimeActive" SG_ 2566825811 SRS2_SNPN_Byte3 100;
BA_ "GenSigStartValue" SG_ 2566825811 SRS2_SNPN_Byte3 255;
BA_ "GenSigMaxLatency" SG_ 2566825811 SRS2_SNPN_Byte3 1000;
BA_ "GenSigCycleTime" SG_ 2566825811 SRS2_SNPN_Byte1 100;
BA_ "GenSigCycleTimeActive" SG_ 2566825811 SRS2_SNPN_Byte1 100;
BA_ "GenSigStartValue" SG_ 2566825811 SRS2_SNPN_Byte1 255;
BA_ "GenSigMaxLatency" SG_ 2566825811 SRS2_SNPN_Byte1 1000;
BA_ "GenSigCycleTime" SG_ 2566825811 SRS2_SNPN_Byte0 100;
BA_ "GenSigCycleTimeActive" SG_ 2566825811 SRS2_SNPN_Byte0 100;
BA_ "GenSigStartValue" SG_ 2566825811 SRS2_SNPN_Byte0 255;
BA_ "GenSigMaxLatency" SG_ 2566825811 SRS2_SNPN_Byte0 1000;
BA_ "GenSigCycleTime" SG_ 2566825811 SRS2_SNPN_Byte4 100;
BA_ "GenSigCycleTimeActive" SG_ 2566825811 SRS2_SNPN_Byte4 100;
BA_ "GenSigStartValue" SG_ 2566825811 SRS2_SNPN_Byte4 255;
BA_ "GenSigMaxLatency" SG_ 2566825811 SRS2_SNPN_Byte4 1000;
BA_ "GenSigCycleTime" SG_ 2516232019 DiagInfoSRS2 100;
BA_ "GenSigCycleTimeActive" SG_ 2516232019 DiagInfoSRS2 100;
BA_ "GenSigMaxLatency" SG_ 2516232019 DiagInfoSRS2 100;
BA_ "GenSigCycleTime" SG_ 2499788607 ECUVIN_rqst 100;
BA_ "GenSigCycleTimeActive" SG_ 2499788607 ECUVIN_rqst 100;
BA_ "GenSigMaxLatency" SG_ 2499788607 ECUVIN_rqst 60;
BA_ "GenSigCycleTime" SG_ 2432689491 SRSAirbagStatus_ISig_5 100;
BA_ "GenSigCycleTimeActive" SG_ 2432689491 SRSAirbagStatus_ISig_5 100;
BA_ "GenSigStartValue" SG_ 2432689491 SRSAirbagStatus_ISig_5 3;
BA_ "GenSigMaxLatency" SG_ 2432689491 SRSAirbagStatus_ISig_5 26;
BA_ "SeToolAncestorID_SIGNAL" SG_ 2432689491 SRSAirbagStatus_ISig_5 "x0000001D04147207";
BA_ "SeToolItemID_SIGNAL" SG_ 2432689491 SRSAirbagStatus_ISig_5 "x0000001D042F372C";
BA_ "SeToolName_SIGNAL" SG_ 2432689491 SRSAirbagStatus_ISig_5 "SRSAirbagStatus";
BA_ "SeToolVersion_SIGNAL" SG_ 2432689491 SRSAirbagStatus_ISig_5 "2";
BA_ "GenSigCycleTime" SG_ 2432689491 TrafficAccidentHazardLightRqst_I 100;
BA_ "GenSigCycleTimeActive" SG_ 2432689491 TrafficAccidentHazardLightRqst_I 100;
BA_ "GenSigStartValue" SG_ 2432689491 TrafficAccidentHazardLightRqst_I 3;
BA_ "SystemSignalLongSymbol" SG_ 2432689491 TrafficAccidentHazardLightRqst_I "TrafficAccidentHazardLightRqst_ISig_5";
BA_ "GenSigCycleTime" SG_ 2432689491 FrontalCollisionAccidentStatus_I 100;
BA_ "GenSigCycleTimeActive" SG_ 2432689491 FrontalCollisionAccidentStatus_I 100;
BA_ "GenSigStartValue" SG_ 2432689491 FrontalCollisionAccidentStatus_I 3;
BA_ "SystemSignalLongSymbol" SG_ 2432689491 FrontalCollisionAccidentStatus_I "FrontalCollisionAccidentStatus_ISig_5";
BA_ "GenSigCycleTime" SG_ 2432689491 EmergencyDoorsUnlock_rqst 100;
BA_ "GenSigCycleTimeActive" SG_ 2432689491 EmergencyDoorsUnlock_rqst 100;
BA_ "GenSigStartValue" SG_ 2432689491 EmergencyDoorsUnlock_rqst 7;
BA_ "GenSigMaxLatency" SG_ 2432689491 EmergencyDoorsUnlock_rqst 26;
BA_ "GenSigCycleTime" SG_ 2432689491 RollOverAccidentStatus_ISig_5 100;
BA_ "GenSigCycleTimeActive" SG_ 2432689491 RollOverAccidentStatus_ISig_5 100;
BA_ "GenSigStartValue" SG_ 2432689491 RollOverAccidentStatus_ISig_5 3;
BA_ "GenSigSendType" SG_ 2658975757 SRSDiagPSTesterTx4 7;
BA_ "GenSigSendType" SG_ 2658975756 SRSDiagPSTesterTx3 7;
BA_ "GenSigSendType" SG_ 2658975755 SRSDiagPSTesterTx2 7;
BA_ "GenSigSendType" SG_ 2658967560 SRSDiagPSTesterTx1 7;
BA_ "GenSigSendType" SG_ 2658967559 SRSDiagPSTesterRx1 7;
BA_ "GenSigILSupport" SG_ 2658967559 SRSDiagPSTesterRx1 1;
BA_ "GenSigSendType" SG_ 2671833762 PhysDiagRespSig_F2_A2_ISig_5 7;
BA_ "GenSigSendType" SG_ 2671833752 PhysDiagRespSig_F2_98_ISig_5 7;
BA_ "GenSigSendType" SG_ 2671833683 PhysDiagRespSig_F2_53_ISig_5 7;
BA_ "GenSigSendType" SG_ 2671833638 PhysDiagRespSig_F2_26_ISig_5 7;
BA_ "GenSigSendType" SG_ 2564485459 PhysDiagRespSig_F1_53_ISig_5 7;
BA_ "GenSigSendType" SG_ 2671813362 PhysDiagReqSig_A2_F2_ISig_5 7;
BA_ "GenSigSendType" SG_ 2671810802 PhysDiagReqSig_98_F2_ISig_5 7;
BA_ "GenSigSendType" SG_ 2671793138 PhysDiagReqSig_53_F2_ISig_5 7;
BA_ "GenSigSendType" SG_ 2564445169 PhysDiagReqSig_53_F1_ISig_5 7;
BA_ "GenSigSendType" SG_ 2671781618 PhysDiagReqSig_26_F2_ISig_5 7;
BA_ "GenSigSendType" SG_ 2499772322 MediaSourcesListReq_sg_UB_ISig_5 7;
BA_ "GenSigSendType" SG_ 2499772322 MediaSourcesListReq_SInfo_ISig_5 1;
BA_ "GenSigStartValue" SG_ 2499772322 MediaSourcesListReq_SInfo_ISig_5 3;
BA_ "GenSigMaxLatency" SG_ 2499772322 MediaSourcesListReq_SInfo_ISig_5 100;
BA_ "NeedsUpdateBit" SG_ 2499772322 MediaSourcesListReq_SInfo_ISig_5 1;
BA_ "GenSigSendType" SG_ 2499772322 MediaSourcesListReq_Items_ISig_5 1;
BA_ "GenSigMaxLatency" SG_ 2499772322 MediaSourcesListReq_Items_ISig_5 100;
BA_ "NeedsUpdateBit" SG_ 2499772322 MediaSourcesListReq_Items_ISig_5 1;
BA_ "GenSigSendType" SG_ 2499772322 MediaSourcesListReq_ItemID_ISig_ 1;
BA_ "GenSigMaxLatency" SG_ 2499772322 MediaSourcesListReq_ItemID_ISig_ 100;
BA_ "NeedsUpdateBit" SG_ 2499772322 MediaSourcesListReq_ItemID_ISig_ 1;
BA_ "SystemSignalLongSymbol" SG_ 2499772322 MediaSourcesListReq_ItemID_ISig_ "MediaSourcesListReq_ItemID_ISig_5";
BA_ "GenSigCycleTime" SG_ 2489730210 BunkH1AudioSrcSem_rqst_ISig_5 100;
BA_ "GenSigCycleTimeActive" SG_ 2489730210 BunkH1AudioSrcSem_rqst_ISig_5 100;
BA_ "GenSigStartValue" SG_ 2489730210 BunkH1AudioSrcSem_rqst_ISig_5 15;
BA_ "GenSigSendType" SG_ 2566043647 AlmClkSetAlm_LECM_rq_Type_ISig_5 1;
BA_ "GenSigCycleTime" SG_ 2566043647 AlmClkSetAlm_LECM_rq_Type_ISig_5 100;
BA_ "GenSigCycleTimeActive" SG_ 2566043647 AlmClkSetAlm_LECM_rq_Type_ISig_5 100;
BA_ "GenSigStartValue" SG_ 2566043647 AlmClkSetAlm_LECM_rq_Type_ISig_5 7;
BA_ "GenSigMaxLatency" SG_ 2566043647 AlmClkSetAlm_LECM_rq_Type_ISig_5 220;
BA_ "GenSigSendType" SG_ 2566043647 AlmClkSetAlm_LECM_rq_SetHr_ISig_ 1;
BA_ "GenSigCycleTime" SG_ 2566043647 AlmClkSetAlm_LECM_rq_SetHr_ISig_ 100;
BA_ "GenSigCycleTimeActive" SG_ 2566043647 AlmClkSetAlm_LECM_rq_SetHr_ISig_ 100;
BA_ "GenSigStartValue" SG_ 2566043647 AlmClkSetAlm_LECM_rq_SetHr_ISig_ 31;
BA_ "GenSigMaxLatency" SG_ 2566043647 AlmClkSetAlm_LECM_rq_SetHr_ISig_ 220;
BA_ "SystemSignalLongSymbol" SG_ 2566043647 AlmClkSetAlm_LECM_rq_SetHr_ISig_ "AlmClkSetAlm_LECM_rq_SetHr_ISig_5";
BA_ "GenSigSendType" SG_ 2566043647 AlmClkSnze_LECM_rqst_ID_ISig_5 1;
BA_ "GenSigCycleTime" SG_ 2566043647 AlmClkSnze_LECM_rqst_ID_ISig_5 100;
BA_ "GenSigCycleTimeActive" SG_ 2566043647 AlmClkSnze_LECM_rqst_ID_ISig_5 100;
BA_ "GenSigStartValue" SG_ 2566043647 AlmClkSnze_LECM_rqst_ID_ISig_5 127;
BA_ "GenSigSendType" SG_ 2566043647 AlmClkSetAlm_LECM_rq_DaySet_ISig 1;
BA_ "GenSigCycleTime" SG_ 2566043647 AlmClkSetAlm_LECM_rq_DaySet_ISig 100;
BA_ "GenSigCycleTimeActive" SG_ 2566043647 AlmClkSetAlm_LECM_rq_DaySet_ISig 100;
BA_ "GenSigMaxLatency" SG_ 2566043647 AlmClkSetAlm_LECM_rq_DaySet_ISig 220;
BA_ "SystemSignalLongSymbol" SG_ 2566043647 AlmClkSetAlm_LECM_rq_DaySet_ISig "AlmClkSetAlm_LECM_rq_DaySet_ISig_5";
BA_ "GenSigSendType" SG_ 2566043647 AlmClkSetAlm_LECM_rq_Mode_ISig_5 1;
BA_ "GenSigCycleTime" SG_ 2566043647 AlmClkSetAlm_LECM_rq_Mode_ISig_5 100;
BA_ "GenSigCycleTimeActive" SG_ 2566043647 AlmClkSetAlm_LECM_rq_Mode_ISig_5 100;
BA_ "GenSigMaxLatency" SG_ 2566043647 AlmClkSetAlm_LECM_rq_Mode_ISig_5 220;
BA_ "GenSigSendType" SG_ 2566043647 AlmClkSetAlm_LECM_rq_Stat_ISig_5 1;
BA_ "GenSigCycleTime" SG_ 2566043647 AlmClkSetAlm_LECM_rq_Stat_ISig_5 100;
BA_ "GenSigCycleTimeActive" SG_ 2566043647 AlmClkSetAlm_LECM_rq_Stat_ISig_5 100;
BA_ "GenSigMaxLatency" SG_ 2566043647 AlmClkSetAlm_LECM_rq_Stat_ISig_5 220;
BA_ "GenSigSendType" SG_ 2566043647 AlmClkSetAlm_LECM_rq_SetMin_ISig 1;
BA_ "GenSigCycleTime" SG_ 2566043647 AlmClkSetAlm_LECM_rq_SetMin_ISig 100;
BA_ "GenSigCycleTimeActive" SG_ 2566043647 AlmClkSetAlm_LECM_rq_SetMin_ISig 100;
BA_ "GenSigStartValue" SG_ 2566043647 AlmClkSetAlm_LECM_rq_SetMin_ISig 63;
BA_ "GenSigMaxLatency" SG_ 2566043647 AlmClkSetAlm_LECM_rq_SetMin_ISig 220;
BA_ "SystemSignalLongSymbol" SG_ 2566043647 AlmClkSetAlm_LECM_rq_SetMin_ISig "AlmClkSetAlm_LECM_rq_SetMin_ISig_5";
BA_ "GenSigSendType" SG_ 2566043647 AlmClkSetAlm_LECM_rq_ID_ISig_5 1;
BA_ "GenSigCycleTime" SG_ 2566043647 AlmClkSetAlm_LECM_rq_ID_ISig_5 100;
BA_ "GenSigCycleTimeActive" SG_ 2566043647 AlmClkSetAlm_LECM_rq_ID_ISig_5 100;
BA_ "GenSigStartValue" SG_ 2566043647 AlmClkSetAlm_LECM_rq_ID_ISig_5 127;
BA_ "GenSigMaxLatency" SG_ 2566043647 AlmClkSetAlm_LECM_rq_ID_ISig_5 220;
BA_ "GenSigSendType" SG_ 2566043647 AlmClkSnze_LECM_rqst_Action_ISig 1;
BA_ "GenSigCycleTime" SG_ 2566043647 AlmClkSnze_LECM_rqst_Action_ISig 100;
BA_ "GenSigCycleTimeActive" SG_ 2566043647 AlmClkSnze_LECM_rqst_Action_ISig 100;
BA_ "GenSigStartValue" SG_ 2566043647 AlmClkSnze_LECM_rqst_Action_ISig 7;
BA_ "SystemSignalLongSymbol" SG_ 2566043647 AlmClkSnze_LECM_rqst_Action_ISig "AlmClkSnze_LECM_rqst_Action_ISig_5";
BA_ "GenSigSendType" SG_ 2432693154 BunkH1PowerWinOpenDSBtn_stat_UB_ 7;
BA_ "SystemSignalLongSymbol" SG_ 2432693154 BunkH1PowerWinOpenDSBtn_stat_UB_ "BunkH1PowerWinOpenDSBtn_stat_UB_ISig_5";
BA_ "GenSigCycleTime" SG_ 2432693154 BunkH1RoofhatchOpenBtn_Stat 100;
BA_ "GenSigCycleTimeActive" SG_ 2432693154 BunkH1RoofhatchOpenBtn_Stat 100;
BA_ "GenSigStartValue" SG_ 2432693154 BunkH1RoofhatchOpenBtn_Stat 3;
BA_ "GenSigMaxLatency" SG_ 2432693154 BunkH1RoofhatchOpenBtn_Stat 26;
BA_ "GenSigCycleTime" SG_ 2432693154 BunkH1IntLghtActvnBtn_stat 100;
BA_ "GenSigCycleTimeActive" SG_ 2432693154 BunkH1IntLghtActvnBtn_stat 100;
BA_ "GenSigStartValue" SG_ 2432693154 BunkH1IntLghtActvnBtn_stat 3;
BA_ "GenSigCycleTime" SG_ 2432693154 BunkH1TempDec_ButtonStatus 100;
BA_ "GenSigCycleTimeActive" SG_ 2432693154 BunkH1TempDec_ButtonStatus 100;
BA_ "GenSigStartValue" SG_ 2432693154 BunkH1TempDec_ButtonStatus 3;
BA_ "GenSigMaxLatency" SG_ 2432693154 BunkH1TempDec_ButtonStatus 26;
BA_ "GenSigCycleTime" SG_ 2432693154 BunkH1IntLghtDirAccsUpBtn_stat 100;
BA_ "GenSigCycleTimeActive" SG_ 2432693154 BunkH1IntLghtDirAccsUpBtn_stat 100;
BA_ "GenSigStartValue" SG_ 2432693154 BunkH1IntLghtDirAccsUpBtn_stat 3;
BA_ "GenSigCycleTime" SG_ 2432693154 BunkH1AudioSource_rqst2_ISig_5 100;
BA_ "GenSigCycleTimeActive" SG_ 2432693154 BunkH1AudioSource_rqst2_ISig_5 100;
BA_ "GenSigStartValue" SG_ 2432693154 BunkH1AudioSource_rqst2_ISig_5 15;
BA_ "GenSigCycleTime" SG_ 2432693154 BunkH1AudioOnOff_ButtonStatus_IS 100;
BA_ "GenSigCycleTimeActive" SG_ 2432693154 BunkH1AudioOnOff_ButtonStatus_IS 100;
BA_ "GenSigStartValue" SG_ 2432693154 BunkH1AudioOnOff_ButtonStatus_IS 3;
BA_ "GenSigMaxLatency" SG_ 2432693154 BunkH1AudioOnOff_ButtonStatus_IS 26;
BA_ "SystemSignalLongSymbol" SG_ 2432693154 BunkH1AudioOnOff_ButtonStatus_IS "BunkH1AudioOnOff_ButtonStatus_ISig_5";
BA_ "GenSigCycleTime" SG_ 2432693154 BunkH1RoofhatchCloseBtn_Stat 100;
BA_ "GenSigCycleTimeActive" SG_ 2432693154 BunkH1RoofhatchCloseBtn_Stat 100;
BA_ "GenSigStartValue" SG_ 2432693154 BunkH1RoofhatchCloseBtn_Stat 3;
BA_ "GenSigMaxLatency" SG_ 2432693154 BunkH1RoofhatchCloseBtn_Stat 26;
BA_ "GenSigCycleTime" SG_ 2432693154 BunkH1VolumeUp_ButtonStatus_ISig 100;
BA_ "GenSigCycleTimeActive" SG_ 2432693154 BunkH1VolumeUp_ButtonStatus_ISig 100;
BA_ "GenSigStartValue" SG_ 2432693154 BunkH1VolumeUp_ButtonStatus_ISig 3;
BA_ "GenSigMaxLatency" SG_ 2432693154 BunkH1VolumeUp_ButtonStatus_ISig 26;
BA_ "SystemSignalLongSymbol" SG_ 2432693154 BunkH1VolumeUp_ButtonStatus_ISig "BunkH1VolumeUp_ButtonStatus_ISig_5";
BA_ "GenSigSendType" SG_ 2432693154 BunkH1PowerWinClosePSBtn_stat_UB 7;
BA_ "SystemSignalLongSymbol" SG_ 2432693154 BunkH1PowerWinClosePSBtn_stat_UB "BunkH1PowerWinClosePSBtn_stat_UB_ISig_5";
BA_ "GenSigCycleTime" SG_ 2432693154 BunkH1PowerWinCloseDSBtn_stat_IS 100;
BA_ "GenSigCycleTimeActive" SG_ 2432693154 BunkH1PowerWinCloseDSBtn_stat_IS 100;
BA_ "GenSigStartValue" SG_ 2432693154 BunkH1PowerWinCloseDSBtn_stat_IS 3;
BA_ "GenSigMaxLatency" SG_ 2432693154 BunkH1PowerWinCloseDSBtn_stat_IS 26;
BA_ "NeedsUpdateBit" SG_ 2432693154 BunkH1PowerWinCloseDSBtn_stat_IS 1;
BA_ "SystemSignalLongSymbol" SG_ 2432693154 BunkH1PowerWinCloseDSBtn_stat_IS "BunkH1PowerWinCloseDSBtn_stat_ISig_5";
BA_ "GenSigCycleTime" SG_ 2432693154 BunkH1Prev_ButtonStatus_ISig_5 100;
BA_ "GenSigCycleTimeActive" SG_ 2432693154 BunkH1Prev_ButtonStatus_ISig_5 100;
BA_ "GenSigStartValue" SG_ 2432693154 BunkH1Prev_ButtonStatus_ISig_5 3;
BA_ "GenSigMaxLatency" SG_ 2432693154 BunkH1Prev_ButtonStatus_ISig_5 26;
BA_ "GenSigCycleTime" SG_ 2432693154 BunkH1UnlockButtonStatus 100;
BA_ "GenSigCycleTimeActive" SG_ 2432693154 BunkH1UnlockButtonStatus 100;
BA_ "GenSigStartValue" SG_ 2432693154 BunkH1UnlockButtonStatus 3;
BA_ "GenSigMaxLatency" SG_ 2432693154 BunkH1UnlockButtonStatus 26;
BA_ "GenSigCycleTime" SG_ 2432693154 BunkH1VolumeDown_ButtonStatus_IS 100;
BA_ "GenSigCycleTimeActive" SG_ 2432693154 BunkH1VolumeDown_ButtonStatus_IS 100;
BA_ "GenSigStartValue" SG_ 2432693154 BunkH1VolumeDown_ButtonStatus_IS 3;
BA_ "GenSigMaxLatency" SG_ 2432693154 BunkH1VolumeDown_ButtonStatus_IS 26;
BA_ "SystemSignalLongSymbol" SG_ 2432693154 BunkH1VolumeDown_ButtonStatus_IS "BunkH1VolumeDown_ButtonStatus_ISig_5";
BA_ "GenSigCycleTime" SG_ 2432693154 BunkH1ParkHeaterTimer2_cmd 100;
BA_ "GenSigCycleTimeActive" SG_ 2432693154 BunkH1ParkHeaterTimer2_cmd 100;
BA_ "GenSigStartValue" SG_ 2432693154 BunkH1ParkHeaterTimer2_cmd 7;
BA_ "GenSigMaxLatency" SG_ 2432693154 BunkH1ParkHeaterTimer2_cmd 26;
BA_ "GenSigSendType" SG_ 2432693154 BunkH1PowerWinOpenPSBtn_stat_UB_ 7;
BA_ "SystemSignalLongSymbol" SG_ 2432693154 BunkH1PowerWinOpenPSBtn_stat_UB_ "BunkH1PowerWinOpenPSBtn_stat_UB_ISig_5";
BA_ "GenSigCycleTime" SG_ 2432693154 BunkH1PowerWinOpenDSBtn_stat_ISi 100;
BA_ "GenSigCycleTimeActive" SG_ 2432693154 BunkH1PowerWinOpenDSBtn_stat_ISi 100;
BA_ "GenSigStartValue" SG_ 2432693154 BunkH1PowerWinOpenDSBtn_stat_ISi 3;
BA_ "GenSigMaxLatency" SG_ 2432693154 BunkH1PowerWinOpenDSBtn_stat_ISi 26;
BA_ "NeedsUpdateBit" SG_ 2432693154 BunkH1PowerWinOpenDSBtn_stat_ISi 1;
BA_ "SystemSignalLongSymbol" SG_ 2432693154 BunkH1PowerWinOpenDSBtn_stat_ISi "BunkH1PowerWinOpenDSBtn_stat_ISig_5";
BA_ "GenSigCycleTime" SG_ 2432693154 BunkH1ParkHeater_ButtonStatus 100;
BA_ "GenSigCycleTimeActive" SG_ 2432693154 BunkH1ParkHeater_ButtonStatus 100;
BA_ "GenSigStartValue" SG_ 2432693154 BunkH1ParkHeater_ButtonStatus 3;
BA_ "GenSigMaxLatency" SG_ 2432693154 BunkH1ParkHeater_ButtonStatus 26;
BA_ "GenSigCycleTime" SG_ 2432693154 BunkH1ParkHeaterTimer3_cmd 100;
BA_ "GenSigCycleTimeActive" SG_ 2432693154 BunkH1ParkHeaterTimer3_cmd 100;
BA_ "GenSigStartValue" SG_ 2432693154 BunkH1ParkHeaterTimer3_cmd 7;
BA_ "GenSigMaxLatency" SG_ 2432693154 BunkH1ParkHeaterTimer3_cmd 26;
BA_ "GenSigCycleTime" SG_ 2432693154 BunkH1AudioSource_rqst_ISig_5 100;
BA_ "GenSigCycleTimeActive" SG_ 2432693154 BunkH1AudioSource_rqst_ISig_5 100;
BA_ "GenSigStartValue" SG_ 2432693154 BunkH1AudioSource_rqst_ISig_5 7;
BA_ "GenSigMaxLatency" SG_ 2432693154 BunkH1AudioSource_rqst_ISig_5 26;
BA_ "GenSigCycleTime" SG_ 2432693154 BunkH1Mute_ButtonStatus_ISig_5 100;
BA_ "GenSigCycleTimeActive" SG_ 2432693154 BunkH1Mute_ButtonStatus_ISig_5 100;
BA_ "GenSigStartValue" SG_ 2432693154 BunkH1Mute_ButtonStatus_ISig_5 3;
BA_ "GenSigCycleTime" SG_ 2432693154 BunkH1IntLghtDirAccsDnBtn_stat 100;
BA_ "GenSigCycleTimeActive" SG_ 2432693154 BunkH1IntLghtDirAccsDnBtn_stat 100;
BA_ "GenSigStartValue" SG_ 2432693154 BunkH1IntLghtDirAccsDnBtn_stat 3;
BA_ "GenSigCycleTime" SG_ 2432693154 BunkH1LockButtonStatus 100;
BA_ "GenSigCycleTimeActive" SG_ 2432693154 BunkH1LockButtonStatus 100;
BA_ "GenSigStartValue" SG_ 2432693154 BunkH1LockButtonStatus 3;
BA_ "GenSigMaxLatency" SG_ 2432693154 BunkH1LockButtonStatus 26;
BA_ "GenSigCycleTime" SG_ 2432693154 BunkH1ParkHeaterTimer1_cmd 100;
BA_ "GenSigCycleTimeActive" SG_ 2432693154 BunkH1ParkHeaterTimer1_cmd 100;
BA_ "GenSigStartValue" SG_ 2432693154 BunkH1ParkHeaterTimer1_cmd 7;
BA_ "GenSigMaxLatency" SG_ 2432693154 BunkH1ParkHeaterTimer1_cmd 26;
BA_ "GenSigCycleTime" SG_ 2432693154 BnkH1IntLghtMMenu_stat_IL_Mode 100;
BA_ "GenSigCycleTimeActive" SG_ 2432693154 BnkH1IntLghtMMenu_stat_IL_Mode 100;
BA_ "GenSigStartValue" SG_ 2432693154 BnkH1IntLghtMMenu_stat_IL_Mode 7;
BA_ "GenSigCycleTime" SG_ 2432693154 BunkH1Next_ButtonStatus_ISig_5 100;
BA_ "GenSigCycleTimeActive" SG_ 2432693154 BunkH1Next_ButtonStatus_ISig_5 100;
BA_ "GenSigStartValue" SG_ 2432693154 BunkH1Next_ButtonStatus_ISig_5 3;
BA_ "GenSigMaxLatency" SG_ 2432693154 BunkH1Next_ButtonStatus_ISig_5 26;
BA_ "GenSigSendType" SG_ 2432693154 BunkH1PowerWinCloseDSBtn_stat_UB 7;
BA_ "SystemSignalLongSymbol" SG_ 2432693154 BunkH1PowerWinCloseDSBtn_stat_UB "BunkH1PowerWinCloseDSBtn_stat_UB_ISig_5";
BA_ "GenSigCycleTime" SG_ 2432693154 BnkH1IntLghtMMenu_stat_EventFlag 100;
BA_ "GenSigCycleTimeActive" SG_ 2432693154 BnkH1IntLghtMMenu_stat_EventFlag 100;
BA_ "GenSigCycleTime" SG_ 2432693154 BunkH1PowerWinOpenPSBtn_stat_ISi 100;
BA_ "GenSigCycleTimeActive" SG_ 2432693154 BunkH1PowerWinOpenPSBtn_stat_ISi 100;
BA_ "GenSigStartValue" SG_ 2432693154 BunkH1PowerWinOpenPSBtn_stat_ISi 3;
BA_ "GenSigMaxLatency" SG_ 2432693154 BunkH1PowerWinOpenPSBtn_stat_ISi 26;
BA_ "NeedsUpdateBit" SG_ 2432693154 BunkH1PowerWinOpenPSBtn_stat_ISi 1;
BA_ "SystemSignalLongSymbol" SG_ 2432693154 BunkH1PowerWinOpenPSBtn_stat_ISi "BunkH1PowerWinOpenPSBtn_stat_ISig_5";
BA_ "GenSigCycleTime" SG_ 2432693154 BunkH1PowerWinClosePSBtn_stat_IS 100;
BA_ "GenSigCycleTimeActive" SG_ 2432693154 BunkH1PowerWinClosePSBtn_stat_IS 100;
BA_ "GenSigStartValue" SG_ 2432693154 BunkH1PowerWinClosePSBtn_stat_IS 3;
BA_ "GenSigMaxLatency" SG_ 2432693154 BunkH1PowerWinClosePSBtn_stat_IS 26;
BA_ "NeedsUpdateBit" SG_ 2432693154 BunkH1PowerWinClosePSBtn_stat_IS 1;
BA_ "SystemSignalLongSymbol" SG_ 2432693154 BunkH1PowerWinClosePSBtn_stat_IS "BunkH1PowerWinClosePSBtn_stat_ISig_5";
BA_ "GenSigCycleTime" SG_ 2432693154 BunkH1TempInc_ButtonStatus 100;
BA_ "GenSigCycleTimeActive" SG_ 2432693154 BunkH1TempInc_ButtonStatus 100;
BA_ "GenSigStartValue" SG_ 2432693154 BunkH1TempInc_ButtonStatus 3;
BA_ "GenSigMaxLatency" SG_ 2432693154 BunkH1TempInc_ButtonStatus 26;
BA_ "GenSigSendType" SG_ 2671902708 FuncDiagDataIntTesterTGW2_ISig_5 7;
BA_ "GenSigSendType" SG_ 2671964834 DiagUUDTRespSig_F2_A2_ISig_5 7;
BA_ "GenSigSendType" SG_ 2671964824 DiagUUDTRespSig_F2_98_ISig_5 7;
BA_ "GenSigSendType" SG_ 2671964755 DiagUUDTRespSig_F2_53_ISig_5 7;
BA_ "GenSigSendType" SG_ 2671964710 DiagUUDTRespSig_F2_26_ISig_5 7;
BA_ "GenSigSendType" SG_ 2671834274 InternalTesterDiagSig_F4_A2_ISig 7;
BA_ "SystemSignalLongSymbol" SG_ 2671834274 InternalTesterDiagSig_F4_A2_ISig "InternalTesterDiagSig_F4_A2_ISig_5";
BA_ "GenSigSendType" SG_ 2671834264 InternalTesterDiagSig_F4_98_ISig 7;
BA_ "SystemSignalLongSymbol" SG_ 2671834264 InternalTesterDiagSig_F4_98_ISig "InternalTesterDiagSig_F4_98_ISig_5";
BA_ "GenSigSendType" SG_ 2671834195 InternalTesterDiagSig_F4_53_ISig 7;
BA_ "SystemSignalLongSymbol" SG_ 2671834195 InternalTesterDiagSig_F4_53_ISig "InternalTesterDiagSig_F4_53_ISig_5";
BA_ "GenSigSendType" SG_ 2671834150 InternalTesterDiagSig_F4_26_ISig 7;
BA_ "SystemSignalLongSymbol" SG_ 2671834150 InternalTesterDiagSig_F4_26_ISig "InternalTesterDiagSig_F4_26_ISig_5";
BA_ "GenSigSendType" SG_ 2671834018 InternalTesterDiagSig_F3_A2_ISig 7;
BA_ "SystemSignalLongSymbol" SG_ 2671834018 InternalTesterDiagSig_F3_A2_ISig "InternalTesterDiagSig_F3_A2_ISig_5";
BA_ "GenSigSendType" SG_ 2671834008 InternalTesterDiagSig_F3_98_ISig 7;
BA_ "SystemSignalLongSymbol" SG_ 2671834008 InternalTesterDiagSig_F3_98_ISig "InternalTesterDiagSig_F3_98_ISig_5";
BA_ "GenSigSendType" SG_ 2671833939 InternalTesterDiagSig_F3_53_ISig 7;
BA_ "SystemSignalLongSymbol" SG_ 2671833939 InternalTesterDiagSig_F3_53_ISig "InternalTesterDiagSig_F3_53_ISig_5";
BA_ "GenSigSendType" SG_ 2671833894 InternalTesterDiagSig_F3_26_ISig 7;
BA_ "SystemSignalLongSymbol" SG_ 2671833894 InternalTesterDiagSig_F3_26_ISig "InternalTesterDiagSig_F3_26_ISig_5";
BA_ "GenSigSendType" SG_ 2671813364 InternalTesterDiagSig_A2_F4_ISig 7;
BA_ "SystemSignalLongSymbol" SG_ 2671813364 InternalTesterDiagSig_A2_F4_ISig "InternalTesterDiagSig_A2_F4_ISig_5";
BA_ "GenSigSendType" SG_ 2671810804 InternalTesterDiagSig_98_F4_ISig 7;
BA_ "SystemSignalLongSymbol" SG_ 2671810804 InternalTesterDiagSig_98_F4_ISig "InternalTesterDiagSig_98_F4_ISig_5";
BA_ "GenSigSendType" SG_ 2671793140 InternalTesterDiagSig_53_F4_ISig 7;
BA_ "SystemSignalLongSymbol" SG_ 2671793140 InternalTesterDiagSig_53_F4_ISig "InternalTesterDiagSig_53_F4_ISig_5";
BA_ "GenSigSendType" SG_ 2671781620 InternalTesterDiagSig_26_F4_ISig 7;
BA_ "SystemSignalLongSymbol" SG_ 2671781620 InternalTesterDiagSig_26_F4_ISig "InternalTesterDiagSig_26_F4_ISig_5";
BA_ "GenSigSendType" SG_ 2671813363 InternalTesterDiagSig_A2_F3_ISig 7;
BA_ "SystemSignalLongSymbol" SG_ 2671813363 InternalTesterDiagSig_A2_F3_ISig "InternalTesterDiagSig_A2_F3_ISig_5";
BA_ "GenSigSendType" SG_ 2671810803 InternalTesterDiagSig_98_F3_ISig 7;
BA_ "SystemSignalLongSymbol" SG_ 2671810803 InternalTesterDiagSig_98_F3_ISig "InternalTesterDiagSig_98_F3_ISig_5";
BA_ "GenSigSendType" SG_ 2671793139 InternalTesterDiagSig_53_F3_ISig 7;
BA_ "SystemSignalLongSymbol" SG_ 2671793139 InternalTesterDiagSig_53_F3_ISig "InternalTesterDiagSig_53_F3_ISig_5";
BA_ "GenSigSendType" SG_ 2671781619 InternalTesterDiagSig_26_F3_ISig 7;
BA_ "SystemSignalLongSymbol" SG_ 2671781619 InternalTesterDiagSig_26_F3_ISig "InternalTesterDiagSig_26_F3_ISig_5";
BA_ "GenSigSendType" SG_ 2567057439 DiagFaultStat_WRCS_FailTA_ISig_5 3;
BA_ "NeedsUpdateBit" SG_ 2567057439 DiagFaultStat_WRCS_FailTA_ISig_5 1;
BA_ "GenSigSendType" SG_ 2567057439 DiagFaultStat_WRCS_DtcIdB_ISig_5 3;
BA_ "NeedsUpdateBit" SG_ 2567057439 DiagFaultStat_WRCS_DtcIdB_ISig_5 1;
BA_ "GenSigSendType" SG_ 2567057439 DiagFaultStat_WRCS_sg_UB_ISig_5 7;
BA_ "GenSigSendType" SG_ 2567057439 DiagFaultStat_WRCS_FailTB_ISig_5 3;
BA_ "NeedsUpdateBit" SG_ 2567057439 DiagFaultStat_WRCS_FailTB_ISig_5 1;
BA_ "GenSigSendType" SG_ 2567057439 DiagFaultStat_WRCS_EcuAdr_ISig_5 3;
BA_ "GenSigStartValue" SG_ 2567057439 DiagFaultStat_WRCS_EcuAdr_ISig_5 255;
BA_ "NeedsUpdateBit" SG_ 2567057439 DiagFaultStat_WRCS_EcuAdr_ISig_5 1;
BA_ "GenSigSendType" SG_ 2567057439 DiagFaultStat_WRCS_DtcIdA_ISig_5 3;
BA_ "NeedsUpdateBit" SG_ 2567057439 DiagFaultStat_WRCS_DtcIdA_ISig_5 1;
BA_ "GenSigSendType" SG_ 2567057438 DiagFaultStat_SRS_DtcIdA_ISig_5 3;
BA_ "NeedsUpdateBit" SG_ 2567057438 DiagFaultStat_SRS_DtcIdA_ISig_5 1;
BA_ "GenSigSendType" SG_ 2567057438 DiagFaultStat_SRS_sg_UB_ISig_5 7;
BA_ "GenSigSendType" SG_ 2567057438 DiagFaultStat_SRS_FailTA_ISig_5 3;
BA_ "NeedsUpdateBit" SG_ 2567057438 DiagFaultStat_SRS_FailTA_ISig_5 1;
BA_ "GenSigSendType" SG_ 2567057438 DiagFaultStat_SRS_FailTB_ISig_5 3;
BA_ "NeedsUpdateBit" SG_ 2567057438 DiagFaultStat_SRS_FailTB_ISig_5 1;
BA_ "GenSigSendType" SG_ 2567057438 DiagFaultStat_SRS_DtcIdB_ISig_5 3;
BA_ "NeedsUpdateBit" SG_ 2567057438 DiagFaultStat_SRS_DtcIdB_ISig_5 1;
BA_ "GenSigSendType" SG_ 2567057438 DiagFaultStat_SRS_EcuAdr_ISig_5 3;
BA_ "GenSigStartValue" SG_ 2567057438 DiagFaultStat_SRS_EcuAdr_ISig_5 255;
BA_ "NeedsUpdateBit" SG_ 2567057438 DiagFaultStat_SRS_EcuAdr_ISig_5 1;
BA_ "GenSigSendType" SG_ 2567057437 DiagFaultStat_LECM_DtcIdA_ISig_5 3;
BA_ "NeedsUpdateBit" SG_ 2567057437 DiagFaultStat_LECM_DtcIdA_ISig_5 1;
BA_ "GenSigSendType" SG_ 2567057437 DiagFaultStat_LECM_FailTA_ISig_5 3;
BA_ "NeedsUpdateBit" SG_ 2567057437 DiagFaultStat_LECM_FailTA_ISig_5 1;
BA_ "GenSigSendType" SG_ 2567057437 DiagFaultStat_LECM_FailTB_ISig_5 3;
BA_ "NeedsUpdateBit" SG_ 2567057437 DiagFaultStat_LECM_FailTB_ISig_5 1;
BA_ "GenSigSendType" SG_ 2567057437 DiagFaultStat_LECM_sg_UB_ISig_5 7;
BA_ "GenSigSendType" SG_ 2567057437 DiagFaultStat_LECM_DtcIdB_ISig_5 3;
BA_ "NeedsUpdateBit" SG_ 2567057437 DiagFaultStat_LECM_DtcIdB_ISig_5 1;
BA_ "GenSigSendType" SG_ 2567057437 DiagFaultStat_LECM_EcuAdr_ISig_5 3;
BA_ "GenSigStartValue" SG_ 2567057437 DiagFaultStat_LECM_EcuAdr_ISig_5 255;
BA_ "NeedsUpdateBit" SG_ 2567057437 DiagFaultStat_LECM_EcuAdr_ISig_5 1;
BA_ "GenSigSendType" SG_ 2567057436 DiagFaultStat_CCM_FailTB_ISig_5 3;
BA_ "NeedsUpdateBit" SG_ 2567057436 DiagFaultStat_CCM_FailTB_ISig_5 1;
BA_ "GenSigSendType" SG_ 2567057436 DiagFaultStat_CCM_DtcIdB_ISig_5 3;
BA_ "NeedsUpdateBit" SG_ 2567057436 DiagFaultStat_CCM_DtcIdB_ISig_5 1;
BA_ "GenSigSendType" SG_ 2567057436 DiagFaultStat_CCM_EcuAdr_ISig_5 3;
BA_ "GenSigStartValue" SG_ 2567057436 DiagFaultStat_CCM_EcuAdr_ISig_5 255;
BA_ "NeedsUpdateBit" SG_ 2567057436 DiagFaultStat_CCM_EcuAdr_ISig_5 1;
BA_ "GenSigSendType" SG_ 2567057436 DiagFaultStat_CCM_sg_UB_ISig_5 7;
BA_ "GenSigSendType" SG_ 2567057436 DiagFaultStat_CCM_DtcIdA_ISig_5 3;
BA_ "NeedsUpdateBit" SG_ 2567057436 DiagFaultStat_CCM_DtcIdA_ISig_5 1;
BA_ "GenSigSendType" SG_ 2567057436 DiagFaultStat_CCM_FailTA_ISig_5 3;
BA_ "NeedsUpdateBit" SG_ 2567057436 DiagFaultStat_CCM_FailTA_ISig_5 1;
BA_ "GenSigSendType" SG_ 2634020435 Debug_6_SRS 1;
BA_ "GenSigMaxLatency" SG_ 2634020435 Debug_6_SRS 59;
BA_ "GenSigSendType" SG_ 2634020514 Debug_6_LECM 1;
BA_ "GenSigMaxLatency" SG_ 2634020514 Debug_6_LECM 59;
BA_ "GenSigSendType" SG_ 2634020504 Debug_6_CCM 1;
BA_ "GenSigMaxLatency" SG_ 2634020504 Debug_6_CCM 59;
BA_ "GenSigSendType" SG_ 2634020179 Debug_5_SRS 1;
BA_ "GenSigMaxLatency" SG_ 2634020179 Debug_5_SRS 59;
BA_ "GenSigSendType" SG_ 2634020258 Debug_5_LECM 1;
BA_ "GenSigMaxLatency" SG_ 2634020258 Debug_5_LECM 59;
BA_ "GenSigSendType" SG_ 2634020248 Debug_5_CCM 1;
BA_ "GenSigMaxLatency" SG_ 2634020248 Debug_5_CCM 59;
BA_ "GenSigSendType" SG_ 2634019923 Debug_4_SRS 1;
BA_ "GenSigMaxLatency" SG_ 2634019923 Debug_4_SRS 59;
BA_ "GenSigSendType" SG_ 2634020002 Debug_4_LECM 1;
BA_ "GenSigMaxLatency" SG_ 2634020002 Debug_4_LECM 59;
BA_ "GenSigSendType" SG_ 2634019992 Debug_4_CCM 1;
BA_ "GenSigMaxLatency" SG_ 2634019992 Debug_4_CCM 59;
BA_ "GenSigSendType" SG_ 2634019667 Debug_3_SRS 1;
BA_ "GenSigMaxLatency" SG_ 2634019667 Debug_3_SRS 59;
BA_ "GenSigSendType" SG_ 2634019746 Debug_3_LECM 1;
BA_ "GenSigMaxLatency" SG_ 2634019746 Debug_3_LECM 59;
BA_ "GenSigSendType" SG_ 2634019736 Debug_3_CCM 1;
BA_ "GenSigMaxLatency" SG_ 2634019736 Debug_3_CCM 59;
BA_ "GenSigSendType" SG_ 2634019411 Debug_2_SRS 1;
BA_ "GenSigMaxLatency" SG_ 2634019411 Debug_2_SRS 59;
BA_ "GenSigSendType" SG_ 2634019490 Debug_2_LECM 1;
BA_ "GenSigMaxLatency" SG_ 2634019490 Debug_2_LECM 59;
BA_ "GenSigSendType" SG_ 2634019480 Debug_2_CCM 1;
BA_ "GenSigMaxLatency" SG_ 2634019480 Debug_2_CCM 59;
BA_ "GenSigSendType" SG_ 2634019155 Debug_1_SRS 1;
BA_ "GenSigSendType" SG_ 2634019234 Debug_1_LECM 1;
BA_ "GenSigSendType" SG_ 2634019224 Debug_1_CCM 1;
BA_ "GenSigSendType" SG_ 2566357313 CIOM_Cab_34P_FCS 7;
BA_ "GenSigCycleTime" SG_ 2566357312 GPSData_VehSpeed_ISig_5 100;
BA_ "GenSigCycleTimeActive" SG_ 2566357312 GPSData_VehSpeed_ISig_5 100;
BA_ "GenSigStartValue" SG_ 2566357312 GPSData_VehSpeed_ISig_5 65535;
BA_ "GenSigMaxLatency" SG_ 2566357312 GPSData_VehSpeed_ISig_5 551;
BA_ "NeedsUpdateBit" SG_ 2566357312 GPSData_VehSpeed_ISig_5 1;
BA_ "GenSigCycleTime" SG_ 2566357312 GPSData_HDOP_ISig_5 100;
BA_ "GenSigCycleTimeActive" SG_ 2566357312 GPSData_HDOP_ISig_5 100;
BA_ "GenSigMaxLatency" SG_ 2566357312 GPSData_HDOP_ISig_5 551;
BA_ "NeedsUpdateBit" SG_ 2566357312 GPSData_HDOP_ISig_5 1;
BA_ "GenSigCycleTime" SG_ 2566357312 GPSData_Direction_ISig_5 100;
BA_ "GenSigCycleTimeActive" SG_ 2566357312 GPSData_Direction_ISig_5 100;
BA_ "GenSigMaxLatency" SG_ 2566357312 GPSData_Direction_ISig_5 551;
BA_ "NeedsUpdateBit" SG_ 2566357312 GPSData_Direction_ISig_5 1;
BA_ "GenSigCycleTime" SG_ 2566357312 GPSData_Longitude_ISig_5 100;
BA_ "GenSigCycleTimeActive" SG_ 2566357312 GPSData_Longitude_ISig_5 100;
BA_ "GenSigStartValue" SG_ 2566357312 GPSData_Longitude_ISig_5 4294967295;
BA_ "GenSigMaxLatency" SG_ 2566357312 GPSData_Longitude_ISig_5 551;
BA_ "NeedsUpdateBit" SG_ 2566357312 GPSData_Longitude_ISig_5 1;
BA_ "GenSigCycleTime" SG_ 2566357312 GPSData_AntennaStat_ISig_5 100;
BA_ "GenSigCycleTimeActive" SG_ 2566357312 GPSData_AntennaStat_ISig_5 100;
BA_ "GenSigStartValue" SG_ 2566357312 GPSData_AntennaStat_ISig_5 7;
BA_ "GenSigMaxLatency" SG_ 2566357312 GPSData_AntennaStat_ISig_5 551;
BA_ "NeedsUpdateBit" SG_ 2566357312 GPSData_AntennaStat_ISig_5 1;
BA_ "GenSigCycleTime" SG_ 2566357312 GPSData_Latitude_ISig_5 100;
BA_ "GenSigCycleTimeActive" SG_ 2566357312 GPSData_Latitude_ISig_5 100;
BA_ "GenSigStartValue" SG_ 2566357312 GPSData_Latitude_ISig_5 4294967295;
BA_ "GenSigMaxLatency" SG_ 2566357312 GPSData_Latitude_ISig_5 551;
BA_ "NeedsUpdateBit" SG_ 2566357312 GPSData_Latitude_ISig_5 1;
BA_ "GenSigSendType" SG_ 2566357312 GPSData_sg_UB_ISig_5 7;
BA_ "GenSigCycleTime" SG_ 2566357312 GPSData_Altitude_ISig_5 100;
BA_ "GenSigCycleTimeActive" SG_ 2566357312 GPSData_Altitude_ISig_5 100;
BA_ "GenSigStartValue" SG_ 2566357312 GPSData_Altitude_ISig_5 65535;
BA_ "GenSigMaxLatency" SG_ 2566357312 GPSData_Altitude_ISig_5 551;
BA_ "NeedsUpdateBit" SG_ 2566357312 GPSData_Altitude_ISig_5 1;
BA_ "GenSigCycleTime" SG_ 2566357312 GPSData_Time_ISig_5 100;
BA_ "GenSigCycleTimeActive" SG_ 2566357312 GPSData_Time_ISig_5 100;
BA_ "GenSigStartValue" SG_ 2566357312 GPSData_Time_ISig_5 4294967295;
BA_ "GenSigMaxLatency" SG_ 2566357312 GPSData_Time_ISig_5 551;
BA_ "NeedsUpdateBit" SG_ 2566357312 GPSData_Time_ISig_5 1;
BA_ "GenSigCycleTime" SG_ 2432680000 BrakePedalPosition_ISig_5 100;
BA_ "GenSigCycleTimeActive" SG_ 2432680000 BrakePedalPosition_ISig_5 100;
BA_ "GenSigStartValue" SG_ 2432680000 BrakePedalPosition_ISig_5 255;
BA_ "GenSigMaxLatency" SG_ 2432680000 BrakePedalPosition_ISig_5 36;
BA_ "SeToolAncestorID_SIGNAL" SG_ 2432680000 BrakePedalPosition_ISig_5 "x0000001D04104A99";
BA_ "SeToolItemID_SIGNAL" SG_ 2432680000 BrakePedalPosition_ISig_5 "x0000001D04104A99";
BA_ "SeToolName_SIGNAL" SG_ 2432680000 BrakePedalPosition_ISig_5 "BrakePedalPosition";
BA_ "SeToolVersion_SIGNAL" SG_ 2432680000 BrakePedalPosition_ISig_5 "1";
BA_ "GenSigCycleTime" SG_ 2432680000 SteeringWheelAngle_ISig_5 100;
BA_ "GenSigCycleTimeActive" SG_ 2432680000 SteeringWheelAngle_ISig_5 100;
BA_ "GenSigStartValue" SG_ 2432680000 SteeringWheelAngle_ISig_5 65535;
BA_ "GenSigMaxLatency" SG_ 2432680000 SteeringWheelAngle_ISig_5 36;
BA_ "SeToolAncestorID_SIGNAL" SG_ 2432680000 SteeringWheelAngle_ISig_5 "x0000001D041258E9";
BA_ "SeToolItemID_SIGNAL" SG_ 2432680000 SteeringWheelAngle_ISig_5 "x0000001D041258E9";
BA_ "SeToolName_SIGNAL" SG_ 2432680000 SteeringWheelAngle_ISig_5 "SteeringWheelAngle";
BA_ "SeToolVersion_SIGNAL" SG_ 2432680000 SteeringWheelAngle_ISig_5 "1";
BA_ "GenSigCycleTime" SG_ 2432647232 CM_Status_ISig_5 100;
BA_ "GenSigCycleTimeActive" SG_ 2432647232 CM_Status_ISig_5 100;
BA_ "GenSigStartValue" SG_ 2432647232 CM_Status_ISig_5 7;
BA_ "GenSigMaxLatency" SG_ 2432647232 CM_Status_ISig_5 26;
BA_ "SeToolAncestorID_SIGNAL" SG_ 2432647232 CM_Status_ISig_5 "x0000001D0417D4DA";
BA_ "SeToolItemID_SIGNAL" SG_ 2432647232 CM_Status_ISig_5 "x0000001D0428BE35";
BA_ "SeToolName_SIGNAL" SG_ 2432647232 CM_Status_ISig_5 "CM_Status";
BA_ "SeToolVersion_SIGNAL" SG_ 2432647232 CM_Status_ISig_5 "2";
BA_ "GenSigCycleTime" SG_ 2516193600 ActualDrvlnRetdrPercentTorque_IS 100;
BA_ "GenSigCycleTimeActive" SG_ 2516193600 ActualDrvlnRetdrPercentTorque_IS 100;
BA_ "GenSigStartValue" SG_ 2516193600 ActualDrvlnRetdrPercentTorque_IS 255;
BA_ "SeToolAncestorID_SIGNAL" SG_ 2516193600 ActualDrvlnRetdrPercentTorque_IS "x0000001D0410CFDE";
BA_ "SeToolItemID_SIGNAL" SG_ 2516193600 ActualDrvlnRetdrPercentTorque_IS "x0000001D0410CFDE";
BA_ "SeToolName_SIGNAL" SG_ 2516193600 ActualDrvlnRetdrPercentTorque_IS "ActualDrivelineRetarderPercentTorque";
BA_ "SeToolVersion_SIGNAL" SG_ 2516193600 ActualDrvlnRetdrPercentTorque_IS "1";
BA_ "SystemSignalLongSymbol" SG_ 2516193600 ActualDrvlnRetdrPercentTorque_IS "ActualDrvlnRetdrPercentTorque_ISig_5";
BA_ "GenSigCycleTime" SG_ 2516193600 ROPBrakeControlActive_ISig_5 100;
BA_ "GenSigCycleTimeActive" SG_ 2516193600 ROPBrakeControlActive_ISig_5 100;
BA_ "GenSigStartValue" SG_ 2516193600 ROPBrakeControlActive_ISig_5 3;
BA_ "NeedsUpdateBit" SG_ 2516193600 ROPBrakeControlActive_ISig_5 1;
BA_ "GenSigCycleTime" SG_ 2516193600 FoundationBrakeUse_ISig_5 100;
BA_ "GenSigCycleTimeActive" SG_ 2516193600 FoundationBrakeUse_ISig_5 100;
BA_ "GenSigStartValue" SG_ 2516193600 FoundationBrakeUse_ISig_5 3;
BA_ "SeToolAncestorID_SIGNAL" SG_ 2516193600 FoundationBrakeUse_ISig_5 "x0000001D04149A2F";
BA_ "SeToolItemID_SIGNAL" SG_ 2516193600 FoundationBrakeUse_ISig_5 "x0000001D043574DF";
BA_ "SeToolName_SIGNAL" SG_ 2516193600 FoundationBrakeUse_ISig_5 "FoundationBrakeUse";
BA_ "SeToolVersion_SIGNAL" SG_ 2516193600 FoundationBrakeUse_ISig_5 "2";
BA_ "GenSigSendType" SG_ 2516193600 YCBrakeControlActive_UB_ISig_5 7;
BA_ "GenSigCycleTime" SG_ 2516193600 YCBrakeControlActive_ISig_5 100;
BA_ "GenSigCycleTimeActive" SG_ 2516193600 YCBrakeControlActive_ISig_5 100;
BA_ "GenSigStartValue" SG_ 2516193600 YCBrakeControlActive_ISig_5 3;
BA_ "NeedsUpdateBit" SG_ 2516193600 YCBrakeControlActive_ISig_5 1;
BA_ "GenSigCycleTime" SG_ 2516193600 ActualEngineRetarderPercentTrq_I 100;
BA_ "GenSigCycleTimeActive" SG_ 2516193600 ActualEngineRetarderPercentTrq_I 100;
BA_ "GenSigStartValue" SG_ 2516193600 ActualEngineRetarderPercentTrq_I 255;
BA_ "SeToolAncestorID_SIGNAL" SG_ 2516193600 ActualEngineRetarderPercentTrq_I "x0000001D0410BAE1";
BA_ "SeToolItemID_SIGNAL" SG_ 2516193600 ActualEngineRetarderPercentTrq_I "x0000001D043C302E";
BA_ "SeToolName_SIGNAL" SG_ 2516193600 ActualEngineRetarderPercentTrq_I "ActualEngineRetarderPercentTorque";
BA_ "SeToolVersion_SIGNAL" SG_ 2516193600 ActualEngineRetarderPercentTrq_I "2";
BA_ "SystemSignalLongSymbol" SG_ 2516193600 ActualEngineRetarderPercentTrq_I "ActualEngineRetarderPercentTrq_ISig_5";
BA_ "GenSigSendType" SG_ 2516193600 ROPBrakeControlActive_UB_ISig_5 7;
BA_ "GenSigCycleTime" SG_ 2516193600 AntiLockBrakingActive_ISig_5 100;
BA_ "GenSigCycleTimeActive" SG_ 2516193600 AntiLockBrakingActive_ISig_5 100;
BA_ "GenSigStartValue" SG_ 2516193600 AntiLockBrakingActive_ISig_5 3;
BA_ "SeToolAncestorID_SIGNAL" SG_ 2516193600 AntiLockBrakingActive_ISig_5 "x0000001D0410DB7B";
BA_ "SeToolItemID_SIGNAL" SG_ 2516193600 AntiLockBrakingActive_ISig_5 "x0000001D0410DB7B";
BA_ "SeToolName_SIGNAL" SG_ 2516193600 AntiLockBrakingActive_ISig_5 "Anti-LockBraking(ABS)Active";
BA_ "SeToolVersion_SIGNAL" SG_ 2516193600 AntiLockBrakingActive_ISig_5 "1";
BA_ "GenSigSendType" SG_ 2566357057 CIOM_Cab_30S_FCS 7;
BA_ "GenSigSendType" SG_ 2566357056 SEM_DisplayText_stat_ISig_5 1;
BA_ "GenSigMaxLatency" SG_ 2566357056 SEM_DisplayText_stat_ISig_5 200;
BA_ "GenSigSendType" SG_ 2432679745 CIOM_Cab_29S_FCS 7;
BA_ "GenSigSendType" SG_ 2432679744 MediaSourcesListRsp_SrcAttrib_IS 1;
BA_ "GenSigMaxLatency" SG_ 2432679744 MediaSourcesListRsp_SrcAttrib_IS 50;
BA_ "NeedsUpdateBit" SG_ 2432679744 MediaSourcesListRsp_SrcAttrib_IS 1;
BA_ "SystemSignalLongSymbol" SG_ 2432679744 MediaSourcesListRsp_SrcAttrib_IS "MediaSourcesListRsp_SrcAttrib_ISig_5";
BA_ "GenSigSendType" SG_ 2432679744 MediaSourcesListRsp_ItemID_ISig_ 1;
BA_ "GenSigMaxLatency" SG_ 2432679744 MediaSourcesListRsp_ItemID_ISig_ 50;
BA_ "NeedsUpdateBit" SG_ 2432679744 MediaSourcesListRsp_ItemID_ISig_ 1;
BA_ "SystemSignalLongSymbol" SG_ 2432679744 MediaSourcesListRsp_ItemID_ISig_ "MediaSourcesListRsp_ItemID_ISig_5";
BA_ "GenSigSendType" SG_ 2432679744 MediaSourcesListRsp_Name_ISig_5 1;
BA_ "GenSigMaxLatency" SG_ 2432679744 MediaSourcesListRsp_Name_ISig_5 50;
BA_ "NeedsUpdateBit" SG_ 2432679744 MediaSourcesListRsp_Name_ISig_5 1;
BA_ "GenSigSendType" SG_ 2432679744 MediaSourcesListRsp_SInfo_ISig_5 1;
BA_ "GenSigStartValue" SG_ 2432679744 MediaSourcesListRsp_SInfo_ISig_5 3;
BA_ "GenSigMaxLatency" SG_ 2432679744 MediaSourcesListRsp_SInfo_ISig_5 50;
BA_ "NeedsUpdateBit" SG_ 2432679744 MediaSourcesListRsp_SInfo_ISig_5 1;
BA_ "GenSigSendType" SG_ 2432679744 MediaSourcesListRsp_PCI_ISig_5 1;
BA_ "GenSigMaxLatency" SG_ 2432679744 MediaSourcesListRsp_PCI_ISig_5 50;
BA_ "NeedsUpdateBit" SG_ 2432679744 MediaSourcesListRsp_PCI_ISig_5 1;
BA_ "GenSigSendType" SG_ 2432679744 MediaSourcesListRsp_sg_UB_ISig_5 7;
BA_ "GenSigSendType" SG_ 2432646976 MediaSourcesListNPRsp_ISig_5 1;
BA_ "GenSigCycleTime" SG_ 2432646976 MediaSourcesListNPRsp_ISig_5 100;
BA_ "GenSigCycleTimeActive" SG_ 2432646976 MediaSourcesListNPRsp_ISig_5 100;
BA_ "GenSigMaxLatency" SG_ 2432646976 MediaSourcesListNPRsp_ISig_5 30;
BA_ "NeedsUpdateBit" SG_ 2432646976 MediaSourcesListNPRsp_ISig_5 1;
BA_ "GenSigSendType" SG_ 2432646976 MediaSourcesListNPRsp_UB_ISig_5 7;
BA_ "GenSigCycleTime" SG_ 2493989952 SEMMediaSourceAvail_Source07_ISi 100;
BA_ "GenSigCycleTimeActive" SG_ 2493989952 SEMMediaSourceAvail_Source07_ISi 100;
BA_ "SystemSignalLongSymbol" SG_ 2493989952 SEMMediaSourceAvail_Source07_ISi "SEMMediaSourceAvail_Source07_ISig_5";
BA_ "GenSigCycleTime" SG_ 2493989952 SEMMediaSourceAvail_Source06_ISi 100;
BA_ "GenSigCycleTimeActive" SG_ 2493989952 SEMMediaSourceAvail_Source06_ISi 100;
BA_ "SystemSignalLongSymbol" SG_ 2493989952 SEMMediaSourceAvail_Source06_ISi "SEMMediaSourceAvail_Source06_ISig_5";
BA_ "GenSigCycleTime" SG_ 2493989952 SEMMediaSourceAvail_Source08_ISi 100;
BA_ "GenSigCycleTimeActive" SG_ 2493989952 SEMMediaSourceAvail_Source08_ISi 100;
BA_ "SystemSignalLongSymbol" SG_ 2493989952 SEMMediaSourceAvail_Source08_ISi "SEMMediaSourceAvail_Source08_ISig_5";
BA_ "GenSigCycleTime" SG_ 2493989952 SEMMediaSourceAvail_Source00_ISi 100;
BA_ "GenSigCycleTimeActive" SG_ 2493989952 SEMMediaSourceAvail_Source00_ISi 100;
BA_ "SystemSignalLongSymbol" SG_ 2493989952 SEMMediaSourceAvail_Source00_ISi "SEMMediaSourceAvail_Source00_ISig_5";
BA_ "GenSigCycleTime" SG_ 2493989952 SEM_AudioMuteStat_ISig_5 100;
BA_ "GenSigCycleTimeActive" SG_ 2493989952 SEM_AudioMuteStat_ISig_5 100;
BA_ "GenSigStartValue" SG_ 2493989952 SEM_AudioMuteStat_ISig_5 7;
BA_ "GenSigCycleTime" SG_ 2493989952 SEMMediaSourceAvail_Source09_ISi 100;
BA_ "GenSigCycleTimeActive" SG_ 2493989952 SEMMediaSourceAvail_Source09_ISi 100;
BA_ "SystemSignalLongSymbol" SG_ 2493989952 SEMMediaSourceAvail_Source09_ISi "SEMMediaSourceAvail_Source09_ISig_5";
BA_ "GenSigCycleTime" SG_ 2493989952 SEMMediaSourceAvail_Source13_ISi 100;
BA_ "GenSigCycleTimeActive" SG_ 2493989952 SEMMediaSourceAvail_Source13_ISi 100;
BA_ "SystemSignalLongSymbol" SG_ 2493989952 SEMMediaSourceAvail_Source13_ISi "SEMMediaSourceAvail_Source13_ISig_5";
BA_ "GenSigCycleTime" SG_ 2493989952 SEMMediaSourceAvail_Source04_ISi 100;
BA_ "GenSigCycleTimeActive" SG_ 2493989952 SEMMediaSourceAvail_Source04_ISi 100;
BA_ "SystemSignalLongSymbol" SG_ 2493989952 SEMMediaSourceAvail_Source04_ISi "SEMMediaSourceAvail_Source04_ISig_5";
BA_ "GenSigCycleTime" SG_ 2493989952 SEMMediaSourceAvail_Source05_ISi 100;
BA_ "GenSigCycleTimeActive" SG_ 2493989952 SEMMediaSourceAvail_Source05_ISi 100;
BA_ "SystemSignalLongSymbol" SG_ 2493989952 SEMMediaSourceAvail_Source05_ISi "SEMMediaSourceAvail_Source05_ISig_5";
BA_ "GenSigCycleTime" SG_ 2493989952 SEMMediaSourceAvail_Source02_ISi 100;
BA_ "GenSigCycleTimeActive" SG_ 2493989952 SEMMediaSourceAvail_Source02_ISi 100;
BA_ "SystemSignalLongSymbol" SG_ 2493989952 SEMMediaSourceAvail_Source02_ISi "SEMMediaSourceAvail_Source02_ISig_5";
BA_ "GenSigCycleTime" SG_ 2493989952 SEMMediaSourceAvail_SInfo_ISig_5 100;
BA_ "GenSigCycleTimeActive" SG_ 2493989952 SEMMediaSourceAvail_SInfo_ISig_5 100;
BA_ "GenSigStartValue" SG_ 2493989952 SEMMediaSourceAvail_SInfo_ISig_5 3;
BA_ "GenSigCycleTime" SG_ 2493989952 AudioSourceStat_ISig_5 100;
BA_ "GenSigCycleTimeActive" SG_ 2493989952 AudioSourceStat_ISig_5 100;
BA_ "GenSigStartValue" SG_ 2493989952 AudioSourceStat_ISig_5 15;
BA_ "GenSigCycleTime" SG_ 2493989952 SEMMediaSourceAvail_Source11_ISi 100;
BA_ "GenSigCycleTimeActive" SG_ 2493989952 SEMMediaSourceAvail_Source11_ISi 100;
BA_ "SystemSignalLongSymbol" SG_ 2493989952 SEMMediaSourceAvail_Source11_ISi "SEMMediaSourceAvail_Source11_ISig_5";
BA_ "GenSigCycleTime" SG_ 2493989952 SEMMediaSourceAvail_Source10_ISi 100;
BA_ "GenSigCycleTimeActive" SG_ 2493989952 SEMMediaSourceAvail_Source10_ISi 100;
BA_ "SystemSignalLongSymbol" SG_ 2493989952 SEMMediaSourceAvail_Source10_ISi "SEMMediaSourceAvail_Source10_ISig_5";
BA_ "GenSigCycleTime" SG_ 2493989952 SEM_AudioVolValIndCmd_ISig_5 100;
BA_ "GenSigCycleTimeActive" SG_ 2493989952 SEM_AudioVolValIndCmd_ISig_5 100;
BA_ "GenSigCycleTime" SG_ 2493989952 SEMMediaSourceAvail_Source01_ISi 100;
BA_ "GenSigCycleTimeActive" SG_ 2493989952 SEMMediaSourceAvail_Source01_ISi 100;
BA_ "SystemSignalLongSymbol" SG_ 2493989952 SEMMediaSourceAvail_Source01_ISi "SEMMediaSourceAvail_Source01_ISig_5";
BA_ "GenSigCycleTime" SG_ 2493989952 SEMMediaSourceAvail_Source03_ISi 100;
BA_ "GenSigCycleTimeActive" SG_ 2493989952 SEMMediaSourceAvail_Source03_ISi 100;
BA_ "SystemSignalLongSymbol" SG_ 2493989952 SEMMediaSourceAvail_Source03_ISi "SEMMediaSourceAvail_Source03_ISig_5";
BA_ "GenSigCycleTime" SG_ 2493989952 SEM_PresetIndicationCmd_ISig_5 100;
BA_ "GenSigCycleTimeActive" SG_ 2493989952 SEM_PresetIndicationCmd_ISig_5 100;
BA_ "GenSigStartValue" SG_ 2493989952 SEM_PresetIndicationCmd_ISig_5 63;
BA_ "GenSigCycleTime" SG_ 2493989952 SEMMediaSourceAvail_Source12_ISi 100;
BA_ "GenSigCycleTimeActive" SG_ 2493989952 SEMMediaSourceAvail_Source12_ISi 100;
BA_ "SystemSignalLongSymbol" SG_ 2493989952 SEMMediaSourceAvail_Source12_ISi "SEMMediaSourceAvail_Source12_ISig_5";
BA_ "GenSigCycleTime" SG_ 2499754560 TipperEmergencyStopStatus_ISig_5 100;
BA_ "GenSigCycleTimeActive" SG_ 2499754560 TipperEmergencyStopStatus_ISig_5 100;
BA_ "GenSigStartValue" SG_ 2499754560 TipperEmergencyStopStatus_ISig_5 7;
BA_ "GenSigCycleTime" SG_ 2499754560 TipperPrimaryBodyStatus_ISig_5 100;
BA_ "GenSigCycleTimeActive" SG_ 2499754560 TipperPrimaryBodyStatus_ISig_5 100;
BA_ "GenSigStartValue" SG_ 2499754560 TipperPrimaryBodyStatus_ISig_5 7;
BA_ "GenSigCycleTime" SG_ 2499754560 TipperConditionsStatus_ISig_5 100;
BA_ "GenSigCycleTimeActive" SG_ 2499754560 TipperConditionsStatus_ISig_5 100;
BA_ "GenSigStartValue" SG_ 2499754560 TipperConditionsStatus_ISig_5 3;
BA_ "GenSigMaxLatency" SG_ 2499754560 TipperConditionsStatus_ISig_5 65;
BA_ "GenSigCycleTime" SG_ 2499754560 TipperSecondaryBodyStatus_ISig_5 100;
BA_ "GenSigCycleTimeActive" SG_ 2499754560 TipperSecondaryBodyStatus_ISig_5 100;
BA_ "GenSigStartValue" SG_ 2499754560 TipperSecondaryBodyStatus_ISig_5 7;
BA_ "GenSigCycleTime" SG_ 2499754560 BatterySOCAlert_rqst_ISig_5 100;
BA_ "GenSigCycleTimeActive" SG_ 2499754560 BatterySOCAlert_rqst_ISig_5 100;
BA_ "GenSigStartValue" SG_ 2499754560 BatterySOCAlert_rqst_ISig_5 7;
BA_ "GenSigCycleTime" SG_ 2499754560 CCStates_ISig_5 100;
BA_ "GenSigCycleTimeActive" SG_ 2499754560 CCStates_ISig_5 100;
BA_ "GenSigStartValue" SG_ 2499754560 CCStates_ISig_5 15;
BA_ "GenSigMaxLatency" SG_ 2499754560 CCStates_ISig_5 40;
BA_ "GenSigCycleTime" SG_ 2499754560 LongMotionDirection_ISig_5 100;
BA_ "GenSigCycleTimeActive" SG_ 2499754560 LongMotionDirection_ISig_5 100;
BA_ "GenSigStartValue" SG_ 2499754560 LongMotionDirection_ISig_5 7;
BA_ "GenSigCycleTime" SG_ 2499754560 TipperUpDownStatus_ISig_5 100;
BA_ "GenSigCycleTimeActive" SG_ 2499754560 TipperUpDownStatus_ISig_5 100;
BA_ "GenSigStartValue" SG_ 2499754560 TipperUpDownStatus_ISig_5 7;
BA_ "GenSigMaxLatency" SG_ 2499754560 TipperUpDownStatus_ISig_5 65;
BA_ "GenSigCycleTime" SG_ 2499754560 TipperTailGateStatus_ISig_5 100;
BA_ "GenSigCycleTimeActive" SG_ 2499754560 TipperTailGateStatus_ISig_5 100;
BA_ "GenSigStartValue" SG_ 2499754560 TipperTailGateStatus_ISig_5 7;
BA_ "GenSigMaxLatency" SG_ 2499754560 TipperTailGateStatus_ISig_5 65;
BA_ "GenSigCycleTime" SG_ 2499754560 KneelingInformation_ISig_5 100;
BA_ "GenSigCycleTimeActive" SG_ 2499754560 KneelingInformation_ISig_5 100;
BA_ "GenSigStartValue" SG_ 2499754560 KneelingInformation_ISig_5 15;
BA_ "GenSigCycleTime" SG_ 2499754560 TailLiftRemoteNotAllowed_ISig_5 100;
BA_ "GenSigCycleTimeActive" SG_ 2499754560 TailLiftRemoteNotAllowed_ISig_5 100;
BA_ "GenSigStartValue" SG_ 2499754560 TailLiftRemoteNotAllowed_ISig_5 3;
BA_ "GenSigMaxLatency" SG_ 2499754560 TailLiftRemoteNotAllowed_ISig_5 65;
BA_ "GenSigCycleTime" SG_ 2499754560 TipperTarpaulinStatus_ISig_5 100;
BA_ "GenSigCycleTimeActive" SG_ 2499754560 TipperTarpaulinStatus_ISig_5 100;
BA_ "GenSigStartValue" SG_ 2499754560 TipperTarpaulinStatus_ISig_5 7;
BA_ "GenSigMaxLatency" SG_ 2499754560 TipperTarpaulinStatus_ISig_5 65;
BA_ "GenSigCycleTime" SG_ 2499754560 TailLiftConditionsStatus_ISig_5 100;
BA_ "GenSigCycleTimeActive" SG_ 2499754560 TailLiftConditionsStatus_ISig_5 100;
BA_ "GenSigStartValue" SG_ 2499754560 TailLiftConditionsStatus_ISig_5 3;
BA_ "GenSigMaxLatency" SG_ 2499754560 TailLiftConditionsStatus_ISig_5 65;
BA_ "GenSigCycleTime" SG_ 2499754560 InhibitWRCECSMenuCmd 100;
BA_ "GenSigCycleTimeActive" SG_ 2499754560 InhibitWRCECSMenuCmd 100;
BA_ "GenSigStartValue" SG_ 2499754560 InhibitWRCECSMenuCmd 3;
BA_ "GenSigMaxLatency" SG_ 2499754560 InhibitWRCECSMenuCmd 65;
BA_ "GenSigCycleTime" SG_ 2499754560 ExtraHeating_rqst_ISig_5 100;
BA_ "GenSigCycleTimeActive" SG_ 2499754560 ExtraHeating_rqst_ISig_5 100;
BA_ "GenSigStartValue" SG_ 2499754560 ExtraHeating_rqst_ISig_5 7;
BA_ "GenSigCycleTime" SG_ 2499754560 ShortStopHeater_status_ISig_5 100;
BA_ "GenSigCycleTimeActive" SG_ 2499754560 ShortStopHeater_status_ISig_5 100;
BA_ "GenSigStartValue" SG_ 2499754560 ShortStopHeater_status_ISig_5 7;
BA_ "GenSigCycleTime" SG_ 2499754560 LongMotionDirectionQual_ISig_5 100;
BA_ "GenSigCycleTimeActive" SG_ 2499754560 LongMotionDirectionQual_ISig_5 100;
BA_ "GenSigStartValue" SG_ 2499754560 LongMotionDirectionQual_ISig_5 3;
BA_ "GenSigCycleTime" SG_ 2499754560 TipperShakerStatus_ISig_5 100;
BA_ "GenSigCycleTimeActive" SG_ 2499754560 TipperShakerStatus_ISig_5 100;
BA_ "GenSigStartValue" SG_ 2499754560 TipperShakerStatus_ISig_5 3;
BA_ "GenSigMaxLatency" SG_ 2499754560 TipperShakerStatus_ISig_5 65;
BA_ "GenSigCycleTime" SG_ 2499754560 TailLiftMotionStatus_ISig_5 100;
BA_ "GenSigCycleTimeActive" SG_ 2499754560 TailLiftMotionStatus_ISig_5 100;
BA_ "GenSigStartValue" SG_ 2499754560 TailLiftMotionStatus_ISig_5 7;
BA_ "GenSigMaxLatency" SG_ 2499754560 TailLiftMotionStatus_ISig_5 65;
BA_ "GenSigSendType" SG_ 2566356801 CIOM_Cab_25S_FCS 7;
BA_REL_ "GenSigFirstTimeoutTime" BU_SG_REL_ CIOM SG_ 2499772198 TipperTarpaulinRequest_ISig_5 3000;
BA_REL_ "GenSigTimeoutTime" BU_SG_REL_ CIOM SG_ 2499772198 TipperTarpaulinRequest_ISig_5 500;
BA_REL_ "GenSigFirstTimeoutTime" BU_SG_REL_ CIOM SG_ 2499772198 TipperUpDownRequest_ISig_5 3000;
BA_REL_ "GenSigTimeoutTime" BU_SG_REL_ CIOM SG_ 2499772198 TipperUpDownRequest_ISig_5 500;
BA_REL_ "GenSigFirstTimeoutTime" BU_SG_REL_ CIOM SG_ 2499772198 TailLiftMotionRequest_ISig_5 3000;
BA_REL_ "GenSigTimeoutTime" BU_SG_REL_ CIOM SG_ 2499772198 TailLiftMotionRequest_ISig_5 500;
BA_REL_ "GenSigFirstTimeoutTime" BU_SG_REL_ CIOM SG_ 2499772198 TipperEmergencyStop_ISig_5 3000;
BA_REL_ "GenSigTimeoutTime" BU_SG_REL_ CIOM SG_ 2499772198 TipperEmergencyStop_ISig_5 500;
BA_REL_ "GenSigFirstTimeoutTime" BU_SG_REL_ CIOM SG_ 2499772198 ExtraBbWrcWatchdog_ISig_5 3000;
BA_REL_ "GenSigTimeoutTime" BU_SG_REL_ CIOM SG_ 2499772198 ExtraBbWrcWatchdog_ISig_5 500;
BA_REL_ "GenSigFirstTimeoutTime" BU_SG_REL_ CIOM SG_ 2499772198 TipperTailGateRequest_ISig_5 3000;
BA_REL_ "GenSigTimeoutTime" BU_SG_REL_ CIOM SG_ 2499772198 TipperTailGateRequest_ISig_5 500;
BA_REL_ "GenSigFirstTimeoutTime" BU_SG_REL_ CIOM SG_ 2499772198 TipperTippingBodySelection_ISig_ 3000;
BA_REL_ "GenSigTimeoutTime" BU_SG_REL_ CIOM SG_ 2499772198 TipperTippingBodySelection_ISig_ 500;
BA_REL_ "GenSigFirstTimeoutTime" BU_SG_REL_ CIOM SG_ 2499772198 TipperShakerRequest_ISig_5 3000;
BA_REL_ "GenSigTimeoutTime" BU_SG_REL_ CIOM SG_ 2499772198 TipperShakerRequest_ISig_5 500;
BA_REL_ "GenSigFirstTimeoutTime" BU_SG_REL_ CIOM SG_ 2432679743 WRC5thWheelRequest 3000;
BA_REL_ "GenSigTimeoutTime" BU_SG_REL_ CIOM SG_ 2432679743 WRC5thWheelRequest 120;
BA_REL_ "GenSigFirstTimeoutTime" BU_SG_REL_ CIOM SG_ 2432679743 WRC_Docking_stat_ISig_5 3000;
BA_REL_ "GenSigTimeoutTime" BU_SG_REL_ CIOM SG_ 2432679743 WRC_Docking_stat_ISig_5 120;
BA_REL_ "GenSigFirstTimeoutTime" BU_SG_REL_ CIOM SG_ 2432679743 WRCLevelUserMemoryAction 3000;
BA_REL_ "GenSigTimeoutTime" BU_SG_REL_ CIOM SG_ 2432679743 WRCLevelUserMemoryAction 120;
BA_REL_ "GenSigFirstTimeoutTime" BU_SG_REL_ CIOM SG_ 2432679743 WRCLevelUserMemory 3000;
BA_REL_ "GenSigTimeoutTime" BU_SG_REL_ CIOM SG_ 2432679743 WRCLevelUserMemory 120;
BA_REL_ "GenSigFirstTimeoutTime" BU_SG_REL_ CIOM SG_ 2432679743 WrcEngSpdCtrlResumeButtonStat 3000;
BA_REL_ "GenSigTimeoutTime" BU_SG_REL_ CIOM SG_ 2432679743 WrcEngSpdCtrlResumeButtonStat 120;
BA_REL_ "GenSigFirstTimeoutTime" BU_SG_REL_ CIOM SG_ 2432679743 WRCBeaconRequest 3000;
BA_REL_ "GenSigTimeoutTime" BU_SG_REL_ CIOM SG_ 2432679743 WRCBeaconRequest 120;
BA_REL_ "GenSigFirstTimeoutTime" BU_SG_REL_ CIOM SG_ 2432679743 WrcEngSpdCtrlDecreaseButtStat 3000;
BA_REL_ "GenSigTimeoutTime" BU_SG_REL_ CIOM SG_ 2432679743 WrcEngSpdCtrlDecreaseButtStat 120;
BA_REL_ "GenSigFirstTimeoutTime" BU_SG_REL_ CIOM SG_ 2432679743 WRCEngineStartRequest_ISig_5 3000;
BA_REL_ "GenSigTimeoutTime" BU_SG_REL_ CIOM SG_ 2432679743 WRCEngineStartRequest_ISig_5 500;
BA_REL_ "GenSigFirstTimeoutTime" BU_SG_REL_ CIOM SG_ 2432679743 WrcEngSpdCtrlEnableStatus 3000;
BA_REL_ "GenSigTimeoutTime" BU_SG_REL_ CIOM SG_ 2432679743 WrcEngSpdCtrlEnableStatus 120;
BA_REL_ "GenSigFirstTimeoutTime" BU_SG_REL_ CIOM SG_ 2432679743 WRCCabBodyWLightsRqst 3000;
BA_REL_ "GenSigTimeoutTime" BU_SG_REL_ CIOM SG_ 2432679743 WRCCabBodyWLightsRqst 120;
BA_REL_ "GenSigFirstTimeoutTime" BU_SG_REL_ CIOM SG_ 2432679743 WRCEngineStopRequest_ISig_5 3000;
BA_REL_ "GenSigTimeoutTime" BU_SG_REL_ CIOM SG_ 2432679743 WRCEngineStopRequest_ISig_5 500;
BA_REL_ "GenSigFirstTimeoutTime" BU_SG_REL_ CIOM SG_ 2432679743 WrcEngSpdCtrlIncreaseButtStat 3000;
BA_REL_ "GenSigTimeoutTime" BU_SG_REL_ CIOM SG_ 2432679743 WrcEngSpdCtrlIncreaseButtStat 120;
BA_REL_ "GenSigFirstTimeoutTime" BU_SG_REL_ CIOM SG_ 2365554559 WrcPto1ButtonStatus 3000;
BA_REL_ "GenSigTimeoutTime" BU_SG_REL_ CIOM SG_ 2365554559 WrcPto1ButtonStatus 60;
BA_REL_ "GenSigFirstTimeoutTime" BU_SG_REL_ CIOM SG_ 2365554559 ECSStandByReqWRC 3000;
BA_REL_ "GenSigTimeoutTime" BU_SG_REL_ CIOM SG_ 2365554559 ECSStandByReqWRC 60;
BA_REL_ "GenSigFirstTimeoutTime" BU_SG_REL_ CIOM SG_ 2365554559 WRCCraneRequest 3000;
BA_REL_ "GenSigTimeoutTime" BU_SG_REL_ CIOM SG_ 2365554559 WRCCraneRequest 60;
BA_REL_ "GenSigFirstTimeoutTime" BU_SG_REL_ CIOM SG_ 2365554559 WRCUnlockButtonStatus 3000;
BA_REL_ "GenSigTimeoutTime" BU_SG_REL_ CIOM SG_ 2365554559 WRCUnlockButtonStatus 60;
BA_REL_ "GenSigFirstTimeoutTime" BU_SG_REL_ CIOM SG_ 2365554559 WRCRollRequest 3000;
BA_REL_ "GenSigTimeoutTime" BU_SG_REL_ CIOM SG_ 2365554559 WRCRollRequest 60;
BA_REL_ "GenSigFirstTimeoutTime" BU_SG_REL_ CIOM SG_ 2365554559 WRCAux3Request 3000;
BA_REL_ "GenSigTimeoutTime" BU_SG_REL_ CIOM SG_ 2365554559 WRCAux3Request 60;
BA_REL_ "GenSigFirstTimeoutTime" BU_SG_REL_ CIOM SG_ 2365554559 WRCAux2Request 3000;
BA_REL_ "GenSigTimeoutTime" BU_SG_REL_ CIOM SG_ 2365554559 WRCAux2Request 60;
BA_REL_ "GenSigFirstTimeoutTime" BU_SG_REL_ CIOM SG_ 2365554559 WrcPto3ButtonStatus 3000;
BA_REL_ "GenSigTimeoutTime" BU_SG_REL_ CIOM SG_ 2365554559 WrcPto3ButtonStatus 60;
BA_REL_ "GenSigFirstTimeoutTime" BU_SG_REL_ CIOM SG_ 2365554559 WRCLevelAdjustmentAction 3000;
BA_REL_ "GenSigTimeoutTime" BU_SG_REL_ CIOM SG_ 2365554559 WRCLevelAdjustmentAction 60;
BA_REL_ "GenSigFirstTimeoutTime" BU_SG_REL_ CIOM SG_ 2365554559 WRCAux4Request 3000;
BA_REL_ "GenSigTimeoutTime" BU_SG_REL_ CIOM SG_ 2365554559 WRCAux4Request 60;
BA_REL_ "GenSigFirstTimeoutTime" BU_SG_REL_ CIOM SG_ 2365554559 WRCAux5Request 3000;
BA_REL_ "GenSigTimeoutTime" BU_SG_REL_ CIOM SG_ 2365554559 WRCAux5Request 60;
BA_REL_ "GenSigFirstTimeoutTime" BU_SG_REL_ CIOM SG_ 2365554559 WRCAux6Request 3000;
BA_REL_ "GenSigTimeoutTime" BU_SG_REL_ CIOM SG_ 2365554559 WRCAux6Request 60;
BA_REL_ "GenSigFirstTimeoutTime" BU_SG_REL_ CIOM SG_ 2365554559 WRCSideReverseWorkingRequest 3000;
BA_REL_ "GenSigTimeoutTime" BU_SG_REL_ CIOM SG_ 2365554559 WRCSideReverseWorkingRequest 60;
BA_REL_ "GenSigFirstTimeoutTime" BU_SG_REL_ CIOM SG_ 2365554559 WrcPto2ButtonStatus 3000;
BA_REL_ "GenSigTimeoutTime" BU_SG_REL_ CIOM SG_ 2365554559 WrcPto2ButtonStatus 60;
BA_REL_ "GenSigFirstTimeoutTime" BU_SG_REL_ CIOM SG_ 2365554559 WRCTailLiftRequest 3000;
BA_REL_ "GenSigTimeoutTime" BU_SG_REL_ CIOM SG_ 2365554559 WRCTailLiftRequest 60;
BA_REL_ "GenSigFirstTimeoutTime" BU_SG_REL_ CIOM SG_ 2365554559 WrcPto4ButtonStatus 3000;
BA_REL_ "GenSigTimeoutTime" BU_SG_REL_ CIOM SG_ 2365554559 WrcPto4ButtonStatus 60;
BA_REL_ "GenSigFirstTimeoutTime" BU_SG_REL_ CIOM SG_ 2365554559 WRCLevelAdjustmentStroke 3000;
BA_REL_ "GenSigTimeoutTime" BU_SG_REL_ CIOM SG_ 2365554559 WRCLevelAdjustmentStroke 60;
BA_REL_ "GenSigFirstTimeoutTime" BU_SG_REL_ CIOM SG_ 2365554559 WRCLevelAdjustmentAxles 3000;
BA_REL_ "GenSigTimeoutTime" BU_SG_REL_ CIOM SG_ 2365554559 WRCLevelAdjustmentAxles 60;
BA_REL_ "GenSigFirstTimeoutTime" BU_SG_REL_ CIOM SG_ 2365554559 WRCAirSuspensionStopRequest 3000;
BA_REL_ "GenSigTimeoutTime" BU_SG_REL_ CIOM SG_ 2365554559 WRCAirSuspensionStopRequest 60;
BA_REL_ "GenSigFirstTimeoutTime" BU_SG_REL_ CIOM SG_ 2365554559 WRCAux1Request 3000;
BA_REL_ "GenSigTimeoutTime" BU_SG_REL_ CIOM SG_ 2365554559 WRCAux1Request 60;
BA_REL_ "GenSigFirstTimeoutTime" BU_SG_REL_ CIOM SG_ 2365554559 WRCLockButtonStatus 3000;
BA_REL_ "GenSigTimeoutTime" BU_SG_REL_ CIOM SG_ 2365554559 WRCLockButtonStatus 60;
BA_REL_ "GenSigFirstTimeoutTime" BU_SG_REL_ CIOM SG_ 2566826323 SRS2_SN_Byte2 24000;
BA_REL_ "GenSigTimeoutTime" BU_SG_REL_ CIOM SG_ 2566826323 SRS2_SN_Byte2 6000;
BA_REL_ "GenSigFirstTimeoutTime" BU_SG_REL_ CIOM SG_ 2566826323 SRS2_SN_Byte1 24000;
BA_REL_ "GenSigTimeoutTime" BU_SG_REL_ CIOM SG_ 2566826323 SRS2_SN_Byte1 6000;
BA_REL_ "GenSigFirstTimeoutTime" BU_SG_REL_ CIOM SG_ 2566826323 SRS2_SN_Byte0 24000;
BA_REL_ "GenSigTimeoutTime" BU_SG_REL_ CIOM SG_ 2566826323 SRS2_SN_Byte0 6000;
BA_REL_ "GenSigFirstTimeoutTime" BU_SG_REL_ CIOM SG_ 2566826323 SRS2_SN_Byte3 24000;
BA_REL_ "GenSigTimeoutTime" BU_SG_REL_ CIOM SG_ 2566826323 SRS2_SN_Byte3 6000;
BA_REL_ "GenSigFirstTimeoutTime" BU_SG_REL_ CIOM SG_ 2566825811 SRS2_SNPN_Byte2 24000;
BA_REL_ "GenSigTimeoutTime" BU_SG_REL_ CIOM SG_ 2566825811 SRS2_SNPN_Byte2 6000;
BA_REL_ "GenSigFirstTimeoutTime" BU_SG_REL_ CIOM SG_ 2566825811 SRS2_SNPN_Byte3 24000;
BA_REL_ "GenSigTimeoutTime" BU_SG_REL_ CIOM SG_ 2566825811 SRS2_SNPN_Byte3 6000;
BA_REL_ "GenSigFirstTimeoutTime" BU_SG_REL_ CIOM SG_ 2566825811 SRS2_SNPN_Byte1 24000;
BA_REL_ "GenSigTimeoutTime" BU_SG_REL_ CIOM SG_ 2566825811 SRS2_SNPN_Byte1 6000;
BA_REL_ "GenSigFirstTimeoutTime" BU_SG_REL_ CIOM SG_ 2566825811 SRS2_SNPN_Byte0 24000;
BA_REL_ "GenSigTimeoutTime" BU_SG_REL_ CIOM SG_ 2566825811 SRS2_SNPN_Byte0 6000;
BA_REL_ "GenSigFirstTimeoutTime" BU_SG_REL_ CIOM SG_ 2566825811 SRS2_SNPN_Byte4 24000;
BA_REL_ "GenSigTimeoutTime" BU_SG_REL_ CIOM SG_ 2566825811 SRS2_SNPN_Byte4 6000;
BA_REL_ "GenSigFirstTimeoutTime" BU_SG_REL_ CIOM SG_ 2516232019 DiagInfoSRS2 24000;
BA_REL_ "GenSigTimeoutTime" BU_SG_REL_ CIOM SG_ 2516232019 DiagInfoSRS2 6000;
BA_REL_ "GenSigFirstTimeoutTime" BU_SG_REL_ CIOM SG_ 2499788607 ECUVIN_rqst 3000;
BA_REL_ "GenSigTimeoutTime" BU_SG_REL_ CIOM SG_ 2499788607 ECUVIN_rqst 300;
BA_REL_ "GenSigFirstTimeoutTime" BU_SG_REL_ CIOM SG_ 2432689491 SRSAirbagStatus_ISig_5 3000;
BA_REL_ "GenSigTimeoutTime" BU_SG_REL_ CIOM SG_ 2432689491 SRSAirbagStatus_ISig_5 120;
BA_REL_ "GenSigFirstTimeoutTime" BU_SG_REL_ CIOM SG_ 2432689491 TrafficAccidentHazardLightRqst_I 3000;
BA_REL_ "GenSigTimeoutTime" BU_SG_REL_ CIOM SG_ 2432689491 TrafficAccidentHazardLightRqst_I 120;
BA_REL_ "GenSigFirstTimeoutTime" BU_SG_REL_ CIOM SG_ 2432689491 FrontalCollisionAccidentStatus_I 3000;
BA_REL_ "GenSigTimeoutTime" BU_SG_REL_ CIOM SG_ 2432689491 FrontalCollisionAccidentStatus_I 120;
BA_REL_ "GenSigFirstTimeoutTime" BU_SG_REL_ CIOM SG_ 2432689491 EmergencyDoorsUnlock_rqst 3000;
BA_REL_ "GenSigTimeoutTime" BU_SG_REL_ CIOM SG_ 2432689491 EmergencyDoorsUnlock_rqst 120;
BA_REL_ "GenSigFirstTimeoutTime" BU_SG_REL_ CIOM SG_ 2432689491 RollOverAccidentStatus_ISig_5 3000;
BA_REL_ "GenSigTimeoutTime" BU_SG_REL_ CIOM SG_ 2432689491 RollOverAccidentStatus_ISig_5 120;
BA_REL_ "GenSigFirstTimeoutTime" BU_SG_REL_ CIOM SG_ 2489730210 BunkH1AudioSrcSem_rqst_ISig_5 3000;
BA_REL_ "GenSigTimeoutTime" BU_SG_REL_ CIOM SG_ 2489730210 BunkH1AudioSrcSem_rqst_ISig_5 300;
BA_REL_ "GenSigFirstTimeoutTime" BU_SG_REL_ CIOM SG_ 2432693154 BunkH1RoofhatchOpenBtn_Stat 3000;
BA_REL_ "GenSigTimeoutTime" BU_SG_REL_ CIOM SG_ 2432693154 BunkH1RoofhatchOpenBtn_Stat 60;
BA_REL_ "GenSigFirstTimeoutTime" BU_SG_REL_ CIOM SG_ 2432693154 BunkH1IntLghtActvnBtn_stat 3000;
BA_REL_ "GenSigTimeoutTime" BU_SG_REL_ CIOM SG_ 2432693154 BunkH1IntLghtActvnBtn_stat 60;
BA_REL_ "GenSigFirstTimeoutTime" BU_SG_REL_ CCM SG_ 2432693154 BunkH1TempDec_ButtonStatus 3000;
BA_REL_ "GenSigTimeoutTime" BU_SG_REL_ CCM SG_ 2432693154 BunkH1TempDec_ButtonStatus 60;
BA_REL_ "GenSigFirstTimeoutTime" BU_SG_REL_ CIOM SG_ 2432693154 BunkH1IntLghtDirAccsUpBtn_stat 3000;
BA_REL_ "GenSigTimeoutTime" BU_SG_REL_ CIOM SG_ 2432693154 BunkH1IntLghtDirAccsUpBtn_stat 60;
BA_REL_ "GenSigFirstTimeoutTime" BU_SG_REL_ CIOM SG_ 2432693154 BunkH1AudioSource_rqst2_ISig_5 3000;
BA_REL_ "GenSigTimeoutTime" BU_SG_REL_ CIOM SG_ 2432693154 BunkH1AudioSource_rqst2_ISig_5 60;
BA_REL_ "GenSigFirstTimeoutTime" BU_SG_REL_ CIOM SG_ 2432693154 BunkH1AudioOnOff_ButtonStatus_IS 3000;
BA_REL_ "GenSigTimeoutTime" BU_SG_REL_ CIOM SG_ 2432693154 BunkH1AudioOnOff_ButtonStatus_IS 60;
BA_REL_ "GenSigFirstTimeoutTime" BU_SG_REL_ CIOM SG_ 2432693154 BunkH1RoofhatchCloseBtn_Stat 3000;
BA_REL_ "GenSigTimeoutTime" BU_SG_REL_ CIOM SG_ 2432693154 BunkH1RoofhatchCloseBtn_Stat 60;
BA_REL_ "GenSigFirstTimeoutTime" BU_SG_REL_ CIOM SG_ 2432693154 BunkH1VolumeUp_ButtonStatus_ISig 3000;
BA_REL_ "GenSigTimeoutTime" BU_SG_REL_ CIOM SG_ 2432693154 BunkH1VolumeUp_ButtonStatus_ISig 60;
BA_REL_ "GenSigFirstTimeoutTime" BU_SG_REL_ CIOM SG_ 2432693154 BunkH1PowerWinCloseDSBtn_stat_IS 3000;
BA_REL_ "GenSigTimeoutTime" BU_SG_REL_ CIOM SG_ 2432693154 BunkH1PowerWinCloseDSBtn_stat_IS 500;
BA_REL_ "GenSigFirstTimeoutTime" BU_SG_REL_ CIOM SG_ 2432693154 BunkH1Prev_ButtonStatus_ISig_5 3000;
BA_REL_ "GenSigTimeoutTime" BU_SG_REL_ CIOM SG_ 2432693154 BunkH1Prev_ButtonStatus_ISig_5 60;
BA_REL_ "GenSigFirstTimeoutTime" BU_SG_REL_ CIOM SG_ 2432693154 BunkH1UnlockButtonStatus 3000;
BA_REL_ "GenSigTimeoutTime" BU_SG_REL_ CIOM SG_ 2432693154 BunkH1UnlockButtonStatus 60;
BA_REL_ "GenSigFirstTimeoutTime" BU_SG_REL_ CIOM SG_ 2432693154 BunkH1VolumeDown_ButtonStatus_IS 3000;
BA_REL_ "GenSigTimeoutTime" BU_SG_REL_ CIOM SG_ 2432693154 BunkH1VolumeDown_ButtonStatus_IS 60;
BA_REL_ "GenSigFirstTimeoutTime" BU_SG_REL_ CCM SG_ 2432693154 BunkH1ParkHeaterTimer2_cmd 3000;
BA_REL_ "GenSigTimeoutTime" BU_SG_REL_ CCM SG_ 2432693154 BunkH1ParkHeaterTimer2_cmd 60;
BA_REL_ "GenSigFirstTimeoutTime" BU_SG_REL_ CIOM SG_ 2432693154 BunkH1PowerWinOpenDSBtn_stat_ISi 3000;
BA_REL_ "GenSigTimeoutTime" BU_SG_REL_ CIOM SG_ 2432693154 BunkH1PowerWinOpenDSBtn_stat_ISi 500;
BA_REL_ "GenSigFirstTimeoutTime" BU_SG_REL_ CCM SG_ 2432693154 BunkH1ParkHeater_ButtonStatus 3000;
BA_REL_ "GenSigTimeoutTime" BU_SG_REL_ CCM SG_ 2432693154 BunkH1ParkHeater_ButtonStatus 60;
BA_REL_ "GenSigFirstTimeoutTime" BU_SG_REL_ CCM SG_ 2432693154 BunkH1ParkHeaterTimer3_cmd 3000;
BA_REL_ "GenSigTimeoutTime" BU_SG_REL_ CCM SG_ 2432693154 BunkH1ParkHeaterTimer3_cmd 60;
BA_REL_ "GenSigFirstTimeoutTime" BU_SG_REL_ CIOM SG_ 2432693154 BunkH1AudioSource_rqst_ISig_5 3000;
BA_REL_ "GenSigTimeoutTime" BU_SG_REL_ CIOM SG_ 2432693154 BunkH1AudioSource_rqst_ISig_5 60;
BA_REL_ "GenSigFirstTimeoutTime" BU_SG_REL_ CIOM SG_ 2432693154 BunkH1Mute_ButtonStatus_ISig_5 3000;
BA_REL_ "GenSigTimeoutTime" BU_SG_REL_ CIOM SG_ 2432693154 BunkH1Mute_ButtonStatus_ISig_5 60;
BA_REL_ "GenSigFirstTimeoutTime" BU_SG_REL_ CIOM SG_ 2432693154 BunkH1IntLghtDirAccsDnBtn_stat 3000;
BA_REL_ "GenSigTimeoutTime" BU_SG_REL_ CIOM SG_ 2432693154 BunkH1IntLghtDirAccsDnBtn_stat 60;
BA_REL_ "GenSigFirstTimeoutTime" BU_SG_REL_ CIOM SG_ 2432693154 BunkH1LockButtonStatus 3000;
BA_REL_ "GenSigTimeoutTime" BU_SG_REL_ CIOM SG_ 2432693154 BunkH1LockButtonStatus 60;
BA_REL_ "GenSigFirstTimeoutTime" BU_SG_REL_ CCM SG_ 2432693154 BunkH1ParkHeaterTimer1_cmd 3000;
BA_REL_ "GenSigTimeoutTime" BU_SG_REL_ CCM SG_ 2432693154 BunkH1ParkHeaterTimer1_cmd 60;
BA_REL_ "GenSigFirstTimeoutTime" BU_SG_REL_ CIOM SG_ 2432693154 BnkH1IntLghtMMenu_stat_IL_Mode 3000;
BA_REL_ "GenSigTimeoutTime" BU_SG_REL_ CIOM SG_ 2432693154 BnkH1IntLghtMMenu_stat_IL_Mode 60;
BA_REL_ "GenSigFirstTimeoutTime" BU_SG_REL_ CIOM SG_ 2432693154 BunkH1Next_ButtonStatus_ISig_5 3000;
BA_REL_ "GenSigTimeoutTime" BU_SG_REL_ CIOM SG_ 2432693154 BunkH1Next_ButtonStatus_ISig_5 60;
BA_REL_ "GenSigFirstTimeoutTime" BU_SG_REL_ CIOM SG_ 2432693154 BnkH1IntLghtMMenu_stat_EventFlag 3000;
BA_REL_ "GenSigTimeoutTime" BU_SG_REL_ CIOM SG_ 2432693154 BnkH1IntLghtMMenu_stat_EventFlag 60;
BA_REL_ "GenSigFirstTimeoutTime" BU_SG_REL_ CIOM SG_ 2432693154 BunkH1PowerWinOpenPSBtn_stat_ISi 3000;
BA_REL_ "GenSigTimeoutTime" BU_SG_REL_ CIOM SG_ 2432693154 BunkH1PowerWinOpenPSBtn_stat_ISi 500;
BA_REL_ "GenSigFirstTimeoutTime" BU_SG_REL_ CIOM SG_ 2432693154 BunkH1PowerWinClosePSBtn_stat_IS 3000;
BA_REL_ "GenSigTimeoutTime" BU_SG_REL_ CIOM SG_ 2432693154 BunkH1PowerWinClosePSBtn_stat_IS 500;
BA_REL_ "GenSigFirstTimeoutTime" BU_SG_REL_ CCM SG_ 2432693154 BunkH1TempInc_ButtonStatus 3000;
BA_REL_ "GenSigTimeoutTime" BU_SG_REL_ CCM SG_ 2432693154 BunkH1TempInc_ButtonStatus 60;
BA_REL_ "GenSigFirstTimeoutTime" BU_SG_REL_ SRS SG_ 2566357312 GPSData_VehSpeed_ISig_5 12000;
BA_REL_ "GenSigTimeoutTime" BU_SG_REL_ SRS SG_ 2566357312 GPSData_VehSpeed_ISig_5 3000;
BA_REL_ "GenSigFirstTimeoutTime" BU_SG_REL_ SRS SG_ 2566357312 GPSData_HDOP_ISig_5 12000;
BA_REL_ "GenSigTimeoutTime" BU_SG_REL_ SRS SG_ 2566357312 GPSData_HDOP_ISig_5 3000;
BA_REL_ "GenSigFirstTimeoutTime" BU_SG_REL_ SRS SG_ 2566357312 GPSData_Direction_ISig_5 12000;
BA_REL_ "GenSigTimeoutTime" BU_SG_REL_ SRS SG_ 2566357312 GPSData_Direction_ISig_5 3000;
BA_REL_ "GenSigFirstTimeoutTime" BU_SG_REL_ SRS SG_ 2566357312 GPSData_Longitude_ISig_5 12000;
BA_REL_ "GenSigTimeoutTime" BU_SG_REL_ SRS SG_ 2566357312 GPSData_Longitude_ISig_5 3000;
BA_REL_ "GenSigFirstTimeoutTime" BU_SG_REL_ SRS SG_ 2566357312 GPSData_AntennaStat_ISig_5 12000;
BA_REL_ "GenSigTimeoutTime" BU_SG_REL_ SRS SG_ 2566357312 GPSData_AntennaStat_ISig_5 3000;
BA_REL_ "GenSigFirstTimeoutTime" BU_SG_REL_ SRS SG_ 2566357312 GPSData_Latitude_ISig_5 12000;
BA_REL_ "GenSigTimeoutTime" BU_SG_REL_ SRS SG_ 2566357312 GPSData_Latitude_ISig_5 3000;
BA_REL_ "GenSigFirstTimeoutTime" BU_SG_REL_ SRS SG_ 2566357312 GPSData_Altitude_ISig_5 12000;
BA_REL_ "GenSigTimeoutTime" BU_SG_REL_ SRS SG_ 2566357312 GPSData_Altitude_ISig_5 3000;
BA_REL_ "GenSigFirstTimeoutTime" BU_SG_REL_ SRS SG_ 2566357312 GPSData_Time_ISig_5 12000;
BA_REL_ "GenSigTimeoutTime" BU_SG_REL_ SRS SG_ 2566357312 GPSData_Time_ISig_5 3000;
BA_REL_ "GenSigFirstTimeoutTime" BU_SG_REL_ SRS SG_ 2432680000 BrakePedalPosition_ISig_5 3000;
BA_REL_ "GenSigTimeoutTime" BU_SG_REL_ SRS SG_ 2432680000 BrakePedalPosition_ISig_5 60;
BA_REL_ "GenSigFirstTimeoutTime" BU_SG_REL_ SRS SG_ 2432680000 SteeringWheelAngle_ISig_5 3000;
BA_REL_ "GenSigTimeoutTime" BU_SG_REL_ SRS SG_ 2432680000 SteeringWheelAngle_ISig_5 60;
BA_REL_ "GenSigFirstTimeoutTime" BU_SG_REL_ SRS SG_ 2432647232 CM_Status_ISig_5 3000;
BA_REL_ "GenSigTimeoutTime" BU_SG_REL_ SRS SG_ 2432647232 CM_Status_ISig_5 120;
BA_REL_ "GenSigFirstTimeoutTime" BU_SG_REL_ SRS SG_ 2516193600 ActualDrvlnRetdrPercentTorque_IS 3000;
BA_REL_ "GenSigTimeoutTime" BU_SG_REL_ SRS SG_ 2516193600 ActualDrvlnRetdrPercentTorque_IS 600;
BA_REL_ "GenSigFirstTimeoutTime" BU_SG_REL_ SRS SG_ 2516193600 ROPBrakeControlActive_ISig_5 3000;
BA_REL_ "GenSigTimeoutTime" BU_SG_REL_ SRS SG_ 2516193600 ROPBrakeControlActive_ISig_5 600;
BA_REL_ "GenSigFirstTimeoutTime" BU_SG_REL_ SRS SG_ 2516193600 FoundationBrakeUse_ISig_5 3000;
BA_REL_ "GenSigTimeoutTime" BU_SG_REL_ SRS SG_ 2516193600 FoundationBrakeUse_ISig_5 600;
BA_REL_ "GenSigFirstTimeoutTime" BU_SG_REL_ SRS SG_ 2516193600 YCBrakeControlActive_ISig_5 3000;
BA_REL_ "GenSigTimeoutTime" BU_SG_REL_ SRS SG_ 2516193600 YCBrakeControlActive_ISig_5 600;
BA_REL_ "GenSigFirstTimeoutTime" BU_SG_REL_ SRS SG_ 2516193600 ActualEngineRetarderPercentTrq_I 3000;
BA_REL_ "GenSigTimeoutTime" BU_SG_REL_ SRS SG_ 2516193600 ActualEngineRetarderPercentTrq_I 600;
BA_REL_ "GenSigFirstTimeoutTime" BU_SG_REL_ SRS SG_ 2516193600 AntiLockBrakingActive_ISig_5 3000;
BA_REL_ "GenSigTimeoutTime" BU_SG_REL_ SRS SG_ 2516193600 AntiLockBrakingActive_ISig_5 600;
BA_REL_ "GenSigFirstTimeoutTime" BU_SG_REL_ LECM1 SG_ 2493989952 SEMMediaSourceAvail_Source07_ISi 3000;
BA_REL_ "GenSigTimeoutTime" BU_SG_REL_ LECM1 SG_ 2493989952 SEMMediaSourceAvail_Source07_ISi 300;
BA_REL_ "GenSigFirstTimeoutTime" BU_SG_REL_ LECM1 SG_ 2493989952 SEMMediaSourceAvail_Source06_ISi 3000;
BA_REL_ "GenSigTimeoutTime" BU_SG_REL_ LECM1 SG_ 2493989952 SEMMediaSourceAvail_Source06_ISi 300;
BA_REL_ "GenSigFirstTimeoutTime" BU_SG_REL_ LECM1 SG_ 2493989952 SEMMediaSourceAvail_Source08_ISi 3000;
BA_REL_ "GenSigTimeoutTime" BU_SG_REL_ LECM1 SG_ 2493989952 SEMMediaSourceAvail_Source08_ISi 300;
BA_REL_ "GenSigFirstTimeoutTime" BU_SG_REL_ LECM1 SG_ 2493989952 SEMMediaSourceAvail_Source00_ISi 3000;
BA_REL_ "GenSigTimeoutTime" BU_SG_REL_ LECM1 SG_ 2493989952 SEMMediaSourceAvail_Source00_ISi 300;
BA_REL_ "GenSigFirstTimeoutTime" BU_SG_REL_ LECM1 SG_ 2493989952 SEM_AudioMuteStat_ISig_5 3000;
BA_REL_ "GenSigTimeoutTime" BU_SG_REL_ LECM1 SG_ 2493989952 SEM_AudioMuteStat_ISig_5 300;
BA_REL_ "GenSigFirstTimeoutTime" BU_SG_REL_ LECM1 SG_ 2493989952 SEMMediaSourceAvail_Source09_ISi 3000;
BA_REL_ "GenSigTimeoutTime" BU_SG_REL_ LECM1 SG_ 2493989952 SEMMediaSourceAvail_Source09_ISi 300;
BA_REL_ "GenSigFirstTimeoutTime" BU_SG_REL_ LECM1 SG_ 2493989952 SEMMediaSourceAvail_Source13_ISi 3000;
BA_REL_ "GenSigTimeoutTime" BU_SG_REL_ LECM1 SG_ 2493989952 SEMMediaSourceAvail_Source13_ISi 300;
BA_REL_ "GenSigFirstTimeoutTime" BU_SG_REL_ LECM1 SG_ 2493989952 SEMMediaSourceAvail_Source04_ISi 3000;
BA_REL_ "GenSigTimeoutTime" BU_SG_REL_ LECM1 SG_ 2493989952 SEMMediaSourceAvail_Source04_ISi 300;
BA_REL_ "GenSigFirstTimeoutTime" BU_SG_REL_ LECM1 SG_ 2493989952 SEMMediaSourceAvail_Source05_ISi 3000;
BA_REL_ "GenSigTimeoutTime" BU_SG_REL_ LECM1 SG_ 2493989952 SEMMediaSourceAvail_Source05_ISi 300;
BA_REL_ "GenSigFirstTimeoutTime" BU_SG_REL_ LECM1 SG_ 2493989952 SEMMediaSourceAvail_Source02_ISi 3000;
BA_REL_ "GenSigTimeoutTime" BU_SG_REL_ LECM1 SG_ 2493989952 SEMMediaSourceAvail_Source02_ISi 300;
BA_REL_ "GenSigFirstTimeoutTime" BU_SG_REL_ LECM1 SG_ 2493989952 SEMMediaSourceAvail_SInfo_ISig_5 3000;
BA_REL_ "GenSigTimeoutTime" BU_SG_REL_ LECM1 SG_ 2493989952 SEMMediaSourceAvail_SInfo_ISig_5 300;
BA_REL_ "GenSigFirstTimeoutTime" BU_SG_REL_ LECM1 SG_ 2493989952 AudioSourceStat_ISig_5 3000;
BA_REL_ "GenSigTimeoutTime" BU_SG_REL_ LECM1 SG_ 2493989952 AudioSourceStat_ISig_5 300;
BA_REL_ "GenSigFirstTimeoutTime" BU_SG_REL_ LECM1 SG_ 2493989952 SEMMediaSourceAvail_Source11_ISi 3000;
BA_REL_ "GenSigTimeoutTime" BU_SG_REL_ LECM1 SG_ 2493989952 SEMMediaSourceAvail_Source11_ISi 300;
BA_REL_ "GenSigFirstTimeoutTime" BU_SG_REL_ LECM1 SG_ 2493989952 SEMMediaSourceAvail_Source10_ISi 3000;
BA_REL_ "GenSigTimeoutTime" BU_SG_REL_ LECM1 SG_ 2493989952 SEMMediaSourceAvail_Source10_ISi 300;
BA_REL_ "GenSigFirstTimeoutTime" BU_SG_REL_ LECM1 SG_ 2493989952 SEM_AudioVolValIndCmd_ISig_5 3000;
BA_REL_ "GenSigTimeoutTime" BU_SG_REL_ LECM1 SG_ 2493989952 SEM_AudioVolValIndCmd_ISig_5 300;
BA_REL_ "GenSigFirstTimeoutTime" BU_SG_REL_ LECM1 SG_ 2493989952 SEMMediaSourceAvail_Source01_ISi 3000;
BA_REL_ "GenSigTimeoutTime" BU_SG_REL_ LECM1 SG_ 2493989952 SEMMediaSourceAvail_Source01_ISi 300;
BA_REL_ "GenSigFirstTimeoutTime" BU_SG_REL_ LECM1 SG_ 2493989952 SEMMediaSourceAvail_Source03_ISi 3000;
BA_REL_ "GenSigTimeoutTime" BU_SG_REL_ LECM1 SG_ 2493989952 SEMMediaSourceAvail_Source03_ISi 300;
BA_REL_ "GenSigFirstTimeoutTime" BU_SG_REL_ LECM1 SG_ 2493989952 SEM_PresetIndicationCmd_ISig_5 3000;
BA_REL_ "GenSigTimeoutTime" BU_SG_REL_ LECM1 SG_ 2493989952 SEM_PresetIndicationCmd_ISig_5 300;
BA_REL_ "GenSigFirstTimeoutTime" BU_SG_REL_ LECM1 SG_ 2493989952 SEMMediaSourceAvail_Source12_ISi 3000;
BA_REL_ "GenSigTimeoutTime" BU_SG_REL_ LECM1 SG_ 2493989952 SEMMediaSourceAvail_Source12_ISi 300;
BA_REL_ "GenSigFirstTimeoutTime" BU_SG_REL_ WRCS SG_ 2499754560 TipperEmergencyStopStatus_ISig_5 3000;
BA_REL_ "GenSigTimeoutTime" BU_SG_REL_ WRCS SG_ 2499754560 TipperEmergencyStopStatus_ISig_5 300;
BA_REL_ "GenSigFirstTimeoutTime" BU_SG_REL_ WRCS SG_ 2499754560 TipperPrimaryBodyStatus_ISig_5 3000;
BA_REL_ "GenSigTimeoutTime" BU_SG_REL_ WRCS SG_ 2499754560 TipperPrimaryBodyStatus_ISig_5 300;
BA_REL_ "GenSigFirstTimeoutTime" BU_SG_REL_ WRCS SG_ 2499754560 TipperConditionsStatus_ISig_5 3000;
BA_REL_ "GenSigTimeoutTime" BU_SG_REL_ WRCS SG_ 2499754560 TipperConditionsStatus_ISig_5 300;
BA_REL_ "GenSigFirstTimeoutTime" BU_SG_REL_ WRCS SG_ 2499754560 TipperSecondaryBodyStatus_ISig_5 3000;
BA_REL_ "GenSigTimeoutTime" BU_SG_REL_ WRCS SG_ 2499754560 TipperSecondaryBodyStatus_ISig_5 300;
BA_REL_ "GenSigFirstTimeoutTime" BU_SG_REL_ WRCS SG_ 2499754560 BatterySOCAlert_rqst_ISig_5 3000;
BA_REL_ "GenSigTimeoutTime" BU_SG_REL_ WRCS SG_ 2499754560 BatterySOCAlert_rqst_ISig_5 300;
BA_REL_ "GenSigFirstTimeoutTime" BU_SG_REL_ SRS SG_ 2499754560 CCStates_ISig_5 3000;
BA_REL_ "GenSigTimeoutTime" BU_SG_REL_ SRS SG_ 2499754560 CCStates_ISig_5 200;
BA_REL_ "GenSigFirstTimeoutTime" BU_SG_REL_ SRS SG_ 2499754560 LongMotionDirection_ISig_5 3000;
BA_REL_ "GenSigTimeoutTime" BU_SG_REL_ SRS SG_ 2499754560 LongMotionDirection_ISig_5 300;
BA_REL_ "GenSigFirstTimeoutTime" BU_SG_REL_ WRCS SG_ 2499754560 TipperUpDownStatus_ISig_5 3000;
BA_REL_ "GenSigTimeoutTime" BU_SG_REL_ WRCS SG_ 2499754560 TipperUpDownStatus_ISig_5 300;
BA_REL_ "GenSigFirstTimeoutTime" BU_SG_REL_ WRCS SG_ 2499754560 TipperTailGateStatus_ISig_5 3000;
BA_REL_ "GenSigTimeoutTime" BU_SG_REL_ WRCS SG_ 2499754560 TipperTailGateStatus_ISig_5 300;
BA_REL_ "GenSigFirstTimeoutTime" BU_SG_REL_ WRCS SG_ 2499754560 KneelingInformation_ISig_5 3000;
BA_REL_ "GenSigTimeoutTime" BU_SG_REL_ WRCS SG_ 2499754560 KneelingInformation_ISig_5 300;
BA_REL_ "GenSigFirstTimeoutTime" BU_SG_REL_ WRCS SG_ 2499754560 TailLiftRemoteNotAllowed_ISig_5 3000;
BA_REL_ "GenSigTimeoutTime" BU_SG_REL_ WRCS SG_ 2499754560 TailLiftRemoteNotAllowed_ISig_5 300;
BA_REL_ "GenSigFirstTimeoutTime" BU_SG_REL_ WRCS SG_ 2499754560 TipperTarpaulinStatus_ISig_5 3000;
BA_REL_ "GenSigTimeoutTime" BU_SG_REL_ WRCS SG_ 2499754560 TipperTarpaulinStatus_ISig_5 300;
BA_REL_ "GenSigFirstTimeoutTime" BU_SG_REL_ WRCS SG_ 2499754560 TailLiftConditionsStatus_ISig_5 3000;
BA_REL_ "GenSigTimeoutTime" BU_SG_REL_ WRCS SG_ 2499754560 TailLiftConditionsStatus_ISig_5 300;
BA_REL_ "GenSigFirstTimeoutTime" BU_SG_REL_ WRCS SG_ 2499754560 InhibitWRCECSMenuCmd 3000;
BA_REL_ "GenSigTimeoutTime" BU_SG_REL_ WRCS SG_ 2499754560 InhibitWRCECSMenuCmd 300;
BA_REL_ "GenSigFirstTimeoutTime" BU_SG_REL_ CCM SG_ 2499754560 ExtraHeating_rqst_ISig_5 3000;
BA_REL_ "GenSigTimeoutTime" BU_SG_REL_ CCM SG_ 2499754560 ExtraHeating_rqst_ISig_5 300;
BA_REL_ "GenSigFirstTimeoutTime" BU_SG_REL_ CCM SG_ 2499754560 ShortStopHeater_status_ISig_5 3000;
BA_REL_ "GenSigTimeoutTime" BU_SG_REL_ CCM SG_ 2499754560 ShortStopHeater_status_ISig_5 300;
BA_REL_ "GenSigFirstTimeoutTime" BU_SG_REL_ SRS SG_ 2499754560 LongMotionDirectionQual_ISig_5 3000;
BA_REL_ "GenSigTimeoutTime" BU_SG_REL_ SRS SG_ 2499754560 LongMotionDirectionQual_ISig_5 300;
BA_REL_ "GenSigFirstTimeoutTime" BU_SG_REL_ WRCS SG_ 2499754560 TipperShakerStatus_ISig_5 3000;
BA_REL_ "GenSigTimeoutTime" BU_SG_REL_ WRCS SG_ 2499754560 TipperShakerStatus_ISig_5 300;
BA_REL_ "GenSigFirstTimeoutTime" BU_SG_REL_ WRCS SG_ 2499754560 TailLiftMotionStatus_ISig_5 3000;
BA_REL_ "GenSigTimeoutTime" BU_SG_REL_ WRCS SG_ 2499754560 TailLiftMotionStatus_ISig_5 300;
VAL_ 2499772198 TipperTarpaulinRequest_ISig_5 7 "CoverUncoverRqst_NotAvailable" 6 "CoverUncoverRqst_Error" 5 "CoverUncoverRqst_Spare3" 4 "CoverUncoverRqst_Spare2" 3 "CoverUncoverRqst_Spare1" 2 "CoverUncoverRqst_Uncover" 1 "CoverUncoverRqst_Cover" 0 "CoverUncoverRqst_NoRequest" ;
VAL_ 2499772198 TipperUpDownRequest_ISig_5 7 "UpDown_NotAvailable" 6 "UpDown_Error" 5 "UpDown_Spare2" 4 "UpDown_Spare1" 3 "UpDown_RequestDownAuto" 2 "UpDown_RequestDown" 1 "UpDown_RequestUp" 0 "UpDown_NoRequest" ;
VAL_ 2499772198 TailLiftMotionRequest_ISig_5 7 "RqstTiltUpDown_NotAvailable" 6 "RqstTiltUpDown_Error" 5 "RqstTiltUpDown_Spare" 4 "RqstTiltUpDown_TiltDown" 3 "RqstTiltUpDown_TiltUp" 2 "RqstTiltUpDown_RequestDown" 1 "RqstTiltUpDown_RequestUp" 0 "RqstTiltUpDown_NoRequest" ;
VAL_ 2499772198 TipperEmergencyStop_ISig_5 3 "StopRqst_NotAvailable" 2 "StopRqst_Error" 1 "StopRqst_Stop" 0 "StopRqst_NoRequest" ;
VAL_ 2499772198 ExtraBbWrcWatchdog_ISig_5 3 "LowHigh_NotAvailable" 2 "LowHigh_Error" 1 "LowHigh_High" 0 "LowHigh_Low" ;
VAL_ 2499772198 TipperTailGateRequest_ISig_5 7 "OpenCloseRqst_NotAvailable" 6 "OpenCloseRqst_Error" 5 "OpenCloseRqst_Spare3" 4 "OpenCloseRqst_Spare2" 3 "OpenCloseRqst_Spare1" 2 "OpenCloseRqst_Close" 1 "OpenCloseRqst_Open" 0 "OpenCloseRqst_NoRequest" ;
VAL_ 2499772198 TipperTippingBodySelection_ISig_ 3 "PrimarySecondary_NotAvailable" 2 "PrimarySecondary_Error" 1 "PrimarySecondary_Secondary" 0 "PrimarySecondary_Primary" ;
VAL_ 2499772198 TipperShakerRequest_ISig_5 3 "ShakeRqst_NotAvailable" 2 "ShakeRqst_Error" 1 "ShakeRqst_Shake" 0 "ShakeRqst_NoRequest" ;
VAL_ 2432679743 WRC5thWheelRequest 3 "PushButtonStatus_NotAvailable" 2 "PushButtonStatus_Error" 1 "PushButtonStatus_Pushed" 0 "PushButtonStatus_Neutral" ;
VAL_ 2432679743 WRC_Docking_stat_ISig_5 3 "Docking_stat_NotAvailable" 2 "Docking_stat_Error" 1 "Docking_stat_Docked" 0 "Docking_stat_Undocked" ;
VAL_ 2432679743 WRCLevelUserMemoryAction 7 "LevelUserMemoryAction_NotAvailable" 6 "LevelUserMemoryAction_Error" 5 "LevelUserMemoryAction_Reserved_01" 4 "LevelUserMemoryAction_Reserved" 3 "LevelUserMemoryAction_Default" 2 "LevelUserMemoryAction_Store" 1 "LevelUserMemoryAction_Recall" 0 "LevelUserMemoryAction_Inactive" ;
VAL_ 2432679743 WRCLevelUserMemory 15 "LevelUserMemory_NotAvailable" 14 "LevelUserMemory_Error" 13 "LevelUserMemory_Spare05" 12 "LevelUserMemory_Spare04" 11 "LevelUserMemory_Spare03" 10 "LevelUserMemory_Spare02" 9 "LevelUserMemory_Spare01" 8 "LevelUserMemory_Spare" 7 "LevelUserMemory_M7" 6 "LevelUserMemory_M6" 5 "LevelUserMemory_M5" 4 "LevelUserMemory_M4" 3 "LevelUserMemory_M3" 2 "LevelUserMemory_M2" 1 "LevelUserMemory_M1" 0 "LevelUserMemory_NotUsed" ;
VAL_ 2432679743 WrcEngSpdCtrlResumeButtonStat 3 "ButtonStatus_NotAvailable" 2 "ButtonStatus_Error" 1 "ButtonStatus_Pressed" 0 "ButtonStatus_Idle" ;
VAL_ 2432679743 WRCBeaconRequest 3 "PushButtonStatus_NotAvailable" 2 "PushButtonStatus_Error" 1 "PushButtonStatus_Pushed" 0 "PushButtonStatus_Neutral" ;
VAL_ 2432679743 WrcEngSpdCtrlDecreaseButtStat 3 "ButtonStatus_NotAvailable" 2 "ButtonStatus_Error" 1 "ButtonStatus_Pressed" 0 "ButtonStatus_Idle" ;
VAL_ 2432679743 WRCEngineStartRequest_ISig_5 3 "PushButtonStatus_NotAvailable" 2 "PushButtonStatus_Error" 1 "PushButtonStatus_Pushed" 0 "PushButtonStatus_Neutral" ;
VAL_ 2432679743 WrcEngSpdCtrlEnableStatus 3 "DisableEnable_NotAvailable" 2 "DisableEnable_Error" 1 "DisableEnable_Enable" 0 "DisableEnable_Disable" ;
VAL_ 2432679743 WRCCabBodyWLightsRqst 3 "PushButtonStatus_NotAvailable" 2 "PushButtonStatus_Error" 1 "PushButtonStatus_Pushed" 0 "PushButtonStatus_Neutral" ;
VAL_ 2432679743 WRCEngineStopRequest_ISig_5 3 "PushButtonStatus_NotAvailable" 2 "PushButtonStatus_Error" 1 "PushButtonStatus_Pushed" 0 "PushButtonStatus_Neutral" ;
VAL_ 2432679743 WrcEngSpdCtrlIncreaseButtStat 3 "ButtonStatus_NotAvailable" 2 "ButtonStatus_Error" 1 "ButtonStatus_Pressed" 0 "ButtonStatus_Idle" ;
VAL_ 2365554559 WrcPto1ButtonStatus 3 "ButtonStatus_NotAvailable" 2 "ButtonStatus_Error" 1 "ButtonStatus_Pressed" 0 "ButtonStatus_Idle" ;
VAL_ 2365554559 ECSStandByReqWRC 7 "ECSStandByReq_NotAvailable" 6 "ECSStandByReq_Error" 5 "ECSStandByReq_Reserved_02" 4 "ECSStandByReq_Reserved_01" 3 "ECSStandByReq_Reserved" 2 "ECSStandByReq_StopStandby" 1 "ECSStandByReq_StandbyRequested" 0 "ECSStandByReq_Idle" ;
VAL_ 2365554559 WRCCraneRequest 3 "PushButtonStatus_NotAvailable" 2 "PushButtonStatus_Error" 1 "PushButtonStatus_Pushed" 0 "PushButtonStatus_Neutral" ;
VAL_ 2365554559 WRCUnlockButtonStatus 3 "PushButtonStatus_NotAvailable" 2 "PushButtonStatus_Error" 1 "PushButtonStatus_Pushed" 0 "PushButtonStatus_Neutral" ;
VAL_ 2365554559 WRCRollRequest 7 "RollRequest_NotAvailable" 6 "RollRequest_Error" 5 "RollRequest_Reserved" 4 "RollRequest_CounterClockwiseShort" 3 "RollRequest_ClockwiseShort" 2 "RollRequest_CounterClockwise" 1 "RollRequest_Clockwise" 0 "RollRequest_Idle" ;
VAL_ 2365554559 WRCAux3Request 3 "OffOn_NotAvailable" 2 "OffOn_Error" 1 "OffOn_On" 0 "OffOn_Off" ;
VAL_ 2365554559 WRCAux2Request 3 "OffOn_NotAvailable" 2 "OffOn_Error" 1 "OffOn_On" 0 "OffOn_Off" ;
VAL_ 2365554559 WrcPto3ButtonStatus 3 "ButtonStatus_NotAvailable" 2 "ButtonStatus_Error" 1 "ButtonStatus_Pressed" 0 "ButtonStatus_Idle" ;
VAL_ 2365554559 WRCLevelAdjustmentAction 15 "LevelAdjustmentAction_NotAvailable" 14 "LevelAdjustmentAction_Error" 13 "LevelAdjustmentAction_Reserved_06" 12 "LevelAdjustmentAction_Reserved_05" 11 "LevelAdjustmentAction_Reserved_04" 10 "LevelAdjustmentAction_Reserved_03" 9 "LevelAdjustmentAction_Reserved_02" 8 "LevelAdjustmentAction_Ferry" 7 "LevelAdjustmentAction_Reserved_01" 6 "LevelAdjustmentAction_GotoDriveLevel" 5 "LevelAdjustmentAction_Reserved" 4 "LevelAdjustmentAction_DownShortMovement" 3 "LevelAdjustmentAction_UpShortMovement" 2 "LevelAdjustmentAction_DownBasic" 1 "LevelAdjustmentAction_UpBasic" 0 "LevelAdjustmentAction_Idle" ;
VAL_ 2365554559 WRCAux4Request 3 "OffOn_NotAvailable" 2 "OffOn_Error" 1 "OffOn_On" 0 "OffOn_Off" ;
VAL_ 2365554559 WRCAux5Request 3 "OffOn_NotAvailable" 2 "OffOn_Error" 1 "OffOn_On" 0 "OffOn_Off" ;
VAL_ 2365554559 WRCAux6Request 3 "OffOn_NotAvailable" 2 "OffOn_Error" 1 "OffOn_On" 0 "OffOn_Off" ;
VAL_ 2365554559 WRCSideReverseWorkingRequest 3 "PushButtonStatus_NotAvailable" 2 "PushButtonStatus_Error" 1 "PushButtonStatus_Pushed" 0 "PushButtonStatus_Neutral" ;
VAL_ 2365554559 WrcPto2ButtonStatus 3 "ButtonStatus_NotAvailable" 2 "ButtonStatus_Error" 1 "ButtonStatus_Pressed" 0 "ButtonStatus_Idle" ;
VAL_ 2365554559 WRCTailLiftRequest 3 "PushButtonStatus_NotAvailable" 2 "PushButtonStatus_Error" 1 "PushButtonStatus_Pushed" 0 "PushButtonStatus_Neutral" ;
VAL_ 2365554559 WrcPto4ButtonStatus 3 "ButtonStatus_NotAvailable" 2 "ButtonStatus_Error" 1 "ButtonStatus_Pressed" 0 "ButtonStatus_Idle" ;
VAL_ 2365554559 WRCLevelAdjustmentStroke 7 "LevelAdjustmentStroke_NotAvailable" 6 "LevelAdjustmentStroke_Error" 5 "LevelAdjustmentStroke_Reserved_03" 4 "LevelAdjustmentStroke_Reserved_02" 3 "LevelAdjustmentStroke_Reserved_01" 2 "LevelAdjustmentStroke_Reserved" 1 "LevelAdjustmentStroke_DockingStroke" 0 "LevelAdjustmentStroke_DriveStroke" ;
VAL_ 2365554559 WRCLevelAdjustmentAxles 7 "LevelAdjustmentAxles_NotAvailable" 6 "LevelAdjustmentAxles_Error" 5 "LevelAdjustmentAxles_Reserved_02" 4 "LevelAdjustmentAxles_Reserved_01" 3 "LevelAdjustmentAxles_Reserved" 2 "LevelAdjustmentAxles_Parallel" 1 "LevelAdjustmentAxles_Front" 0 "LevelAdjustmentAxles_Rear" ;
VAL_ 2365554559 WRCAirSuspensionStopRequest 3 "FalseTrue_NotAvaiable" 2 "FalseTrue_Error" 1 "FalseTrue_True" 0 "FalseTrue_False" ;
VAL_ 2365554559 WRCAux1Request 3 "OffOn_NotAvailable" 2 "OffOn_Error" 1 "OffOn_On" 0 "OffOn_Off" ;
VAL_ 2365554559 WRCLockButtonStatus 3 "PushButtonStatus_NotAvailable" 2 "PushButtonStatus_Error" 1 "PushButtonStatus_Pushed" 0 "PushButtonStatus_Neutral" ;
VAL_ 2432689491 SRSAirbagStatus_ISig_5 3 "SRSAirbagStatus_NotAvailable" 2 "SRSAirbagStatus_ErrorIndicator" 1 "SRSAirbagStatus_DriverAirbagDeployed" 0 "SRSAirbagStatus_NoAirbagDeployed" ;
VAL_ 2432689491 TrafficAccidentHazardLightRqst_I 3 "Request_NotAvailable" 2 "Request_Error" 1 "Request_RequestActive" 0 "Request_NotRequested" ;
VAL_ 2432689491 FrontalCollisionAccidentStatus_I 3 "NotDetected_NotAvaliable" 2 "NotDetected_Error" 1 "NotDetected_Detected" 0 "NotDetected_NotDetected" ;
VAL_ 2432689491 EmergencyDoorsUnlock_rqst 7 "EmergencyDoorsUnlock_rqst_NotAvailable" 6 "EmergencyDoorsUnlock_rqst_Error" 2 "EmergencyDoorsUnlock_rqst_EmergencyUnlockRequest" 1 "EmergencyDoorsUnlock_rqst_Spare" 0 "EmergencyDoorsUnlock_rqst_Idle" ;
VAL_ 2432689491 RollOverAccidentStatus_ISig_5 3 "RollOverAccidentStatus_NotAvailable" 2 "RollOverAccidentStatus_Error" 1 "RollOverAccidentStatus_RollOverAccidentDetected" 0 "RollOverAccidentStatus_NoRollOverAccidentDetected" ;
VAL_ 2499772322 MediaSourcesListReq_SInfo_ISig_5 3 "SignalInfo2bitType_NotAvailable" 2 "SignalInfo2bitType_ErrorIndication" 1 "SignalInfo2bitType_Spare" 0 "SignalInfo2bitType_Valid" ;
VAL_ 2489730210 BunkH1AudioSrcSem_rqst_ISig_5 15 "AudioSource_NotAvailable" 14 "AudioSource_Error" 13 "AudioSource_Source13" 12 "AudioSource_Source12" 11 "AudioSource_Source11" 10 "AudioSource_Source10" 9 "AudioSource_Source09" 8 "AudioSource_Source08" 7 "AudioSource_Source07" 6 "AudioSource_Source06" 5 "AudioSource_Source05" 4 "AudioSource_Source04" 3 "AudioSource_Source03" 2 "AudioSource_Source02" 1 "AudioSource_Source01" 0 "AudioSource_Source00" ;
VAL_ 2566043647 AlmClkSetAlm_LECM_rq_Type_ISig_5 7 "AlarmClkType_NotAvailable" 6 "AlarmClkType_Error" 5 "AlarmClkType_Reserved_02" 4 "AlarmClkType_Reserved_01" 3 "AlarmClkType_Reserved" 2 "AlarmClkType_Radio" 1 "AlarmClkType_Buzzer" 0 "AlarmClkType_NoAudibleNotification" ;
VAL_ 2566043647 AlmClkSnze_LECM_rqst_ID_ISig_5 127 "AlarmClkID_NotAvailable" 126 "AlarmClkID_Error" 10 "AlarmClkID_Alarm10" 9 "AlarmClkID_Alarm9" 8 "AlarmClkID_Alarm8" 7 "AlarmClkID_Alarm7" 6 "AlarmClkID_Alarm6" 5 "AlarmClkID_Alarm5" 4 "AlarmClkID_Alarm4" 3 "AlarmClkID_Alarm3" 2 "AlarmClkID_Alarm2" 1 "AlarmClkID_Alarm1" 0 "AlarmClkID_NotUsed" ;
VAL_ 2566043647 AlmClkSetAlm_LECM_rq_Mode_ISig_5 3 "AlarmClkMode_Spare" 2 "AlarmClkMode_Timer" 1 "AlarmClkMode_Recurrent" 0 "AlarmClkMode_OneTime" ;
VAL_ 2566043647 AlmClkSetAlm_LECM_rq_Stat_ISig_5 3 "AlarmClkStat2_Snoozed" 2 "AlarmClkStat2_Ringing" 1 "AlarmClkStat2_Active" 0 "AlarmClkStat2_Inactive" ;
VAL_ 2566043647 AlmClkSetAlm_LECM_rq_ID_ISig_5 127 "AlarmClkID_NotAvailable" 126 "AlarmClkID_Error" 10 "AlarmClkID_Alarm10" 9 "AlarmClkID_Alarm9" 8 "AlarmClkID_Alarm8" 7 "AlarmClkID_Alarm7" 6 "AlarmClkID_Alarm6" 5 "AlarmClkID_Alarm5" 4 "AlarmClkID_Alarm4" 3 "AlarmClkID_Alarm3" 2 "AlarmClkID_Alarm2" 1 "AlarmClkID_Alarm1" 0 "AlarmClkID_NotUsed" ;
VAL_ 2566043647 AlmClkSnze_LECM_rqst_Action_ISig 7 "AlmClkSnzeAction_NotAvailable" 6 "AlmClkSnzeAction_Error" 5 "AlmClkSnzeAction_Spare02" 4 "AlmClkSnzeAction_Spare01" 3 "AlmClkSnzeAction_Spare" 2 "AlmClkSnzeAction_RequestToTurnAlarmOff" 1 "AlmClkSnzeAction_RequestToSnoozeAlarm" 0 "AlmClkSnzeAction_NoRequest" ;
VAL_ 2432693154 BunkH1RoofhatchOpenBtn_Stat 3 "PushButtonStatus_NotAvailable" 2 "PushButtonStatus_Error" 1 "PushButtonStatus_Pushed" 0 "PushButtonStatus_Neutral" ;
VAL_ 2432693154 BunkH1IntLghtActvnBtn_stat 3 "PushButtonStatus_NotAvailable" 2 "PushButtonStatus_Error" 1 "PushButtonStatus_Pushed" 0 "PushButtonStatus_Neutral" ;
VAL_ 2432693154 BunkH1TempDec_ButtonStatus 3 "PushButtonStatus_NotAvailable" 2 "PushButtonStatus_Error" 1 "PushButtonStatus_Pushed" 0 "PushButtonStatus_Neutral" ;
VAL_ 2432693154 BunkH1IntLghtDirAccsUpBtn_stat 3 "PushButtonStatus_NotAvailable" 2 "PushButtonStatus_Error" 1 "PushButtonStatus_Pushed" 0 "PushButtonStatus_Neutral" ;
VAL_ 2432693154 BunkH1AudioSource_rqst2_ISig_5 15 "AudioSource_rqst4bit_NotAvailable" 14 "AudioSource_rqst4bit_Error" 13 "AudioSource_rqst4bit_Spare7" 12 "AudioSource_rqst4bit_Spare6" 11 "AudioSource_rqst4bit_Spare5" 10 "AudioSource_rqst4bit_Spare4" 9 "AudioSource_rqst4bit_Spare3" 8 "AudioSource_rqst4bit_Spare2" 7 "AudioSource_rqst4bit_Spare1" 6 "AudioSource_rqst4bit_BtStream" 5 "AudioSource_rqst4bit_AUX1" 4 "AudioSource_rqst4bit_IPOD" 3 "AudioSource_rqst4bit_AUX2" 2 "AudioSource_rqst4bit_USB" 1 "AudioSource_rqst4bit_CD" 0 "AudioSource_rqst4bit_Radio" ;
VAL_ 2432693154 BunkH1AudioOnOff_ButtonStatus_IS 3 "PushButtonStatus_NotAvailable" 2 "PushButtonStatus_Error" 1 "PushButtonStatus_Pushed" 0 "PushButtonStatus_Neutral" ;
VAL_ 2432693154 BunkH1RoofhatchCloseBtn_Stat 3 "PushButtonStatus_NotAvailable" 2 "PushButtonStatus_Error" 1 "PushButtonStatus_Pushed" 0 "PushButtonStatus_Neutral" ;
VAL_ 2432693154 BunkH1VolumeUp_ButtonStatus_ISig 3 "PushButtonStatus_NotAvailable" 2 "PushButtonStatus_Error" 1 "PushButtonStatus_Pushed" 0 "PushButtonStatus_Neutral" ;
VAL_ 2432693154 BunkH1PowerWinCloseDSBtn_stat_IS 3 "PushButtonStatus_NotAvailable" 2 "PushButtonStatus_Error" 1 "PushButtonStatus_Pushed" 0 "PushButtonStatus_Neutral" ;
VAL_ 2432693154 BunkH1Prev_ButtonStatus_ISig_5 3 "PushButtonStatus_NotAvailable" 2 "PushButtonStatus_Error" 1 "PushButtonStatus_Pushed" 0 "PushButtonStatus_Neutral" ;
VAL_ 2432693154 BunkH1UnlockButtonStatus 3 "PushButtonStatus_NotAvailable" 2 "PushButtonStatus_Error" 1 "PushButtonStatus_Pushed" 0 "PushButtonStatus_Neutral" ;
VAL_ 2432693154 BunkH1VolumeDown_ButtonStatus_IS 3 "PushButtonStatus_NotAvailable" 2 "PushButtonStatus_Error" 1 "PushButtonStatus_Pushed" 0 "PushButtonStatus_Neutral" ;
VAL_ 2432693154 BunkH1ParkHeaterTimer2_cmd 7 "ParkHeaterTimer_cmd_NotAvailable" 6 "ParkHeaterTimer_cmd_Error" 5 "ParkHeaterTimer_cmd_Spare_02" 4 "ParkHeaterTimer_cmd_Spare_01" 3 "ParkHeaterTimer_cmd_Spare" 2 "ParkHeaterTimer_cmd_TimerDisable" 1 "ParkHeaterTimer_cmd_TimerEnable" 0 "ParkHeaterTimer_cmd_NoAction" ;
VAL_ 2432693154 BunkH1PowerWinOpenDSBtn_stat_ISi 3 "PushButtonStatus_NotAvailable" 2 "PushButtonStatus_Error" 1 "PushButtonStatus_Pushed" 0 "PushButtonStatus_Neutral" ;
VAL_ 2432693154 BunkH1ParkHeater_ButtonStatus 3 "PushButtonStatus_NotAvailable" 2 "PushButtonStatus_Error" 1 "PushButtonStatus_Pushed" 0 "PushButtonStatus_Neutral" ;
VAL_ 2432693154 BunkH1ParkHeaterTimer3_cmd 7 "ParkHeaterTimer_cmd_NotAvailable" 6 "ParkHeaterTimer_cmd_Error" 5 "ParkHeaterTimer_cmd_Spare_02" 4 "ParkHeaterTimer_cmd_Spare_01" 3 "ParkHeaterTimer_cmd_Spare" 2 "ParkHeaterTimer_cmd_TimerDisable" 1 "ParkHeaterTimer_cmd_TimerEnable" 0 "ParkHeaterTimer_cmd_NoAction" ;
VAL_ 2432693154 BunkH1AudioSource_rqst_ISig_5 7 "BunkH1AudioSource_rqst_NotAvailable" 6 "BunkH1AudioSource_rqst_Error" 5 "BunkH1AudioSource_rqst_AUX1" 4 "BunkH1AudioSource_rqst_iPod" 3 "BunkH1AudioSource_rqst_AUX2" 2 "BunkH1AudioSource_rqst_USB" 1 "BunkH1AudioSource_rqst_CD" 0 "BunkH1AudioSource_rqst_Radio" ;
VAL_ 2432693154 BunkH1Mute_ButtonStatus_ISig_5 3 "PushButtonStatus_NotAvailable" 2 "PushButtonStatus_Error" 1 "PushButtonStatus_Pushed" 0 "PushButtonStatus_Neutral" ;
VAL_ 2432693154 BunkH1IntLghtDirAccsDnBtn_stat 3 "PushButtonStatus_NotAvailable" 2 "PushButtonStatus_Error" 1 "PushButtonStatus_Pushed" 0 "PushButtonStatus_Neutral" ;
VAL_ 2432693154 BunkH1LockButtonStatus 3 "PushButtonStatus_NotAvailable" 2 "PushButtonStatus_Error" 1 "PushButtonStatus_Pushed" 0 "PushButtonStatus_Neutral" ;
VAL_ 2432693154 BunkH1ParkHeaterTimer1_cmd 7 "ParkHeaterTimer_cmd_NotAvailable" 6 "ParkHeaterTimer_cmd_Error" 5 "ParkHeaterTimer_cmd_Spare_02" 4 "ParkHeaterTimer_cmd_Spare_01" 3 "ParkHeaterTimer_cmd_Spare" 2 "ParkHeaterTimer_cmd_TimerDisable" 1 "ParkHeaterTimer_cmd_TimerEnable" 0 "ParkHeaterTimer_cmd_NoAction" ;
VAL_ 2432693154 BnkH1IntLghtMMenu_stat_IL_Mode 7 "IL_Mode_NotAvailable" 6 "IL_Mode_ErrorIndicator" 5 "IL_Mode_spare_2" 4 "IL_Mode_spare_1" 3 "IL_Mode_Max" 2 "IL_Mode_Resting" 1 "IL_Mode_NightDriving" 0 "IL_Mode_OFF" ;
VAL_ 2432693154 BunkH1Next_ButtonStatus_ISig_5 3 "PushButtonStatus_NotAvailable" 2 "PushButtonStatus_Error" 1 "PushButtonStatus_Pushed" 0 "PushButtonStatus_Neutral" ;
VAL_ 2432693154 BnkH1IntLghtMMenu_stat_EventFlag 1 "EventFlag_High" 0 "EventFlag_Low" ;
VAL_ 2432693154 BunkH1PowerWinOpenPSBtn_stat_ISi 3 "PushButtonStatus_NotAvailable" 2 "PushButtonStatus_Error" 1 "PushButtonStatus_Pushed" 0 "PushButtonStatus_Neutral" ;
VAL_ 2432693154 BunkH1PowerWinClosePSBtn_stat_IS 3 "PushButtonStatus_NotAvailable" 2 "PushButtonStatus_Error" 1 "PushButtonStatus_Pushed" 0 "PushButtonStatus_Neutral" ;
VAL_ 2432693154 BunkH1TempInc_ButtonStatus 3 "PushButtonStatus_NotAvailable" 2 "PushButtonStatus_Error" 1 "PushButtonStatus_Pushed" 0 "PushButtonStatus_Neutral" ;
VAL_ 2566357312 GPSData_AntennaStat_ISig_5 7 "GPS_Antenna_status_NA" 6 "GPS_Antenna_status_ErrorIndicator" 5 "GPS_Antenna_status_SpareValue_01" 4 "GPS_Antenna_status_SpareValue" 3 "GPS_Antenna_status_AntennaStatusUnknown" 2 "GPS_Antenna_status_AntennaInit" 1 "GPS_Antenna_status_AntennaDisconnected" 0 "GPS_Antenna_status_AntennaStatusOK" ;
VAL_ 2432647232 CM_Status_ISig_5 7 "CM_Status_NotAvailable" 6 "CM_Status_ErrorIndicator" 5 "CM_Status_CM_DisabledBySystem" 4 "CM_Status_CM_MitigationBrakingFinished" 3 "CM_Status_CM_MitigationBraking" 2 "CM_Status_CM_PreMitigationBraking" 1 "CM_Status_CM_Enabled" 0 "CM_Status_CM_Disabled" ;
VAL_ 2516193600 ROPBrakeControlActive_ISig_5 3 "PassiveActive2_DontCareTakeNoAction" 2 "PassiveActive2_Reserved" 1 "PassiveActive2_Active" 0 "PassiveActive2_PassiveButInstalled" ;
VAL_ 2516193600 FoundationBrakeUse_ISig_5 3 "FoundationBrakeUse_NotAvailable" 2 "FoundationBrakeUse_Reserved" 1 "FoundationBrakeUse_FoundationBrakesInUse" 0 "FoundationBrakeUse_FoundationBrakesNotInUse" ;
VAL_ 2516193600 YCBrakeControlActive_ISig_5 3 "PassiveActive2_DontCareTakeNoAction" 2 "PassiveActive2_Reserved" 1 "PassiveActive2_Active" 0 "PassiveActive2_PassiveButInstalled" ;
VAL_ 2516193600 AntiLockBrakingActive_ISig_5 3 "AntiLockBrakingActive_NotAvailable" 2 "AntiLockBrakingActive_Reserved" 1 "AntiLockBrakingActive_ABSActive" 0 "AntiLockBrakingActive_ABSPassiveButInstalled" ;
VAL_ 2432679744 MediaSourcesListRsp_SInfo_ISig_5 3 "SignalInfo2bitType_NotAvailable" 2 "SignalInfo2bitType_ErrorIndication" 1 "SignalInfo2bitType_Spare" 0 "SignalInfo2bitType_Valid" ;
VAL_ 2493989952 SEMMediaSourceAvail_Source07_ISi 1 "Bitfield1BitType_True" 0 "Bitfield1BitType_False" ;
VAL_ 2493989952 SEMMediaSourceAvail_Source06_ISi 1 "Bitfield1BitType_True" 0 "Bitfield1BitType_False" ;
VAL_ 2493989952 SEMMediaSourceAvail_Source08_ISi 1 "Bitfield1BitType_True" 0 "Bitfield1BitType_False" ;
VAL_ 2493989952 SEMMediaSourceAvail_Source00_ISi 1 "Bitfield1BitType_True" 0 "Bitfield1BitType_False" ;
VAL_ 2493989952 SEM_AudioMuteStat_ISig_5 7 "AudioMute_NotAvailable" 6 "AudioMute_ErrorIndication" 5 "AudioMute_Spare_03" 4 "AudioMute_Spare_02" 3 "AudioMute_Spare_01" 2 "AudioMute_Spare" 1 "AudioMute_Mute" 0 "AudioMute_Off" ;
VAL_ 2493989952 SEMMediaSourceAvail_Source09_ISi 1 "Bitfield1BitType_True" 0 "Bitfield1BitType_False" ;
VAL_ 2493989952 SEMMediaSourceAvail_Source13_ISi 1 "Bitfield1BitType_True" 0 "Bitfield1BitType_False" ;
VAL_ 2493989952 SEMMediaSourceAvail_Source04_ISi 1 "Bitfield1BitType_True" 0 "Bitfield1BitType_False" ;
VAL_ 2493989952 SEMMediaSourceAvail_Source05_ISi 1 "Bitfield1BitType_True" 0 "Bitfield1BitType_False" ;
VAL_ 2493989952 SEMMediaSourceAvail_Source02_ISi 1 "Bitfield1BitType_True" 0 "Bitfield1BitType_False" ;
VAL_ 2493989952 SEMMediaSourceAvail_SInfo_ISig_5 3 "SignalInfo2bitType_NotAvailable" 2 "SignalInfo2bitType_ErrorIndication" 1 "SignalInfo2bitType_Spare" 0 "SignalInfo2bitType_Valid" ;
VAL_ 2493989952 AudioSourceStat_ISig_5 15 "AudioSource_NotAvailable" 14 "AudioSource_Error" 13 "AudioSource_Source13" 12 "AudioSource_Source12" 11 "AudioSource_Source11" 10 "AudioSource_Source10" 9 "AudioSource_Source09" 8 "AudioSource_Source08" 7 "AudioSource_Source07" 6 "AudioSource_Source06" 5 "AudioSource_Source05" 4 "AudioSource_Source04" 3 "AudioSource_Source03" 2 "AudioSource_Source02" 1 "AudioSource_Source01" 0 "AudioSource_Source00" ;
VAL_ 2493989952 SEMMediaSourceAvail_Source11_ISi 1 "Bitfield1BitType_True" 0 "Bitfield1BitType_False" ;
VAL_ 2493989952 SEMMediaSourceAvail_Source10_ISi 1 "Bitfield1BitType_True" 0 "Bitfield1BitType_False" ;
VAL_ 2493989952 SEMMediaSourceAvail_Source01_ISi 1 "Bitfield1BitType_True" 0 "Bitfield1BitType_False" ;
VAL_ 2493989952 SEMMediaSourceAvail_Source03_ISi 1 "Bitfield1BitType_True" 0 "Bitfield1BitType_False" ;
VAL_ 2493989952 SEMMediaSourceAvail_Source12_ISi 1 "Bitfield1BitType_True" 0 "Bitfield1BitType_False" ;
VAL_ 2499754560 TipperEmergencyStopStatus_ISig_5 7 "TipperEmergencyStopStatus_NotAvailable" 6 "TipperEmergencyStopStatus_Error" 5 "TipperEmergencyStopStatus_Spare2" 4 "TipperEmergencyStopStatus_Spare1" 3 "TipperEmergencyStopStatus_RemoteAndChassis" 2 "TipperEmergencyStopStatus_ChassisOnly" 1 "TipperEmergencyStopStatus_RemoteOnly" 0 "TipperEmergencyStopStatus_None" ;
VAL_ 2499754560 TipperPrimaryBodyStatus_ISig_5 7 "TipperBodyStatus_NotAvailable" 6 "TipperBodyStatus_Error" 5 "TipperBodyStatus_Spare3" 4 "TipperBodyStatus_Spare2" 3 "TipperBodyStatus_Spare1" 2 "TipperBodyStatus_NotPresent" 1 "TipperBodyStatus_Unavailable" 0 "TipperBodyStatus_Available" ;
VAL_ 2499754560 TipperConditionsStatus_ISig_5 3 "NotFulfilledFulfilled_NotAvailable" 2 "NotFulfilledFulfilled_Error" 1 "NotFulfilledFulfilled_Fulfilled" 0 "NotFulfilledFulfilled_NotFulfilled" ;
VAL_ 2499754560 TipperSecondaryBodyStatus_ISig_5 7 "TipperBodyStatus_NotAvailable" 6 "TipperBodyStatus_Error" 5 "TipperBodyStatus_Spare3" 4 "TipperBodyStatus_Spare2" 3 "TipperBodyStatus_Spare1" 2 "TipperBodyStatus_NotPresent" 1 "TipperBodyStatus_Unavailable" 0 "TipperBodyStatus_Available" ;
VAL_ 2499754560 BatterySOCAlert_rqst_ISig_5 7 "BatterySOCAlert_rqst_NotAvailable" 6 "BatterySOCAlert_rqst_ErrorIndicator" 5 "BatterySOCAlert_rqst_SpareValue_02" 4 "BatterySOCAlert_rqst_SpareValue_01" 3 "BatterySOCAlert_rqst_SpareValue" 2 "BatterySOCAlert_rqst_CriticalAlert" 1 "BatterySOCAlert_rqst_PreAlert" 0 "BatterySOCAlert_rqst_NoAlertRequested" ;
VAL_ 2499754560 CCStates_ISig_5 15 "CCStates_NotAvailable" 14 "CCStates_Error" 13 "CCStates_Spare_7" 12 "CCStates_Spare_6" 11 "CCStates_Spare_5" 10 "CCStates_Spare_4" 9 "CCStates_Spare_3" 8 "CCStates_Spare_2" 7 "CCStates_Spare_1" 6 "CCStates_Driver_Override" 5 "CCStates_Set" 4 "CCStates_Resume" 3 "CCStates_Decelerate" 2 "CCStates_Accelerate" 1 "CCStates_Hold" 0 "CCStates_OffDisabled" ;
VAL_ 2499754560 LongMotionDirection_ISig_5 7 "LongMotionDirection_NotAvailable" 6 "LongMotionDirection_Error" 5 "LongMotionDirection_Spare3" 4 "LongMotionDirection_Spare2" 3 "LongMotionDirection_Undetermined" 2 "LongMotionDirection_Backward" 1 "LongMotionDirection_Forward" 0 "LongMotionDirection_Stationary" ;
VAL_ 2499754560 TipperUpDownStatus_ISig_5 7 "UpDownStatus_NotAvailable" 6 "UpDownStatus_Error" 5 "UpDownStatus_Spare2" 4 "UpDownStatus_Spare1" 3 "UpDownStatus_AutoLowering" 2 "UpDownStatus_Lowering" 1 "UpDownStatus_Raising" 0 "UpDownStatus_Inactive" ;
VAL_ 2499754560 TipperTailGateStatus_ISig_5 7 "GateStatus_NotAvailable" 6 "GateStatus_Error" 5 "GateStatus_Spare3" 4 "GateStatus_Spare2" 3 "GateStatus_Spare1" 2 "GateStatus_Closing" 1 "GateStatus_Opening" 0 "GateStatus_Inactive" ;
VAL_ 2499754560 KneelingInformation_ISig_5 15 "KneelingInformation_NotAvailable" 14 "KneelingInformation_ErrorIndicator" 13 "KneelingInformation_NotDefined_08" 12 "KneelingInformation_NotDefined_07" 11 "KneelingInformation_NotDefined_06" 10 "KneelingInformation_NotDefined_05" 9 "KneelingInformation_NotDefined_04" 8 "KneelingInformation_NotDefined_03" 7 "KneelingInformation_NotDefined_02" 6 "KneelingInformation_NotDefined_01" 5 "KneelingInformation_NotDefined" 4 "KneelingInformation_KneelingAborted" 3 "KneelingInformation_LiftingActiveVehicleIsLiftedDueToRcvrReq" 2 "KneelingInformation_KneelLevelReachedVehicleIsAtFixeKneelLvl" 1 "KneelingInformation_LoweringActiveTheVehIsLoweredDueToKneelReq" 0 "KneelingInformation_NotActiveTheKneelingFunctionIsNotActive" ;
VAL_ 2499754560 TailLiftRemoteNotAllowed_ISig_5 3 "NotAllowedAllowed_NotAvailable" 2 "NotAllowedAllowed_Error" 1 "NotAllowedAllowed_Allowed" 0 "NotAllowedAllowed_NotAllowed" ;
VAL_ 2499754560 TipperTarpaulinStatus_ISig_5 7 "TarpaulinStatus_NotAvailable" 6 "TarpaulinStatus_Error" 5 "TarpaulinStatus_Spare3" 4 "TarpaulinStatus_Spare2" 3 "TarpaulinStatus_Spare1" 2 "TarpaulinStatus_Uncovering" 1 "TarpaulinStatus_Covering" 0 "TarpaulinStatus_Inactive" ;
VAL_ 2499754560 TailLiftConditionsStatus_ISig_5 3 "NotFulfilledFulfilled_NotAvailable" 2 "NotFulfilledFulfilled_Error" 1 "NotFulfilledFulfilled_Fulfilled" 0 "NotFulfilledFulfilled_NotFulfilled" ;
VAL_ 2499754560 InhibitWRCECSMenuCmd 3 "InactiveActive_NotAvailable" 2 "InactiveActive_Error" 1 "InactiveActive_Active" 0 "InactiveActive_Inactive" ;
VAL_ 2499754560 ExtraHeating_rqst_ISig_5 7 "ActivationRequest_NotAvailable" 6 "ActivationRequest_Error" 5 "ActivationRequest_Spare3" 4 "ActivationRequest_Spare2" 3 "ActivationRequest_Spare1" 2 "ActivationRequest_AutoStart" 1 "ActivationRequest_Off" 0 "ActivationRequest_NoAction" ;
VAL_ 2499754560 ShortStopHeater_status_ISig_5 7 "ShortStopHeaterStatus_NotAvailable" 6 "ShortStopHeaterStatus_Error" 5 "ShortStopHeaterStatus_Spare3" 4 "ShortStopHeaterStatus_Spare2" 3 "ShortStopHeaterStatus_Spare1" 2 "ShortStopHeaterStatus_ActivatedAndPumpNotEngaged" 1 "ShortStopHeaterStatus_ActivatedAndPumpEngaged" 0 "ShortStopHeaterStatus_NotActivated" ;
VAL_ 2499754560 LongMotionDirectionQual_ISig_5 3 "LongMotionDirectionQual_NotAvailable" 2 "LongMotionDirectionQual_OEM_Reserved2" 1 "LongMotionDirectionQual_OEM_Reserved1" 0 "LongMotionDirectionQual_UsingGearbox" ;
VAL_ 2499754560 TipperShakerStatus_ISig_5 3 "ShakerStatus_NotAvailable" 2 "ShakerStatus_Error" 1 "ShakerStatus_Shaking" 0 "ShakerStatus_Inactive" ;
VAL_ 2499754560 TailLiftMotionStatus_ISig_5 7 "RqstTiltUpDown_NotAvailable" 6 "RqstTiltUpDown_Error" 5 "RqstTiltUpDown_Spare" 4 "RqstTiltUpDown_TiltDown" 3 "RqstTiltUpDown_TiltUp" 2 "RqstTiltUpDown_RequestDown" 1 "RqstTiltUpDown_RequestUp" 0 "RqstTiltUpDown_NoRequest" ;
SIG_GROUP_ 2566826323 SRS2_SN_sg 1 : SRS2_SN_Byte2 SRS2_SN_Byte1 SRS2_SN_Byte0 SRS2_SN_Byte3;
SIG_GROUP_ 2566825811 SRS2_SNPN_sg 1 : SRS2_SNPN_Byte2 SRS2_SNPN_Byte3 SRS2_SNPN_Byte1 SRS2_SNPN_Byte0 SRS2_SNPN_Byte4;
SIG_GROUP_ 2499772322 MediaSourcesListReq_sg_ISig_5 1 : MediaSourcesListReq_SInfo_ISig_5 MediaSourcesListReq_Items_ISig_5 MediaSourcesListReq_ItemID_ISig_;
SIG_GROUP_ 2566043647 AlmClkSetAlm_LECM_rq_sg_ISig_5 1 : AlmClkSetAlm_LECM_rq_Type_ISig_5 AlmClkSetAlm_LECM_rq_SetHr_ISig_ AlmClkSetAlm_LECM_rq_DaySet_ISig AlmClkSetAlm_LECM_rq_Mode_ISig_5 AlmClkSetAlm_LECM_rq_Stat_ISig_5 AlmClkSetAlm_LECM_rq_SetMin_ISig AlmClkSetAlm_LECM_rq_ID_ISig_5;
SIG_GROUP_ 2566043647 AlmClkSnze_LECM_rqst_sg_ISig_5 1 : AlmClkSnze_LECM_rqst_ID_ISig_5 AlmClkSnze_LECM_rqst_Action_ISig;
SIG_GROUP_ 2432693154 BnkH1IntLghtMMenu_stat_sg 1 : BnkH1IntLghtMMenu_stat_IL_Mode BnkH1IntLghtMMenu_stat_EventFlag;
SIG_GROUP_ 2567057439 DiagFaultStat_WRCS_sg_ISig_5 1 : DiagFaultStat_WRCS_FailTA_ISig_5 DiagFaultStat_WRCS_DtcIdB_ISig_5 DiagFaultStat_WRCS_FailTB_ISig_5 DiagFaultStat_WRCS_EcuAdr_ISig_5 DiagFaultStat_WRCS_DtcIdA_ISig_5;
SIG_GROUP_ 2567057438 DiagFaultStat_SRS_sg_ISig_5 1 : DiagFaultStat_SRS_DtcIdA_ISig_5 DiagFaultStat_SRS_FailTA_ISig_5 DiagFaultStat_SRS_FailTB_ISig_5 DiagFaultStat_SRS_DtcIdB_ISig_5 DiagFaultStat_SRS_EcuAdr_ISig_5;
SIG_GROUP_ 2567057437 DiagFaultStat_LECM_sg_ISig_5 1 : DiagFaultStat_LECM_DtcIdA_ISig_5 DiagFaultStat_LECM_FailTA_ISig_5 DiagFaultStat_LECM_FailTB_ISig_5 DiagFaultStat_LECM_DtcIdB_ISig_5 DiagFaultStat_LECM_EcuAdr_ISig_5;
SIG_GROUP_ 2567057436 DiagFaultStat_CCM_sg_ISig_5 1 : DiagFaultStat_CCM_FailTB_ISig_5 DiagFaultStat_CCM_DtcIdB_ISig_5 DiagFaultStat_CCM_EcuAdr_ISig_5 DiagFaultStat_CCM_DtcIdA_ISig_5 DiagFaultStat_CCM_FailTA_ISig_5;
SIG_GROUP_ 2566357312 GPSData_sg_ISig_5 1 : GPSData_VehSpeed_ISig_5 GPSData_HDOP_ISig_5 GPSData_Direction_ISig_5 GPSData_Longitude_ISig_5 GPSData_AntennaStat_ISig_5 GPSData_Latitude_ISig_5 GPSData_Altitude_ISig_5 GPSData_Time_ISig_5;
SIG_GROUP_ 2432679744 MediaSourcesListRsp_sg_ISig_5 1 : MediaSourcesListRsp_SrcAttrib_IS MediaSourcesListRsp_ItemID_ISig_ MediaSourcesListRsp_Name_ISig_5 MediaSourcesListRsp_SInfo_ISig_5 MediaSourcesListRsp_PCI_ISig_5;
SIG_GROUP_ 2493989952 SEMMediaSourceAvail_sg_ISig_5 1 : SEMMediaSourceAvail_Source07_ISi SEMMediaSourceAvail_Source06_ISi SEMMediaSourceAvail_Source08_ISi SEMMediaSourceAvail_Source00_ISi SEMMediaSourceAvail_Source09_ISi SEMMediaSourceAvail_Source13_ISi SEMMediaSourceAvail_Source04_ISi SEMMediaSourceAvail_Source05_ISi SEMMediaSourceAvail_Source02_ISi SEMMediaSourceAvail_SInfo_ISig_5 SEMMediaSourceAvail_Source11_ISi SEMMediaSourceAvail_Source10_ISi SEMMediaSourceAvail_Source01_ISi SEMMediaSourceAvail_Source03_ISi SEMMediaSourceAvail_Source12_ISi;
